VERSION ""

NS_ :

BS_:

BU_: External_Tool CADM LRRF MRRRL MRRRR

BO_ 1283 MRR_RL_Detection_022_028: 64 MRRRL
 SG_ MRR_RL_CAN_DET_MID_TARGET_028 : 462|1@0+ (1,0) [0|1] ""  CADM
 SG_ MRR_RL_CAN_DET_MID_TARGET_027 : 461|1@0+ (1,0) [0|1] ""  CADM
 SG_ MRR_RL_CAN_DET_MID_TARGET_026 : 460|1@0+ (1,0) [0|1] ""  CADM
 SG_ MRR_RL_CAN_DET_MID_TARGET_025 : 459|1@0+ (1,0) [0|1] ""  CADM
 SG_ MRR_RL_CAN_DET_MID_TARGET_024 : 458|1@0+ (1,0) [0|1] ""  CADM
 SG_ MRR_RL_CAN_DET_MID_TARGET_023 : 457|1@0+ (1,0) [0|1] ""  CADM
 SG_ MRR_RL_CAN_DET_MID_TARGET_022 : 456|1@0+ (1,0) [0|1] ""  CADM
 SG_ MRR_RL_CAN_DET_Near_TARGET_022 : 448|1@0+ (1,0) [0|1] ""  CADM
 SG_ MRR_RL_CAN_DET_Near_TARGET_023 : 449|1@0+ (1,0) [0|1] ""  CADM
 SG_ MRR_RL_CAN_DET_Near_TARGET_024 : 450|1@0+ (1,0) [0|1] ""  CADM
 SG_ MRR_RL_CAN_DET_Near_TARGET_025 : 451|1@0+ (1,0) [0|1] ""  CADM
 SG_ MRR_RL_CAN_DET_Near_TARGET_026 : 452|1@0+ (1,0) [0|1] ""  CADM
 SG_ MRR_RL_CAN_DET_Near_TARGET_027 : 453|1@0+ (1,0) [0|1] ""  CADM
 SG_ MRR_RL_CAN_DET_Near_TARGET_028 : 454|1@0+ (1,0) [0|1] ""  CADM
 SG_ MRR_RL_DET_CRC_004 : 503|16@0+ (1,0) [0|65535] ""  CADM
 SG_ MRR_RL_DET_MC_004 : 491|4@0+ (1,0) [0|15] ""  CADM
 SG_ MRR_RL_CAN_DET_SUPER_RES_TA_0035 : 440|1@0+ (1,0) [0|1] ""  CADM
 SG_ MRR_RL_CAN_DET_ELEVATION_028 : 447|7@0+ (0.002748,-0.1745) [-0.1745|0.174496] "rad"  CADM
 SG_ MRR_RL_CAN_DET_HOST_VEH_CLU_0035 : 432|1@0+ (1,0) [0|1] ""  CADM
 SG_ MRR_RL_CAN_DET_CONFID_ELEVA_0035 : 433|1@0+ (1,0) [0|1] ""  CADM
 SG_ MRR_RL_CAN_DET_AZIMUTH_028 : 431|14@0+ (0.0003834,-3.1416) [-3.1416|3.1396422] "rad"  CADM
 SG_ MRR_RL_CAN_DET_CONFID_AZIMU_0031 : 417|2@0+ (1,0) [0|3] ""  CADM
 SG_ MRR_RL_CAN_DET_RANGE_028 : 415|14@0+ (0.015625,0) [0|255.984375] "m"  CADM
 SG_ MRR_RL_CAN_SCAN_INDEX_2LSB_028 : 401|2@0+ (1,0) [0|3] ""  CADM
 SG_ MRR_RL_CAN_DET_RANGE_RATE_028 : 399|14@0+ (0.015625,-128) [-128|127.984375] "m/s"  CADM
 SG_ MRR_RL_CAN_DET_VALID_LEVEL_028 : 384|1@0+ (1,0) [0|1] ""  CADM
 SG_ MRR_RL_CAN_DET_AMPLITUDE_028 : 391|7@0+ (1,-64) [-64|63] "dBsm"  CADM
 SG_ MRR_RL_CAN_DET_SUPER_RES_TA_0036 : 376|1@0+ (1,0) [0|1] ""  CADM
 SG_ MRR_RL_CAN_DET_ELEVATION_027 : 383|7@0+ (0.002748,-0.1745) [-0.1745|0.174496] "rad"  CADM
 SG_ MRR_RL_CAN_DET_HOST_VEH_CLU_0036 : 368|1@0+ (1,0) [0|1] ""  CADM
 SG_ MRR_RL_CAN_DET_CONFID_ELEVA_0036 : 369|1@0+ (1,0) [0|1] ""  CADM
 SG_ MRR_RL_CAN_DET_AZIMUTH_027 : 367|14@0+ (0.0003834,-3.1416) [-3.1416|3.1396422] "rad"  CADM
 SG_ MRR_RL_CAN_DET_CONFID_AZIMU_0032 : 353|2@0+ (1,0) [0|3] ""  CADM
 SG_ MRR_RL_CAN_DET_RANGE_027 : 351|14@0+ (0.015625,0) [0|255.984375] "m"  CADM
 SG_ MRR_RL_CAN_SCAN_INDEX_2LSB_027 : 337|2@0+ (1,0) [0|3] ""  CADM
 SG_ MRR_RL_CAN_DET_RANGE_RATE_027 : 335|14@0+ (0.015625,-128) [-128|127.984375] "m/s"  CADM
 SG_ MRR_RL_CAN_DET_VALID_LEVEL_027 : 320|1@0+ (1,0) [0|1] ""  CADM
 SG_ MRR_RL_CAN_DET_AMPLITUDE_027 : 327|7@0+ (1,-64) [-64|63] "dBsm"  CADM
 SG_ MRR_RL_CAN_DET_SUPER_RES_TA_0037 : 312|1@0+ (1,0) [0|1] ""  CADM
 SG_ MRR_RL_CAN_DET_ELEVATION_026 : 319|7@0+ (0.002748,-0.1745) [-0.1745|0.174496] "rad"  CADM
 SG_ MRR_RL_CAN_DET_HOST_VEH_CLU_0037 : 304|1@0+ (1,0) [0|1] ""  CADM
 SG_ MRR_RL_CAN_DET_CONFID_ELEVA_0037 : 305|1@0+ (1,0) [0|1] ""  CADM
 SG_ MRR_RL_CAN_DET_AZIMUTH_026 : 303|14@0+ (0.0003834,-3.1416) [-3.1416|3.1396422] "rad"  CADM
 SG_ MRR_RL_CAN_DET_CONFID_AZIMU_0033 : 289|2@0+ (1,0) [0|3] ""  CADM
 SG_ MRR_RL_CAN_DET_RANGE_026 : 287|14@0+ (0.015625,0) [0|255.984375] "m"  CADM
 SG_ MRR_RL_CAN_SCAN_INDEX_2LSB_026 : 273|2@0+ (1,0) [0|3] ""  CADM
 SG_ MRR_RL_CAN_DET_RANGE_RATE_026 : 271|14@0+ (0.015625,-128) [-128|127.984375] "m/s"  CADM
 SG_ MRR_RL_CAN_DET_VALID_LEVEL_026 : 256|1@0+ (1,0) [0|1] ""  CADM
 SG_ MRR_RL_CAN_DET_AMPLITUDE_026 : 263|7@0+ (1,-64) [-64|63] "dBsm"  CADM
 SG_ MRR_RL_CAN_DET_SUPER_RES_TA_0038 : 248|1@0+ (1,0) [0|1] ""  CADM
 SG_ MRR_RL_CAN_DET_ELEVATION_025 : 255|7@0+ (0.002748,-0.1745) [-0.1745|0.174496] "rad"  CADM
 SG_ MRR_RL_CAN_DET_HOST_VEH_CLU_0038 : 240|1@0+ (1,0) [0|1] ""  CADM
 SG_ MRR_RL_CAN_DET_CONFID_ELEVA_0038 : 241|1@0+ (1,0) [0|1] ""  CADM
 SG_ MRR_RL_CAN_DET_AZIMUTH_025 : 239|14@0+ (0.0003834,-3.1416) [-3.1416|3.1396422] "rad"  CADM
 SG_ MRR_RL_CAN_DET_CONFID_AZIMU_0034 : 225|2@0+ (1,0) [0|3] ""  CADM
 SG_ MRR_RL_CAN_DET_RANGE_025 : 223|14@0+ (0.015625,0) [0|255.984375] "m"  CADM
 SG_ MRR_RL_CAN_SCAN_INDEX_2LSB_025 : 209|2@0+ (1,0) [0|3] ""  CADM
 SG_ MRR_RL_CAN_DET_RANGE_RATE_025 : 207|14@0+ (0.015625,-128) [-128|127.984375] "m/s"  CADM
 SG_ MRR_RL_CAN_DET_VALID_LEVEL_025 : 192|1@0+ (1,0) [0|1] ""  CADM
 SG_ MRR_RL_CAN_DET_AMPLITUDE_025 : 199|7@0+ (1,-64) [-64|63] "dBsm"  CADM
 SG_ MRR_RL_CAN_DET_SUPER_RES_TA_0039 : 184|1@0+ (1,0) [0|1] ""  CADM
 SG_ MRR_RL_CAN_DET_ELEVATION_024 : 191|7@0+ (0.002748,-0.1745) [-0.1745|0.174496] "rad"  CADM
 SG_ MRR_RL_CAN_DET_HOST_VEH_CLU_0039 : 176|1@0+ (1,0) [0|1] ""  CADM
 SG_ MRR_RL_CAN_DET_CONFID_ELEVA_0039 : 177|1@0+ (1,0) [0|1] ""  CADM
 SG_ MRR_RL_CAN_DET_AZIMUTH_024 : 175|14@0+ (0.0003834,-3.1416) [-3.1416|3.1396422] "rad"  CADM
 SG_ MRR_RL_CAN_DET_CONFID_AZIMU_0035 : 161|2@0+ (1,0) [0|3] ""  CADM
 SG_ MRR_RL_CAN_DET_RANGE_024 : 159|14@0+ (0.015625,0) [0|255.984375] "m"  CADM
 SG_ MRR_RL_CAN_SCAN_INDEX_2LSB_024 : 145|2@0+ (1,0) [0|3] ""  CADM
 SG_ MRR_RL_CAN_DET_RANGE_RATE_024 : 143|14@0+ (0.015625,-128) [-128|127.984375] "m/s"  CADM
 SG_ MRR_RL_CAN_DET_VALID_LEVEL_024 : 128|1@0+ (1,0) [0|1] ""  CADM
 SG_ MRR_RL_CAN_DET_AMPLITUDE_024 : 135|7@0+ (1,-64) [-64|63] "dBsm"  CADM
 SG_ MRR_RL_CAN_DET_SUPER_RES_TA_0040 : 120|1@0+ (1,0) [0|1] ""  CADM
 SG_ MRR_RL_CAN_DET_ELEVATION_023 : 127|7@0+ (0.002748,-0.1745) [-0.1745|0.174496] "rad"  CADM
 SG_ MRR_RL_CAN_DET_HOST_VEH_CLU_0040 : 112|1@0+ (1,0) [0|1] ""  CADM
 SG_ MRR_RL_CAN_DET_CONFID_ELEVA_0040 : 113|1@0+ (1,0) [0|1] ""  CADM
 SG_ MRR_RL_CAN_DET_AZIMUTH_023 : 111|14@0+ (0.0003834,-3.1416) [-3.1416|3.1396422] "rad"  CADM
 SG_ MRR_RL_CAN_DET_CONFID_AZIMU_0036 : 97|2@0+ (1,0) [0|3] ""  CADM
 SG_ MRR_RL_CAN_DET_RANGE_023 : 95|14@0+ (0.015625,0) [0|255.984375] "m"  CADM
 SG_ MRR_RL_CAN_SCAN_INDEX_2LSB_023 : 81|2@0+ (1,0) [0|3] ""  CADM
 SG_ MRR_RL_CAN_DET_RANGE_RATE_023 : 79|14@0+ (0.015625,-128) [-128|127.984375] "m/s"  CADM
 SG_ MRR_RL_CAN_DET_VALID_LEVEL_023 : 64|1@0+ (1,0) [0|1] ""  CADM
 SG_ MRR_RL_CAN_DET_AMPLITUDE_023 : 71|7@0+ (1,-64) [-64|63] "dBsm"  CADM
 SG_ MRR_RL_CAN_DET_SUPER_RES_TA_0041 : 56|1@0+ (1,0) [0|1] ""  CADM
 SG_ MRR_RL_CAN_DET_ELEVATION_022 : 63|7@0+ (0.002748,-0.1745) [-0.1745|0.174496] "rad"  CADM
 SG_ MRR_RL_CAN_DET_HOST_VEH_CLU_0041 : 48|1@0+ (1,0) [0|1] ""  CADM
 SG_ MRR_RL_CAN_DET_CONFID_ELEVA_0041 : 49|1@0+ (1,0) [0|1] ""  CADM
 SG_ MRR_RL_CAN_DET_AZIMUTH_022 : 47|14@0+ (0.0003834,-3.1416) [-3.1416|3.1396422] "rad"  CADM
 SG_ MRR_RL_CAN_DET_CONFID_AZIMU_0037 : 33|2@0+ (1,0) [0|3] ""  CADM
 SG_ MRR_RL_CAN_DET_RANGE_022 : 31|14@0+ (0.015625,0) [0|255.984375] "m"  CADM
 SG_ MRR_RL_CAN_SCAN_INDEX_2LSB_022 : 17|2@0+ (1,0) [0|3] ""  CADM
 SG_ MRR_RL_CAN_DET_RANGE_RATE_022 : 15|14@0+ (0.015625,-128) [-128|127.984375] "m/s"  CADM
 SG_ MRR_RL_CAN_DET_VALID_LEVEL_022 : 0|1@0+ (1,0) [0|1] ""  CADM
 SG_ MRR_RL_CAN_DET_AMPLITUDE_022 : 7|7@0+ (1,-64) [-64|63] "dBsm"  CADM

BO_ 1282 MRR_RL_Detection_015_021: 64 MRRRL
 SG_ MRR_RL_CAN_DET_MID_TARGET_021 : 462|1@0+ (1,0) [0|1] ""  CADM
 SG_ MRR_RL_CAN_DET_MID_TARGET_020 : 461|1@0+ (1,0) [0|1] ""  CADM
 SG_ MRR_RL_CAN_DET_MID_TARGET_019 : 460|1@0+ (1,0) [0|1] ""  CADM
 SG_ MRR_RL_CAN_DET_MID_TARGET_018 : 459|1@0+ (1,0) [0|1] ""  CADM
 SG_ MRR_RL_CAN_DET_MID_TARGET_017 : 458|1@0+ (1,0) [0|1] ""  CADM
 SG_ MRR_RL_CAN_DET_MID_TARGET_016 : 457|1@0+ (1,0) [0|1] ""  CADM
 SG_ MRR_RL_CAN_DET_MID_TARGET_015 : 456|1@0+ (1,0) [0|1] ""  CADM
 SG_ MRR_RL_CAN_DET_Near_TARGET_015 : 448|1@0+ (1,0) [0|1] ""  CADM
 SG_ MRR_RL_CAN_DET_Near_TARGET_016 : 449|1@0+ (1,0) [0|1] ""  CADM
 SG_ MRR_RL_CAN_DET_Near_TARGET_017 : 450|1@0+ (1,0) [0|1] ""  CADM
 SG_ MRR_RL_CAN_DET_Near_TARGET_018 : 451|1@0+ (1,0) [0|1] ""  CADM
 SG_ MRR_RL_CAN_DET_Near_TARGET_019 : 452|1@0+ (1,0) [0|1] ""  CADM
 SG_ MRR_RL_CAN_DET_Near_TARGET_020 : 453|1@0+ (1,0) [0|1] ""  CADM
 SG_ MRR_RL_CAN_DET_Near_TARGET_021 : 454|1@0+ (1,0) [0|1] ""  CADM
 SG_ MRR_RL_CAN_DET_AMPLITUDE_019 : 263|7@0+ (1,-64) [-64|63] "dBsm"  CADM
 SG_ MRR_RL_DET_CRC_003 : 503|16@0+ (1,0) [0|65535] ""  CADM
 SG_ MRR_RL_DET_MC_003 : 491|4@0+ (1,0) [0|15] ""  CADM
 SG_ MRR_RL_CAN_DET_SUPER_RES_TA_0042 : 440|1@0+ (1,0) [0|1] ""  CADM
 SG_ MRR_RL_CAN_DET_ELEVATION_021 : 447|7@0+ (0.002748,-0.1745) [-0.1745|0.174496] "rad"  CADM
 SG_ MRR_RL_CAN_DET_HOST_VEH_CLU_0042 : 432|1@0+ (1,0) [0|1] ""  CADM
 SG_ MRR_RL_CAN_DET_CONFID_ELEVA_0042 : 433|1@0+ (1,0) [0|1] ""  CADM
 SG_ MRR_RL_CAN_DET_AZIMUTH_021 : 431|14@0+ (0.0003834,-3.1416) [-3.1416|3.1396422] "rad"  CADM
 SG_ MRR_RL_CAN_DET_CONFID_AZIMU_0038 : 417|2@0+ (1,0) [0|3] ""  CADM
 SG_ MRR_RL_CAN_DET_RANGE_021 : 415|14@0+ (0.015625,0) [0|255.984375] "m"  CADM
 SG_ MRR_RL_CAN_SCAN_INDEX_2LSB_021 : 401|2@0+ (1,0) [0|3] ""  CADM
 SG_ MRR_RL_CAN_DET_RANGE_RATE_021 : 399|14@0+ (0.015625,-128) [-128|127.984375] "m/s"  CADM
 SG_ MRR_RL_CAN_DET_VALID_LEVEL_021 : 384|1@0+ (1,0) [0|1] ""  CADM
 SG_ MRR_RL_CAN_DET_AMPLITUDE_021 : 391|7@0+ (1,-64) [-64|63] "dBsm"  CADM
 SG_ MRR_RL_CAN_DET_SUPER_RES_TA_0043 : 376|1@0+ (1,0) [0|1] ""  CADM
 SG_ MRR_RL_CAN_DET_ELEVATION_020 : 383|7@0+ (0.002748,-0.1745) [-0.1745|0.174496] "rad"  CADM
 SG_ MRR_RL_CAN_DET_HOST_VEH_CLU_0043 : 368|1@0+ (1,0) [0|1] ""  CADM
 SG_ MRR_RL_CAN_DET_CONFID_ELEVA_0043 : 369|1@0+ (1,0) [0|1] ""  CADM
 SG_ MRR_RL_CAN_DET_AZIMUTH_020 : 367|14@0+ (0.0003834,-3.1416) [-3.1416|3.1396422] "rad"  CADM
 SG_ MRR_RL_CAN_DET_CONFID_AZIMU_0039 : 353|2@0+ (1,0) [0|3] ""  CADM
 SG_ MRR_RL_CAN_DET_RANGE_020 : 351|14@0+ (0.015625,0) [0|255.984375] "m"  CADM
 SG_ MRR_RL_CAN_SCAN_INDEX_2LSB_020 : 337|2@0+ (1,0) [0|3] ""  CADM
 SG_ MRR_RL_CAN_DET_RANGE_RATE_020 : 335|14@0+ (0.015625,-128) [-128|127.984375] "m/s"  CADM
 SG_ MRR_RL_CAN_DET_VALID_LEVEL_020 : 320|1@0+ (1,0) [0|1] ""  CADM
 SG_ MRR_RL_CAN_DET_AMPLITUDE_020 : 327|7@0+ (1,-64) [-64|63] "dBsm"  CADM
 SG_ MRR_RL_CAN_DET_SUPER_RES_TA_0044 : 312|1@0+ (1,0) [0|1] ""  CADM
 SG_ MRR_RL_CAN_DET_ELEVATION_019 : 319|7@0+ (0.002748,-0.1745) [-0.1745|0.174496] "rad"  CADM
 SG_ MRR_RL_CAN_DET_HOST_VEH_CLU_0044 : 304|1@0+ (1,0) [0|1] ""  CADM
 SG_ MRR_RL_CAN_DET_CONFID_ELEVA_0044 : 305|1@0+ (1,0) [0|1] ""  CADM
 SG_ MRR_RL_CAN_DET_AZIMUTH_019 : 303|14@0+ (0.0003834,-3.1416) [-3.1416|3.1396422] "rad"  CADM
 SG_ MRR_RL_CAN_DET_CONFID_AZIMUTH_01 : 289|2@0+ (1,0) [0|3] ""  CADM
 SG_ MRR_RL_CAN_DET_RANGE_019 : 287|14@0+ (0.015625,0) [0|255.984375] "m"  CADM
 SG_ MRR_RL_CAN_SCAN_INDEX_2LSB_019 : 273|2@0+ (1,0) [0|3] ""  CADM
 SG_ MRR_RL_CAN_DET_RANGE_RATE_019 : 271|14@0+ (0.015625,-128) [-128|127.984375] "m/s"  CADM
 SG_ MRR_RL_CAN_DET_VALID_LEVEL_019 : 256|1@0+ (1,0) [0|1] ""  CADM
 SG_ MRR_RL_CAN_DET_SUPER_RES_TA_0045 : 248|1@0+ (1,0) [0|1] ""  CADM
 SG_ MRR_RL_CAN_DET_ELEVATION_018 : 255|7@0+ (0.002748,-0.1745) [-0.1745|0.174496] "rad"  CADM
 SG_ MRR_RL_CAN_DET_HOST_VEH_CLU_0045 : 240|1@0+ (1,0) [0|1] ""  CADM
 SG_ MRR_RL_CAN_DET_CONFID_ELEVA_0045 : 241|1@0+ (1,0) [0|1] ""  CADM
 SG_ MRR_RL_CAN_DET_AZIMUTH_018 : 239|14@0+ (0.0003834,-3.1416) [-3.1416|3.1396422] "rad"  CADM
 SG_ MRR_RL_CAN_DET_CONFID_AZIMU_0040 : 225|2@0+ (1,0) [0|3] ""  CADM
 SG_ MRR_RL_CAN_DET_RANGE_018 : 223|14@0+ (0.015625,0) [0|255.984375] "m"  CADM
 SG_ MRR_RL_CAN_SCAN_INDEX_2LSB_018 : 209|2@0+ (1,0) [0|3] ""  CADM
 SG_ MRR_RL_CAN_DET_RANGE_RATE_018 : 207|14@0+ (0.015625,-128) [-128|127.984375] "m/s"  CADM
 SG_ MRR_RL_CAN_DET_VALID_LEVEL_018 : 192|1@0+ (1,0) [0|1] ""  CADM
 SG_ MRR_RL_CAN_DET_AMPLITUDE_018 : 199|7@0+ (1,-64) [-64|63] "dBsm"  CADM
 SG_ MRR_RL_CAN_DET_SUPER_RES_TA_0046 : 184|1@0+ (1,0) [0|1] ""  CADM
 SG_ MRR_RL_CAN_DET_ELEVATION_017 : 191|7@0+ (0.002748,-0.1745) [-0.1745|0.174496] "rad"  CADM
 SG_ MRR_RL_CAN_DET_HOST_VEH_CLU_0046 : 176|1@0+ (1,0) [0|1] ""  CADM
 SG_ MRR_RL_CAN_DET_CONFID_ELEVA_0046 : 177|1@0+ (1,0) [0|1] ""  CADM
 SG_ MRR_RL_CAN_DET_AZIMUTH_017 : 175|14@0+ (0.0003834,-3.1416) [-3.1416|3.1396422] "rad"  CADM
 SG_ MRR_RL_CAN_DET_CONFID_AZIMU_0041 : 161|2@0+ (1,0) [0|3] ""  CADM
 SG_ MRR_RL_CAN_DET_RANGE_017 : 159|14@0+ (0.015625,0) [0|255.984375] "m"  CADM
 SG_ MRR_RL_CAN_SCAN_INDEX_2LSB_017 : 145|2@0+ (1,0) [0|3] ""  CADM
 SG_ MRR_RL_CAN_DET_RANGE_RATE_017 : 143|14@0+ (0.015625,-128) [-128|127.984375] "m/s"  CADM
 SG_ MRR_RL_CAN_DET_VALID_LEVEL_017 : 128|1@0+ (1,0) [0|1] ""  CADM
 SG_ MRR_RL_CAN_DET_AMPLITUDE_017 : 135|7@0+ (1,-64) [-64|63] "dBsm"  CADM
 SG_ MRR_RL_CAN_DET_SUPER_RES_TA_0047 : 120|1@0+ (1,0) [0|1] ""  CADM
 SG_ MRR_RL_CAN_DET_ELEVATION_016 : 127|7@0+ (0.002748,-0.1745) [-0.1745|0.174496] "rad"  CADM
 SG_ MRR_RL_CAN_DET_HOST_VEH_CLU_0047 : 112|1@0+ (1,0) [0|1] ""  CADM
 SG_ MRR_RL_CAN_DET_CONFID_ELEVA_0047 : 113|1@0+ (1,0) [0|1] ""  CADM
 SG_ MRR_RL_CAN_DET_AZIMUTH_016 : 111|14@0+ (0.0003834,-3.1416) [-3.1416|3.1396422] "rad"  CADM
 SG_ MRR_RL_CAN_DET_CONFID_AZIMU_0042 : 97|2@0+ (1,0) [0|3] ""  CADM
 SG_ MRR_RL_CAN_DET_RANGE_016 : 95|14@0+ (0.015625,0) [0|255.984375] "m"  CADM
 SG_ MRR_RL_CAN_SCAN_INDEX_2LSB_016 : 81|2@0+ (1,0) [0|3] ""  CADM
 SG_ MRR_RL_CAN_DET_RANGE_RATE_016 : 79|14@0+ (0.015625,-128) [-128|127.984375] "m/s"  CADM
 SG_ MRR_RL_CAN_DET_VALID_LEVEL_016 : 64|1@0+ (1,0) [0|1] ""  CADM
 SG_ MRR_RL_CAN_DET_AMPLITUDE_016 : 71|7@0+ (1,-64) [-64|63] "dBsm"  CADM
 SG_ MRR_RL_CAN_DET_SUPER_RES_TA_0048 : 56|1@0+ (1,0) [0|1] ""  CADM
 SG_ MRR_RL_CAN_DET_ELEVATION_015 : 63|7@0+ (0.002748,-0.1745) [-0.1745|0.174496] "rad"  CADM
 SG_ MRR_RL_CAN_DET_HOST_VEH_CLU_0048 : 48|1@0+ (1,0) [0|1] ""  CADM
 SG_ MRR_RL_CAN_DET_CONFID_ELEVA_0048 : 49|1@0+ (1,0) [0|1] ""  CADM
 SG_ MRR_RL_CAN_DET_AZIMUTH_015 : 47|14@0+ (0.0003834,-3.1416) [-3.1416|3.1396422] "rad"  CADM
 SG_ MRR_RL_CAN_DET_CONFID_AZIMU_0043 : 33|2@0+ (1,0) [0|3] ""  CADM
 SG_ MRR_RL_CAN_DET_RANGE_015 : 31|14@0+ (0.015625,0) [0|255.984375] "m"  CADM
 SG_ MRR_RL_CAN_SCAN_INDEX_2LSB_015 : 17|2@0+ (1,0) [0|3] ""  CADM
 SG_ MRR_RL_CAN_DET_RANGE_RATE_015 : 15|14@0+ (0.015625,-128) [-128|127.984375] "m/s"  CADM
 SG_ MRR_RL_CAN_DET_VALID_LEVEL_015 : 0|1@0+ (1,0) [0|1] ""  CADM
 SG_ MRR_RL_CAN_DET_AMPLITUDE_015 : 7|7@0+ (1,-64) [-64|63] "dBsm"  CADM

BO_ 1281 MRR_RL_Detection_008_014: 64 MRRRL
 SG_ MRR_RL_CAN_DET_MID_TARGET_014 : 462|1@0+ (1,0) [0|1] ""  CADM
 SG_ MRR_RL_CAN_DET_MID_TARGET_013 : 461|1@0+ (1,0) [0|1] ""  CADM
 SG_ MRR_RL_CAN_DET_MID_TARGET_012 : 460|1@0+ (1,0) [0|1] ""  CADM
 SG_ MRR_RL_CAN_DET_MID_TARGET_011 : 459|1@0+ (1,0) [0|1] ""  CADM
 SG_ MRR_RL_CAN_DET_MID_TARGET_010 : 458|1@0+ (1,0) [0|1] ""  CADM
 SG_ MRR_RL_CAN_DET_MID_TARGET_009 : 457|1@0+ (1,0) [0|1] ""  CADM
 SG_ MRR_RL_CAN_DET_MID_TARGET_008 : 456|1@0+ (1,0) [0|1] ""  CADM
 SG_ MRR_RL_CAN_DET_Near_TARGET_008 : 448|1@0+ (1,0) [0|1] ""  CADM
 SG_ MRR_RL_CAN_DET_Near_TARGET_009 : 449|1@0+ (1,0) [0|1] ""  CADM
 SG_ MRR_RL_CAN_DET_Near_TARGET_010 : 450|1@0+ (1,0) [0|1] ""  CADM
 SG_ MRR_RL_CAN_DET_Near_TARGET_011 : 451|1@0+ (1,0) [0|1] ""  CADM
 SG_ MRR_RL_CAN_DET_Near_TARGET_012 : 452|1@0+ (1,0) [0|1] ""  CADM
 SG_ MRR_RL_CAN_DET_Near_TARGET_013 : 453|1@0+ (1,0) [0|1] ""  CADM
 SG_ MRR_RL_CAN_DET_Near_TARGET_014 : 454|1@0+ (1,0) [0|1] ""  CADM
 SG_ MRR_RL_DET_CRC_002 : 503|16@0+ (1,0) [0|65535] ""  CADM
 SG_ MRR_RL_DET_MC_002 : 491|4@0+ (1,0) [0|15] ""  CADM
 SG_ MRR_RL_CAN_DET_SUPER_RES_TA_0049 : 440|1@0+ (1,0) [0|1] ""  CADM
 SG_ MRR_RL_CAN_DET_ELEVATION_014 : 447|7@0+ (0.002748,-0.1745) [-0.1745|0.174496] "rad"  CADM
 SG_ MRR_RL_CAN_DET_HOST_VEH_CLU_0049 : 432|1@0+ (1,0) [0|1] ""  CADM
 SG_ MRR_RL_CAN_DET_CONFID_ELEVA_0049 : 433|1@0+ (1,0) [0|1] ""  CADM
 SG_ MRR_RL_CAN_DET_AZIMUTH_014 : 431|14@0+ (0.0003834,-3.1416) [-3.1416|3.1396422] "rad"  CADM
 SG_ MRR_RL_CAN_DET_CONFID_AZIMU_0044 : 417|2@0+ (1,0) [0|3] ""  CADM
 SG_ MRR_RL_CAN_DET_RANGE_014 : 415|14@0+ (0.015625,0) [0|255.984375] "m"  CADM
 SG_ MRR_RL_CAN_SCAN_INDEX_2LSB_014 : 401|2@0+ (1,0) [0|3] ""  CADM
 SG_ MRR_RL_CAN_DET_RANGE_RATE_014 : 399|14@0+ (0.015625,-128) [-128|127.984375] "m/s"  CADM
 SG_ MRR_RL_CAN_DET_VALID_LEVEL_014 : 384|1@0+ (1,0) [0|1] ""  CADM
 SG_ MRR_RL_CAN_DET_AMPLITUDE_014 : 391|7@0+ (1,-64) [-64|63] "dBsm"  CADM
 SG_ MRR_RL_CAN_DET_SUPER_RES_TA_0050 : 376|1@0+ (1,0) [0|1] ""  CADM
 SG_ MRR_RL_CAN_DET_ELEVATION_013 : 383|7@0+ (0.002748,-0.1745) [-0.1745|0.174496] "rad"  CADM
 SG_ MRR_RL_CAN_DET_HOST_VEH_CLU_0050 : 368|1@0+ (1,0) [0|1] ""  CADM
 SG_ MRR_RL_CAN_DET_CONFID_ELEVA_0050 : 369|1@0+ (1,0) [0|1] ""  CADM
 SG_ MRR_RL_CAN_DET_AZIMUTH_013 : 367|14@0+ (0.0003834,-3.1416) [-3.1416|3.1396422] "rad"  CADM
 SG_ MRR_RL_CAN_DET_CONFID_AZIMU_0045 : 353|2@0+ (1,0) [0|3] ""  CADM
 SG_ MRR_RL_CAN_DET_RANGE_013 : 351|14@0+ (0.015625,0) [0|255.984375] "m"  CADM
 SG_ MRR_RL_CAN_SCAN_INDEX_2LSB_013 : 337|2@0+ (1,0) [0|3] ""  CADM
 SG_ MRR_RL_CAN_DET_RANGE_RATE_013 : 335|14@0+ (0.015625,-128) [-128|127.984375] "m/s"  CADM
 SG_ MRR_RL_CAN_DET_VALID_LEVEL_013 : 320|1@0+ (1,0) [0|1] ""  CADM
 SG_ MRR_RL_CAN_DET_AMPLITUDE_013 : 327|7@0+ (1,-64) [-64|63] "dBsm"  CADM
 SG_ MRR_RL_CAN_DET_SUPER_RES_TA_0051 : 312|1@0+ (1,0) [0|1] ""  CADM
 SG_ MRR_RL_CAN_DET_ELEVATION_012 : 319|7@0+ (0.002748,-0.1745) [-0.1745|0.174496] "rad"  CADM
 SG_ MRR_RL_CAN_DET_HOST_VEH_CLU_0051 : 304|1@0+ (1,0) [0|1] ""  CADM
 SG_ MRR_RL_CAN_DET_CONFID_ELEVA_0051 : 305|1@0+ (1,0) [0|1] ""  CADM
 SG_ MRR_RL_CAN_DET_AZIMUTH_012 : 303|14@0+ (0.0003834,-3.1416) [-3.1416|3.1396422] "rad"  CADM
 SG_ MRR_RL_CAN_DET_CONFID_AZIMU_0046 : 289|2@0+ (1,0) [0|3] ""  CADM
 SG_ MRR_RL_CAN_DET_RANGE_012 : 287|14@0+ (0.015625,0) [0|255.984375] "m"  CADM
 SG_ MRR_RL_CAN_SCAN_INDEX_2LSB_012 : 273|2@0+ (1,0) [0|3] ""  CADM
 SG_ MRR_RL_CAN_DET_RANGE_RATE_012 : 271|14@0+ (0.015625,-128) [-128|127.984375] "m/s"  CADM
 SG_ MRR_RL_CAN_DET_VALID_LEVEL_012 : 256|1@0+ (1,0) [0|1] ""  CADM
 SG_ MRR_RL_CAN_DET_AMPLITUDE_012 : 263|7@0+ (1,-64) [-64|63] "dBsm"  CADM
 SG_ MRR_RL_CAN_DET_SUPER_RES_TA_0052 : 248|1@0+ (1,0) [0|1] ""  CADM
 SG_ MRR_RL_CAN_DET_ELEVATION_011 : 255|7@0+ (0.002748,-0.1745) [-0.1745|0.174496] "rad"  CADM
 SG_ MRR_RL_CAN_DET_HOST_VEH_CLU_0052 : 240|1@0+ (1,0) [0|1] ""  CADM
 SG_ MRR_RL_CAN_DET_CONFID_ELEVA_0052 : 241|1@0+ (1,0) [0|1] ""  CADM
 SG_ MRR_RL_CAN_DET_AZIMUTH_011 : 239|14@0+ (0.0003834,-3.1416) [-3.1416|3.1396422] "rad"  CADM
 SG_ MRR_RL_CAN_DET_CONFID_AZIMU_0047 : 225|2@0+ (1,0) [0|3] ""  CADM
 SG_ MRR_RL_CAN_DET_RANGE_011 : 223|14@0+ (0.015625,0) [0|255.984375] "m"  CADM
 SG_ MRR_RL_CAN_SCAN_INDEX_2LSB_011 : 209|2@0+ (1,0) [0|3] ""  CADM
 SG_ MRR_RL_CAN_DET_RANGE_RATE_011 : 207|14@0+ (0.015625,-128) [-128|127.984375] "m/s"  CADM
 SG_ MRR_RL_CAN_DET_VALID_LEVEL_011 : 192|1@0+ (1,0) [0|1] ""  CADM
 SG_ MRR_RL_CAN_DET_AMPLITUDE_011 : 199|7@0+ (1,-64) [-64|63] "dBsm"  CADM
 SG_ MRR_RL_CAN_DET_SUPER_RES_TA_0053 : 184|1@0+ (1,0) [0|1] ""  CADM
 SG_ MRR_RL_CAN_DET_ELEVATION_010 : 191|7@0+ (0.002748,-0.1745) [-0.1745|0.174496] "rad"  CADM
 SG_ MRR_RL_CAN_DET_HOST_VEH_CLU_0053 : 176|1@0+ (1,0) [0|1] ""  CADM
 SG_ MRR_RL_CAN_DET_CONFID_ELEVA_0053 : 177|1@0+ (1,0) [0|1] ""  CADM
 SG_ MRR_RL_CAN_DET_AZIMUTH_010 : 175|14@0+ (0.0003834,-3.1416) [-3.1416|3.1396422] "rad"  CADM
 SG_ MRR_RL_CAN_DET_CONFID_AZIMU_0048 : 161|2@0+ (1,0) [0|3] ""  CADM
 SG_ MRR_RL_CAN_DET_RANGE_010 : 159|14@0+ (0.015625,0) [0|255.984375] "m"  CADM
 SG_ MRR_RL_CAN_SCAN_INDEX_2LSB_010 : 145|2@0+ (1,0) [0|3] ""  CADM
 SG_ MRR_RL_CAN_DET_RANGE_RATE_010 : 143|14@0+ (0.015625,-128) [-128|127.984375] "m/s"  CADM
 SG_ MRR_RL_CAN_DET_VALID_LEVEL_010 : 128|1@0+ (1,0) [0|1] ""  CADM
 SG_ MRR_RL_CAN_DET_AMPLITUDE_010 : 135|7@0+ (1,-64) [-64|63] "dBsm"  CADM
 SG_ MRR_RL_CAN_DET_SUPER_RES_TA_0054 : 120|1@0+ (1,0) [0|1] ""  CADM
 SG_ MRR_RL_CAN_DET_ELEVATION_009 : 127|7@0+ (0.002748,-0.1745) [-0.1745|0.174496] "rad"  CADM
 SG_ MRR_RL_CAN_DET_HOST_VEH_CLU_0054 : 112|1@0+ (1,0) [0|1] ""  CADM
 SG_ MRR_RL_CAN_DET_CONFID_ELEVA_0054 : 113|1@0+ (1,0) [0|1] ""  CADM
 SG_ MRR_RL_CAN_DET_AZIMUTH_009 : 111|14@0+ (0.0003834,-3.1416) [-3.1416|3.1396422] "rad"  CADM
 SG_ MRR_RL_CAN_DET_CONFID_AZIMUTH_00 : 97|2@0+ (1,0) [0|3] ""  CADM
 SG_ MRR_RL_CAN_DET_RANGE_009 : 95|14@0+ (0.015625,0) [0|255.984375] "m"  CADM
 SG_ MRR_RL_CAN_SCAN_INDEX_2LSB_009 : 81|2@0+ (1,0) [0|3] ""  CADM
 SG_ MRR_RL_CAN_DET_RANGE_RATE_009 : 79|14@0+ (0.015625,-128) [-128|127.984375] "m/s"  CADM
 SG_ MRR_RL_CAN_DET_VALID_LEVEL_009 : 64|1@0+ (1,0) [0|1] ""  CADM
 SG_ MRR_RL_CAN_DET_AMPLITUDE_009 : 71|7@0+ (1,-64) [-64|63] "dBsm"  CADM
 SG_ MRR_RL_CAN_DET_SUPER_RES_TA_0055 : 56|1@0+ (1,0) [0|1] ""  CADM
 SG_ MRR_RL_CAN_DET_ELEVATION_008 : 63|7@0+ (0.002748,-0.1745) [-0.1745|0.174496] "rad"  CADM
 SG_ MRR_RL_CAN_DET_HOST_VEH_CLU_0055 : 48|1@0+ (1,0) [0|1] ""  CADM
 SG_ MRR_RL_CAN_DET_CONFID_ELEVA_0055 : 49|1@0+ (1,0) [0|1] ""  CADM
 SG_ MRR_RL_CAN_DET_AZIMUTH_008 : 47|14@0+ (0.0003834,-3.1416) [-3.1416|3.1396422] "rad"  CADM
 SG_ MRR_RL_CAN_DET_CONFID_AZIMU_0049 : 33|2@0+ (1,0) [0|3] ""  CADM
 SG_ MRR_RL_CAN_DET_RANGE_008 : 31|14@0+ (0.015625,0) [0|255.984375] "m"  CADM
 SG_ MRR_RL_CAN_SCAN_INDEX_2LSB_008 : 17|2@0+ (1,0) [0|3] ""  CADM
 SG_ MRR_RL_CAN_DET_RANGE_RATE_008 : 15|14@0+ (0.015625,-128) [-128|127.984375] "m/s"  CADM
 SG_ MRR_RL_CAN_DET_VALID_LEVEL_008 : 0|1@0+ (1,0) [0|1] ""  CADM
 SG_ MRR_RL_CAN_DET_AMPLITUDE_008 : 7|7@0+ (1,-64) [-64|63] "dBsm"  CADM

BO_ 323 MRR_RL_Alignment_Status: 12 MRRRL
 SG_ MRR_RL_Alignment_Status_CRC : 87|16@0+ (1,0) [0|65535] ""  CADM
 SG_ MRR_RL_Alignment_Status_MC : 75|4@0+ (1,0) [0|15] ""  CADM
 SG_ MRR_RL_CAN_TX_Temperature : 63|8@0+ (1,-50) [-50|205] "degC"  CADM
 SG_ MRR_RL_CAN_TX_YAW_RATE_BIAS : 55|8@0- (0.125,0) [-16|15.875] ""  CADM
 SG_ MRR_RL_CAN_TX_VEH_SPD_COMP_FACTO : 47|6@0- (0.001953125,1) [0.9375|1.060546875] ""  CADM
 SG_ MRR_RL_CAN_TX_DRIVING_ENVIRONMEN : 41|2@0+ (1,0) [0|3] ""  CADM
 SG_ MRR_RL_CAN_TX_Alignment_MODE : 39|4@0+ (1,0) [0|15] ""  CADM
 SG_ MRR_RL_CAN_TX_AUTO_ALIGN_QUA_FAC : 35|2@0+ (1,0) [0|3] ""  CADM
 SG_ MRR_RL_CAN_TX_ROLLING_COUNT_1 : 33|2@0+ (1,0) [0|3] ""  CADM
 SG_ MRR_RL_CAN_TX_CURRENT_MISALIGN_A : 23|16@0- (0.0009765625,0) [-32|31.9990234375] "Deg"  CADM
 SG_ MRR_RL_CAN_TX_SAVED_MISALIGN_ANG : 7|16@0- (0.0009765625,0) [-32|31.9990234375] "Deg"  CADM

BO_ 1346 MRR_Radar_Cfg_Parameters: 64 CADM
 SG_ SensorCfg_MRRFR_AlignRngTolVert : 431|8@0- (0.1,0) [-8|8] "deg" Vector__XXX
 SG_ SensorCfg_MRRFL_AlignRngTolVert : 423|8@0- (0.1,0) [-8|8] "deg" Vector__XXX
 SG_ SensorCfg_MRRRR_AlignRngTolVert : 415|8@0- (0.1,0) [-8|8] "deg"  MRRRR,MRRRL
 SG_ SensorCfg_MRRRL_AlignRngTolVert : 407|8@0- (0.1,0) [-8|8] "deg"  MRRRR,MRRRL
 SG_ SensorCfg_MRRFR_AlignRngTolHorz : 399|8@0- (0.1,0) [-8|8] "deg" Vector__XXX
 SG_ SensorCfg_MRRFL_AlignRngTolHorz : 391|8@0- (0.1,0) [-8|8] "deg" Vector__XXX
 SG_ SensorCfg_MRRRR_AlignRngTolHorz : 383|8@0- (0.1,0) [-8|8] "deg"  MRRRR,MRRRL
 SG_ SensorCfg_MRRRL_AlignRngTolHorz : 375|8@0- (0.1,0) [-8|8] "deg"  MRRRR,MRRRL
 SG_ MRR_SENSR_CFG_CRC : 503|16@0+ (1,0) [0|65535] ""  MRRRL,MRRRR
 SG_ SensorCfg_MRRFR_Pitch : 251|20@0- (1.526E-005,0) [-6|6] "deg" Vector__XXX
 SG_ SensorCfg_MRRRR_Pitch : 211|20@0- (1.526E-005,0) [-6|6] "deg"  MRRRL,MRRRR
 SG_ SensorCfg_MRRFL_Pitch : 239|20@0- (1.526E-005,0) [-6|6] "deg" Vector__XXX
 SG_ SensorCfg_MRRRL_Pitch : 199|20@0- (1.526E-005,0) [-6|6] "deg"  MRRRL,MRRRR
 SG_ SensorCfg_MRRRL_LatPos : 7|16@0- (1,0) [-1000|1000] "mm"  MRRRL,MRRRR
 SG_ SensorCfg_MRRRR_LatPos : 23|16@0- (1,0) [-1000|1000] "mm"  MRRRL,MRRRR
 SG_ SensorCfg_MRRFL_LatPos : 39|16@0- (1,0) [-1000|1000] "mm" Vector__XXX
 SG_ SensorCfg_MRRFR_LatPos : 55|16@0- (1,0) [-1000|1000] "mm" Vector__XXX
 SG_ SensorCfg_MRRRL_LongPos : 71|16@0- (1,0) [-6300|0] "mm"  MRRRL,MRRRR
 SG_ SensorCfg_MRRRR_LongPos : 87|16@0- (1,0) [-6300|0] "mm"  MRRRL,MRRRR
 SG_ SensorCfg_MRRFL_LongPos : 103|16@0- (1,0) [-6300|0] "mm" Vector__XXX
 SG_ SensorCfg_MRRFR_LongPos : 119|16@0- (1,0) [-6300|0] "mm" Vector__XXX
 SG_ SensorCfg_MRRRL_VertPos : 135|16@0+ (1,0) [0|2550] "mm"  MRRRL,MRRRR
 SG_ SensorCfg_MRRRR_VertPos : 151|16@0+ (1,0) [0|2550] "mm"  MRRRL,MRRRR
 SG_ SensorCfg_MRRFL_VertPos : 167|16@0+ (1,0) [0|2550] "mm" Vector__XXX
 SG_ SensorCfg_MRRFR_VertPos : 183|16@0+ (1,0) [0|2550] "mm" Vector__XXX
 SG_ SensorCfg_MRRRL_Yaw : 279|16@0- (0.01,0) [-180|180] "deg"  MRRRL,MRRRR
 SG_ SensorCfg_MRRRR_Yaw : 295|16@0- (0.01,0) [-180|180] "deg"  MRRRL,MRRRR
 SG_ SensorCfg_MRRFL_Yaw : 311|16@0- (0.01,0) [-180|180] "deg" Vector__XXX
 SG_ SensorCfg_MRRFR_Yaw : 327|16@0- (0.01,0) [-180|180] "deg" Vector__XXX
 SG_ SensorCfg_MRRRL_Orientation : 343|8@0- (1,0) [-1|1] ""  MRRRL,MRRRR
 SG_ SensorCfg_MRRRR_Orientation : 351|8@0- (1,0) [-1|1] ""  MRRRL,MRRRR
 SG_ SensorCfg_MRRFL_Orientation : 359|8@0- (1,0) [-1|1] "" Vector__XXX
 SG_ SensorCfg_MRRFR_Orientation : 367|8@0- (1,0) [-1|1] "" Vector__XXX

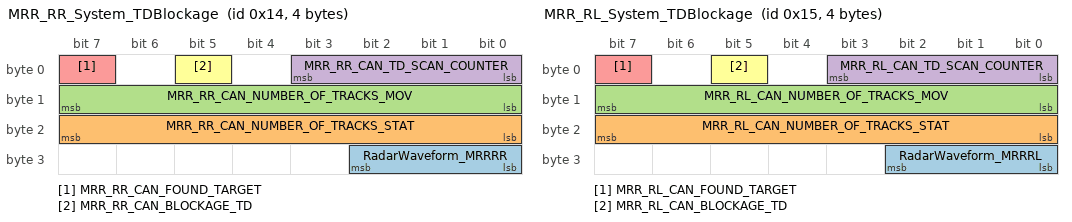
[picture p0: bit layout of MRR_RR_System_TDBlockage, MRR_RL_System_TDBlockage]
BO_ 20 MRR_RR_System_TDBlockage: 4 CADM
 SG_ RadarWaveform_MRRRR : 26|3@0+ (1,0) [0|7] ""  External_Tool,MRRRR
 SG_ MRR_RR_CAN_NUMBER_OF_TRACKS_STAT : 23|8@0+ (1,0) [0|255] ""  MRRRR,External_Tool
 SG_ MRR_RR_CAN_NUMBER_OF_TRACKS_MOV : 15|8@0+ (1,0) [0|255] ""  MRRRR,External_Tool
 SG_ MRR_RR_CAN_TD_SCAN_COUNTER : 3|4@0+ (1,0) [0|15] ""  External_Tool,MRRRR
 SG_ MRR_RR_CAN_FOUND_TARGET : 7|1@0+ (1,0) [0|1] ""  External_Tool,MRRRR
 SG_ MRR_RR_CAN_BLOCKAGE_TD : 5|1@0+ (1,0) [0|1] ""  External_Tool,MRRRR

BO_ 21 MRR_RL_System_TDBlockage: 4 CADM
 SG_ RadarWaveform_MRRRL : 26|3@0+ (1,0) [0|7] ""  External_Tool,MRRRL
 SG_ MRR_RL_CAN_NUMBER_OF_TRACKS_STAT : 23|8@0+ (1,0) [0|255] ""  MRRRL,External_Tool
 SG_ MRR_RL_CAN_NUMBER_OF_TRACKS_MOV : 15|8@0+ (1,0) [0|255] ""  MRRRL,External_Tool
 SG_ MRR_RL_CAN_TD_SCAN_COUNTER : 3|4@0+ (1,0) [0|15] ""  MRRRL,External_Tool
 SG_ MRR_RL_CAN_FOUND_TARGET : 7|1@0+ (1,0) [0|1] ""  MRRRL,External_Tool
 SG_ MRR_RL_CAN_BLOCKAGE_TD : 5|1@0+ (1,0) [0|1] ""  MRRRL,External_Tool

BO_ 18 MRR_RL_System_Control: 8 External_Tool
 SG_ MRR_RL_CAN_INST_MODE : 7|16@0+ (1,0) [0|65535] ""  MRRRL

BO_ 19 MRR_RR_System_Control: 8 External_Tool
 SG_ MRR_RR_CAN_INST_MODE : 7|16@0+ (1,0) [0|65535] ""  MRRRR

BO_ 1796 CADM_SWVersion: 12 CADM
 SG_ CAN_INTF_MINOR_VERSION : 74|3@0+ (1,0) [0|7] ""  LRRF,MRRRL,MRRRR
 SG_ CAN_INTF_MAJOR_VERSION : 79|5@0+ (1,0) [0|31] ""  LRRF,MRRRL,MRRRR
 SG_ CAN_PCAN_MINOR_CADM_HOST : 67|4@0+ (1,0) [0|15] ""  LRRF,MRRRL,MRRRR
 SG_ CAN_PCAN_MAJOR_CADM_HOST : 71|4@0+ (1,0) [0|15] ""  LRRF,MRRRL,MRRRR
 SG_ CADM_Field_Rev : 55|16@0+ (1,0) [0|65535] ""  LRRF,MRRRL,MRRRR
 SG_ CADM_SW_Promote_Rev : 39|16@0+ (1,0) [0|65535] ""  LRRF,MRRRL,MRRRR
 SG_ CADM_SW_Release_Rev : 23|16@0+ (1,0) [0|65535] ""  LRRF,MRRRL,MRRRR
 SG_ CAN_PCAN_MINOR_VER : 15|8@0+ (1,0) [0|255] ""  LRRF,MRRRL,MRRRR
 SG_ CAN_PCAN_MAJOR_VER : 7|8@0+ (1,0) [0|255] ""  LRRF,MRRRL,MRRRR

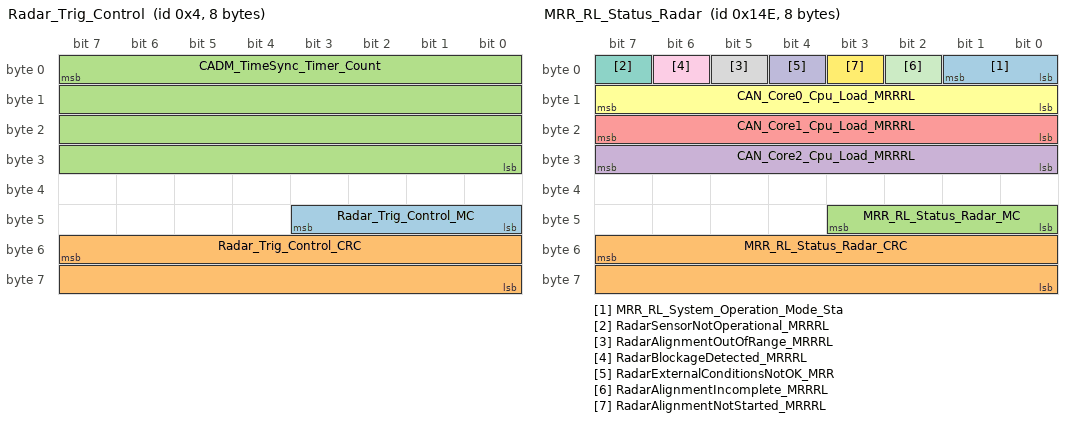
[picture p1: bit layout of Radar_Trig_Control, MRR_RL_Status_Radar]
BO_ 4 Radar_Trig_Control: 8 CADM
 SG_ Radar_Trig_Control_MC : 43|4@0+ (1,0) [0|15] ""  MRRRL,MRRRR,LRRF
 SG_ Radar_Trig_Control_CRC : 55|16@0+ (1,0) [0|65535] ""  MRRRL,MRRRR,LRRF
 SG_ CADM_TimeSync_Timer_Count : 7|32@0+ (1,0) [0|4294967295] "us"  LRRF,MRRRL,MRRRR

BO_ 334 MRR_RL_Status_Radar: 8 MRRRL
 SG_ MRR_RL_System_Operation_Mode_Sta : 1|2@0+ (1,0) [0|3] ""  CADM
 SG_ MRR_RL_Status_Radar_CRC : 55|16@0+ (1,0) [0|65535] ""  CADM
 SG_ MRR_RL_Status_Radar_MC : 43|4@0+ (1,0) [0|15] ""  CADM
 SG_ CAN_Core2_Cpu_Load_MRRRL : 31|8@0+ (0.5,0) [0|100] "%"  CADM
 SG_ CAN_Core1_Cpu_Load_MRRRL : 23|8@0+ (0.5,0) [0|100] "%"  CADM
 SG_ CAN_Core0_Cpu_Load_MRRRL : 15|8@0+ (0.5,0) [0|100] "%"  CADM
 SG_ RadarSensorNotOperational_MRRRL : 7|1@0+ (1,0) [0|1] ""  CADM
 SG_ RadarAlignmentOutOfRange_MRRRL : 5|1@0+ (1,0) [0|1] ""  CADM
 SG_ RadarBlockageDetected_MRRRL : 6|1@0+ (1,0) [0|1] ""  CADM
 SG_ RadarExternalConditionsNotOK_MRR : 4|1@0+ (1,0) [0|1] ""  CADM
 SG_ RadarAlignmentIncomplete_MRRRL : 2|1@0+ (1,0) [0|1] ""  CADM
 SG_ RadarAlignmentNotStarted_MRRRL : 3|1@0+ (1,0) [0|1] ""  CADM

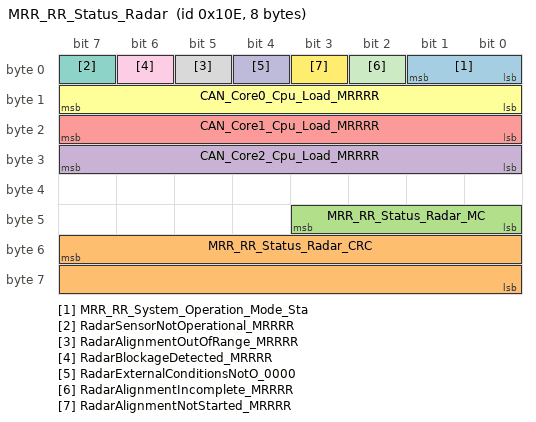
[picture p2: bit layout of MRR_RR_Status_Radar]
BO_ 270 MRR_RR_Status_Radar: 8 MRRRR
 SG_ MRR_RR_System_Operation_Mode_Sta : 1|2@0+ (1,0) [0|3] ""  CADM
 SG_ MRR_RR_Status_Radar_CRC : 55|16@0+ (1,0) [0|65535] ""  CADM
 SG_ MRR_RR_Status_Radar_MC : 43|4@0+ (1,0) [0|15] ""  CADM
 SG_ CAN_Core2_Cpu_Load_MRRRR : 31|8@0+ (0.5,0) [0|100] "%"  CADM
 SG_ CAN_Core1_Cpu_Load_MRRRR : 23|8@0+ (0.5,0) [0|100] "%"  CADM
 SG_ CAN_Core0_Cpu_Load_MRRRR : 15|8@0+ (0.5,0) [0|100] "%"  CADM
 SG_ RadarSensorNotOperational_MRRRR : 7|1@0+ (1,0) [0|1] ""  CADM
 SG_ RadarAlignmentOutOfRange_MRRRR : 5|1@0+ (1,0) [0|1] ""  CADM
 SG_ RadarBlockageDetected_MRRRR : 6|1@0+ (1,0) [0|1] ""  CADM
 SG_ RadarExternalConditionsNotO_0000 : 4|1@0+ (1,0) [0|1] ""  CADM
 SG_ RadarAlignmentIncomplete_MRRRR : 2|1@0+ (1,0) [0|1] ""  CADM
 SG_ RadarAlignmentNotStarted_MRRRR : 3|1@0+ (1,0) [0|1] ""  CADM

BO_ 1280 MRR_RL_Detection_001_007: 64 MRRRL
 SG_ MRR_RL_CAN_DET_MID_TARGET_007 : 462|1@0+ (1,0) [0|1] ""  CADM
 SG_ MRR_RL_CAN_DET_MID_TARGET_006 : 461|1@0+ (1,0) [0|1] ""  CADM
 SG_ MRR_RL_CAN_DET_MID_TARGET_005 : 460|1@0+ (1,0) [0|1] ""  CADM
 SG_ MRR_RL_CAN_DET_MID_TARGET_004 : 459|1@0+ (1,0) [0|1] ""  CADM
 SG_ MRR_RL_CAN_DET_MID_TARGET_003 : 458|1@0+ (1,0) [0|1] ""  CADM
 SG_ MRR_RL_CAN_DET_MID_TARGET_002 : 457|1@0+ (1,0) [0|1] ""  CADM
 SG_ MRR_RL_CAN_DET_MID_TARGET_001 : 456|1@0+ (1,0) [0|1] ""  CADM
 SG_ MRR_RL_CAN_DET_Near_TARGET_007 : 454|1@0+ (1,0) [0|1] ""  CADM
 SG_ MRR_RL_CAN_DET_Near_TARGET_006 : 453|1@0+ (1,0) [0|1] ""  CADM
 SG_ MRR_RL_CAN_DET_Near_TARGET_005 : 452|1@0+ (1,0) [0|1] ""  CADM
 SG_ MRR_RL_CAN_DET_Near_TARGET_004 : 451|1@0+ (1,0) [0|1] ""  CADM
 SG_ MRR_RL_CAN_DET_Near_TARGET_003 : 450|1@0+ (1,0) [0|1] ""  CADM
 SG_ MRR_RL_CAN_DET_Near_TARGET_002 : 449|1@0+ (1,0) [0|1] ""  CADM
 SG_ MRR_RL_CAN_DET_Near_TARGET_001 : 448|1@0+ (1,0) [0|1] ""  CADM
 SG_ MRR_RL_DET_CRC_001 : 503|16@0+ (1,0) [0|65535] ""  CADM
 SG_ MRR_RL_DET_MC_001 : 491|4@0+ (1,0) [0|15] ""  CADM
 SG_ MRR_RL_CAN_DET_SUPER_RES_TA_0056 : 440|1@0+ (1,0) [0|1] ""  CADM
 SG_ MRR_RL_CAN_DET_ELEVATION_007 : 447|7@0+ (0.002748,-0.1745) [-0.1745|0.174496] "rad"  CADM
 SG_ MRR_RL_CAN_DET_HOST_VEH_CLU_0056 : 432|1@0+ (1,0) [0|1] ""  CADM
 SG_ MRR_RL_CAN_DET_CONFID_ELEVA_0056 : 433|1@0+ (1,0) [0|1] ""  CADM
 SG_ MRR_RL_CAN_DET_AZIMUTH_007 : 431|14@0+ (0.0003834,-3.1416) [-3.1416|3.1396422] "rad"  CADM
 SG_ MRR_RL_CAN_DET_CONFID_AZIMU_0050 : 417|2@0+ (1,0) [0|3] ""  CADM
 SG_ MRR_RL_CAN_DET_RANGE_007 : 415|14@0+ (0.015625,0) [0|255.984375] "m"  CADM
 SG_ MRR_RL_CAN_SCAN_INDEX_2LSB_007 : 401|2@0+ (1,0) [0|3] ""  CADM
 SG_ MRR_RL_CAN_DET_RANGE_RATE_007 : 399|14@0+ (0.015625,-128) [-128|127.984375] "m/s"  CADM
 SG_ MRR_RL_CAN_DET_VALID_LEVEL_007 : 384|1@0+ (1,0) [0|1] ""  CADM
 SG_ MRR_RL_CAN_DET_AMPLITUDE_007 : 391|7@0+ (1,-64) [-64|63] "dBsm"  CADM
 SG_ MRR_RL_CAN_DET_SUPER_RES_TA_0057 : 376|1@0+ (1,0) [0|1] ""  CADM
 SG_ MRR_RL_CAN_DET_ELEVATION_006 : 383|7@0+ (0.002748,-0.1745) [-0.1745|0.174496] "rad"  CADM
 SG_ MRR_RL_CAN_DET_HOST_VEH_CLU_0057 : 368|1@0+ (1,0) [0|1] ""  CADM
 SG_ MRR_RL_CAN_DET_CONFID_ELEVA_0057 : 369|1@0+ (1,0) [0|1] ""  CADM
 SG_ MRR_RL_CAN_DET_AZIMUTH_006 : 367|14@0+ (0.0003834,-3.1416) [-3.1416|3.1396422] "rad"  CADM
 SG_ MRR_RL_CAN_DET_CONFID_AZIMU_0051 : 353|2@0+ (1,0) [0|3] ""  CADM
 SG_ MRR_RL_CAN_DET_RANGE_006 : 351|14@0+ (0.015625,0) [0|255.984375] "m"  CADM
 SG_ MRR_RL_CAN_SCAN_INDEX_2LSB_006 : 337|2@0+ (1,0) [0|3] ""  CADM
 SG_ MRR_RL_CAN_DET_RANGE_RATE_006 : 335|14@0+ (0.015625,-128) [-128|127.984375] "m/s"  CADM
 SG_ MRR_RL_CAN_DET_VALID_LEVEL_006 : 320|1@0+ (1,0) [0|1] ""  CADM
 SG_ MRR_RL_CAN_DET_AMPLITUDE_006 : 327|7@0+ (1,-64) [-64|63] "dBsm"  CADM
 SG_ MRR_RL_CAN_DET_SUPER_RES_TA_0058 : 312|1@0+ (1,0) [0|1] ""  CADM
 SG_ MRR_RL_CAN_DET_ELEVATION_005 : 319|7@0+ (0.002748,-0.1745) [-0.1745|0.174496] "rad"  CADM
 SG_ MRR_RL_CAN_DET_HOST_VEH_CLU_0058 : 304|1@0+ (1,0) [0|1] ""  CADM
 SG_ MRR_RL_CAN_DET_CONFID_ELEVA_0058 : 305|1@0+ (1,0) [0|1] ""  CADM
 SG_ MRR_RL_CAN_DET_AZIMUTH_005 : 303|14@0+ (0.0003834,-3.1416) [-3.1416|3.1396422] "rad"  CADM
 SG_ MRR_RL_CAN_DET_CONFID_AZIMU_0052 : 289|2@0+ (1,0) [0|3] ""  CADM
 SG_ MRR_RL_CAN_DET_RANGE_005 : 287|14@0+ (0.015625,0) [0|255.984375] "m"  CADM
 SG_ MRR_RL_CAN_SCAN_INDEX_2LSB_005 : 273|2@0+ (1,0) [0|3] ""  CADM
 SG_ MRR_RL_CAN_DET_RANGE_RATE_005 : 271|14@0+ (0.015625,-128) [-128|127.984375] "m/s"  CADM
 SG_ MRR_RL_CAN_DET_VALID_LEVEL_005 : 256|1@0+ (1,0) [0|1] ""  CADM
 SG_ MRR_RL_CAN_DET_AMPLITUDE_005 : 263|7@0+ (1,-64) [-64|63] "dBsm"  CADM
 SG_ MRR_RL_CAN_DET_SUPER_RES_TA_0059 : 248|1@0+ (1,0) [0|1] ""  CADM
 SG_ MRR_RL_CAN_DET_ELEVATION_004 : 255|7@0+ (0.002748,-0.1745) [-0.1745|0.174496] "rad"  CADM
 SG_ MRR_RL_CAN_DET_HOST_VEH_CLU_0059 : 240|1@0+ (1,0) [0|1] ""  CADM
 SG_ MRR_RL_CAN_DET_CONFID_ELEVA_0059 : 241|1@0+ (1,0) [0|1] ""  CADM
 SG_ MRR_RL_CAN_DET_AZIMUTH_004 : 239|14@0+ (0.0003834,-3.1416) [-3.1416|3.1396422] "rad"  CADM
 SG_ MRR_RL_CAN_DET_CONFID_AZIMU_0053 : 225|2@0+ (1,0) [0|3] ""  CADM
 SG_ MRR_RL_CAN_DET_RANGE_004 : 223|14@0+ (0.015625,0) [0|255.984375] "m"  CADM
 SG_ MRR_RL_CAN_SCAN_INDEX_2LSB_004 : 209|2@0+ (1,0) [0|3] ""  CADM
 SG_ MRR_RL_CAN_DET_RANGE_RATE_004 : 207|14@0+ (0.015625,-128) [-128|127.984375] "m/s"  CADM
 SG_ MRR_RL_CAN_DET_VALID_LEVEL_004 : 192|1@0+ (1,0) [0|1] ""  CADM
 SG_ MRR_RL_CAN_DET_AMPLITUDE_004 : 199|7@0+ (1,-64) [-64|63] "dBsm"  CADM
 SG_ MRR_RL_CAN_DET_SUPER_RES_TA_0060 : 184|1@0+ (1,0) [0|1] ""  CADM
 SG_ MRR_RL_CAN_DET_ELEVATION_003 : 191|7@0+ (0.002748,-0.1745) [-0.1745|0.174496] "rad"  CADM
 SG_ MRR_RL_CAN_DET_HOST_VEH_CLU_0060 : 176|1@0+ (1,0) [0|1] ""  CADM
 SG_ MRR_RL_CAN_DET_CONFID_ELEVA_0060 : 177|1@0+ (1,0) [0|1] ""  CADM
 SG_ MRR_RL_CAN_DET_AZIMUTH_003 : 175|14@0+ (0.0003834,-3.1416) [-3.1416|3.1396422] "rad"  CADM
 SG_ MRR_RL_CAN_DET_CONFID_AZIMU_0054 : 161|2@0+ (1,0) [0|3] ""  CADM
 SG_ MRR_RL_CAN_DET_RANGE_003 : 159|14@0+ (0.015625,0) [0|255.984375] "m"  CADM
 SG_ MRR_RL_CAN_SCAN_INDEX_2LSB_003 : 145|2@0+ (1,0) [0|3] ""  CADM
 SG_ MRR_RL_CAN_DET_RANGE_RATE_003 : 143|14@0+ (0.015625,-128) [-128|127.984375] "m/s"  CADM
 SG_ MRR_RL_CAN_DET_VALID_LEVEL_003 : 128|1@0+ (1,0) [0|1] ""  CADM
 SG_ MRR_RL_CAN_DET_AMPLITUDE_003 : 135|7@0+ (1,-64) [-64|63] "dBsm"  CADM
 SG_ MRR_RL_CAN_DET_SUPER_RES_TA_0061 : 120|1@0+ (1,0) [0|1] ""  CADM
 SG_ MRR_RL_CAN_DET_ELEVATION_002 : 127|7@0+ (0.002748,-0.1745) [-0.1745|0.174496] "rad"  CADM
 SG_ MRR_RL_CAN_DET_HOST_VEH_CLU_0061 : 112|1@0+ (1,0) [0|1] ""  CADM
 SG_ MRR_RL_CAN_DET_CONFID_ELEVA_0061 : 113|1@0+ (1,0) [0|1] ""  CADM
 SG_ MRR_RL_CAN_DET_AZIMUTH_002 : 111|14@0+ (0.0003834,-3.1416) [-3.1416|3.1396422] "rad"  CADM
 SG_ MRR_RL_CAN_DET_CONFID_AZIMU_0055 : 97|2@0+ (1,0) [0|3] ""  CADM
 SG_ MRR_RL_CAN_DET_RANGE_002 : 95|14@0+ (0.015625,0) [0|255.984375] "m"  CADM
 SG_ MRR_RL_CAN_SCAN_INDEX_2LSB_002 : 81|2@0+ (1,0) [0|3] ""  CADM
 SG_ MRR_RL_CAN_DET_RANGE_RATE_002 : 79|14@0+ (0.015625,-128) [-128|127.984375] "m/s"  CADM
 SG_ MRR_RL_CAN_DET_VALID_LEVEL_002 : 64|1@0+ (1,0) [0|1] ""  CADM
 SG_ MRR_RL_CAN_DET_AMPLITUDE_002 : 71|7@0+ (1,-64) [-64|63] "dBsm"  CADM
 SG_ MRR_RL_CAN_DET_ELEVATION_001 : 63|7@0+ (0.002748,-0.1745) [-0.1745|0.174496] "rad"  CADM
 SG_ MRR_RL_CAN_DET_SUPER_RES_TA_0062 : 56|1@0+ (1,0) [0|1] ""  CADM
 SG_ MRR_RL_CAN_DET_AZIMUTH_001 : 47|14@0+ (0.0003834,-3.1416) [-3.1416|3.1396422] "rad"  CADM
 SG_ MRR_RL_CAN_DET_CONFID_ELEVA_0062 : 49|1@0+ (1,0) [0|1] ""  CADM
 SG_ MRR_RL_CAN_DET_HOST_VEH_CLU_0062 : 48|1@0+ (1,0) [0|1] ""  CADM
 SG_ MRR_RL_CAN_DET_RANGE_001 : 31|14@0+ (0.015625,0) [0|255.984375] "m"  CADM
 SG_ MRR_RL_CAN_DET_CONFID_AZIMU_0056 : 33|2@0+ (1,0) [0|3] ""  CADM
 SG_ MRR_RL_CAN_DET_RANGE_RATE_001 : 15|14@0+ (0.015625,-128) [-128|127.984375] "m/s"  CADM
 SG_ MRR_RL_CAN_SCAN_INDEX_2LSB_001 : 17|2@0+ (1,0) [0|3] ""  CADM
 SG_ MRR_RL_CAN_DET_AMPLITUDE_001 : 7|7@0+ (1,-64) [-64|63] "dBsm"  CADM
 SG_ MRR_RL_CAN_DET_VALID_LEVEL_001 : 0|1@0+ (1,0) [0|1] ""  CADM

BO_ 1988 MRR_RL_Diag_Req_Phys: 64 CADM
 SG_ MRR_RL_Req_Phys : 7|64@0+ (1,0) [0|1.84467440737096E+019] ""  MRRRL

BO_ 1990 MRR_RR_Diag_Req_Phys: 64 CADM
 SG_ MRR_RR_Req_Phys : 7|64@0+ (1,0) [0|1.84467440737096E+019] ""  MRRRR

BO_ 1996 MRR_RL_Diag_Resp_Phys: 64 MRRRL
 SG_ MRR_RL_Resp_Phys : 7|64@0+ (1,0) [0|1.84467440737096E+019] ""  CADM

BO_ 1998 MRR_RR_Diag_Resp_Phys: 64 MRRRR
 SG_ MRR_RR_Resp_Phys : 7|64@0+ (1,0) [0|1.84467440737096E+019] ""  CADM

BO_ 2015 Diag_Req_Func: 64 CADM
 SG_ Diag_Req_Func : 7|64@0+ (1,0) [0|1.84467440737096E+019] ""  LRRF,MRRRL,MRRRR

BO_ 1268 MRR_RR_XCP_DAQ_Resp: 64 MRRRR
 SG_ MRR_RR_XCP_RESP_DAQ_Byte0 : 7|8@0+ (1,0) [0|255] ""  External_Tool
 SG_ MRR_RR_XCP_RESP_DAQ_Byte7 : 63|8@0+ (1,0) [0|255] ""  External_Tool
 SG_ MRR_RR_XCP_RESP_DAQ_Byte6 : 55|8@0+ (1,0) [0|255] ""  External_Tool
 SG_ MRR_RR_XCP_RESP_DAQ_Byte5 : 47|8@0+ (1,0) [0|255] ""  External_Tool
 SG_ MRR_RR_XCP_RESP_DAQ_Byte4 : 39|8@0+ (1,0) [0|255] ""  External_Tool
 SG_ MRR_RR_XCP_RESP_DAQ_Byte3 : 31|8@0+ (1,0) [0|255] ""  External_Tool
 SG_ MRR_RR_XCP_RESP_DAQ_Byte2 : 23|8@0+ (1,0) [0|255] ""  External_Tool
 SG_ MRR_RR_XCP_RESP_DAQ_Byte1 : 15|8@0+ (1,0) [0|255] ""  External_Tool
 SG_ MRR_RR_XCP_RESP_DAQ_Byte8 : 71|8@0+ (1,0) [0|255] ""  External_Tool
 SG_ MRR_RR_XCP_RESP_DAQ_Byte9 : 79|8@0+ (1,0) [0|255] ""  External_Tool
 SG_ MRR_RR_XCP_RESP_DAQ_Byte10 : 87|8@0+ (1,0) [0|255] ""  External_Tool
 SG_ MRR_RR_XCP_RESP_DAQ_Byte11 : 95|8@0+ (1,0) [0|255] ""  External_Tool
 SG_ MRR_RR_XCP_RESP_DAQ_Byte12 : 103|8@0+ (1,0) [0|255] ""  External_Tool
 SG_ MRR_RR_XCP_RESP_DAQ_Byte13 : 111|8@0+ (1,0) [0|255] ""  External_Tool
 SG_ MRR_RR_XCP_RESP_DAQ_Byte14 : 119|8@0+ (1,0) [0|255] ""  External_Tool
 SG_ MRR_RR_XCP_RESP_DAQ_Byte15 : 127|8@0+ (1,0) [0|255] ""  External_Tool
 SG_ MRR_RR_XCP_RESP_DAQ_Byte16 : 135|8@0+ (1,0) [0|255] ""  External_Tool
 SG_ MRR_RR_XCP_RESP_DAQ_Byte17 : 143|8@0+ (1,0) [0|255] ""  External_Tool
 SG_ MRR_RR_XCP_RESP_DAQ_Byte18 : 151|8@0+ (1,0) [0|255] ""  External_Tool
 SG_ MRR_RR_XCP_RESP_DAQ_Byte19 : 159|8@0+ (1,0) [0|255] ""  External_Tool
 SG_ MRR_RR_XCP_RESP_DAQ_Byte20 : 167|8@0+ (1,0) [0|255] ""  External_Tool
 SG_ MRR_RR_XCP_RESP_DAQ_Byte21 : 175|8@0+ (1,0) [0|255] ""  External_Tool
 SG_ MRR_RR_XCP_RESP_DAQ_Byte22 : 183|8@0+ (1,0) [0|255] ""  External_Tool
 SG_ MRR_RR_XCP_RESP_DAQ_Byte23 : 191|8@0+ (1,0) [0|255] ""  External_Tool
 SG_ MRR_RR_XCP_RESP_DAQ_Byte24 : 199|8@0+ (1,0) [0|255] ""  External_Tool
 SG_ MRR_RR_XCP_RESP_DAQ_Byte25 : 207|8@0+ (1,0) [0|255] ""  External_Tool
 SG_ MRR_RR_XCP_RESP_DAQ_Byte26 : 215|8@0+ (1,0) [0|255] ""  External_Tool
 SG_ MRR_RR_XCP_RESP_DAQ_Byte27 : 223|8@0+ (1,0) [0|255] ""  External_Tool
 SG_ MRR_RR_XCP_RESP_DAQ_Byte28 : 231|8@0+ (1,0) [0|255] ""  External_Tool
 SG_ MRR_RR_XCP_RESP_DAQ_Byte29 : 239|8@0+ (1,0) [0|255] ""  External_Tool
 SG_ MRR_RR_XCP_RESP_DAQ_Byte30 : 247|8@0+ (1,0) [0|255] ""  External_Tool
 SG_ MRR_RR_XCP_RESP_DAQ_Byte31 : 255|8@0+ (1,0) [0|255] ""  External_Tool
 SG_ MRR_RR_XCP_RESP_DAQ_Byte32 : 263|8@0+ (1,0) [0|255] ""  External_Tool
 SG_ MRR_RR_XCP_RESP_DAQ_Byte33 : 271|8@0+ (1,0) [0|255] ""  External_Tool
 SG_ MRR_RR_XCP_RESP_DAQ_Byte34 : 279|8@0+ (1,0) [0|255] ""  External_Tool
 SG_ MRR_RR_XCP_RESP_DAQ_Byte35 : 287|8@0+ (1,0) [0|255] ""  External_Tool
 SG_ MRR_RR_XCP_RESP_DAQ_Byte36 : 295|8@0+ (1,0) [0|255] ""  External_Tool
 SG_ MRR_RR_XCP_RESP_DAQ_Byte37 : 303|8@0+ (1,0) [0|255] ""  External_Tool
 SG_ MRR_RR_XCP_RESP_DAQ_Byte38 : 311|8@0+ (1,0) [0|255] ""  External_Tool
 SG_ MRR_RR_XCP_RESP_DAQ_Byte39 : 319|8@0+ (1,0) [0|255] ""  External_Tool
 SG_ MRR_RR_XCP_RESP_DAQ_Byte40 : 327|8@0+ (1,0) [0|255] ""  External_Tool
 SG_ MRR_RR_XCP_RESP_DAQ_Byte41 : 335|8@0+ (1,0) [0|255] ""  External_Tool
 SG_ MRR_RR_XCP_RESP_DAQ_Byte42 : 343|8@0+ (1,0) [0|255] ""  External_Tool
 SG_ MRR_RR_XCP_RESP_DAQ_Byte43 : 351|8@0+ (1,0) [0|255] ""  External_Tool
 SG_ MRR_RR_XCP_RESP_DAQ_Byte44 : 359|8@0+ (1,0) [0|255] ""  External_Tool
 SG_ MRR_RR_XCP_RESP_DAQ_Byte45 : 367|8@0+ (1,0) [0|255] ""  External_Tool
 SG_ MRR_RR_XCP_RESP_DAQ_Byte46 : 375|8@0+ (1,0) [0|255] ""  External_Tool
 SG_ MRR_RR_XCP_RESP_DAQ_Byte47 : 383|8@0+ (1,0) [0|255] ""  External_Tool
 SG_ MRR_RR_XCP_RESP_DAQ_Byte48 : 391|8@0+ (1,0) [0|255] ""  External_Tool
 SG_ MRR_RR_XCP_RESP_DAQ_Byte49 : 399|8@0+ (1,0) [0|255] ""  External_Tool
 SG_ MRR_RR_XCP_RESP_DAQ_Byte50 : 407|8@0+ (1,0) [0|255] ""  External_Tool
 SG_ MRR_RR_XCP_RESP_DAQ_Byte51 : 415|8@0+ (1,0) [0|255] ""  External_Tool
 SG_ MRR_RR_XCP_RESP_DAQ_Byte52 : 423|8@0+ (1,0) [0|255] ""  External_Tool
 SG_ MRR_RR_XCP_RESP_DAQ_Byte53 : 431|8@0+ (1,0) [0|255] ""  External_Tool
 SG_ MRR_RR_XCP_RESP_DAQ_Byte54 : 439|8@0+ (1,0) [0|255] ""  External_Tool
 SG_ MRR_RR_XCP_RESP_DAQ_Byte55 : 447|8@0+ (1,0) [0|255] ""  External_Tool
 SG_ MRR_RR_XCP_RESP_DAQ_Byte56 : 455|8@0+ (1,0) [0|255] ""  External_Tool
 SG_ MRR_RR_XCP_RESP_DAQ_Byte57 : 463|8@0+ (1,0) [0|255] ""  External_Tool
 SG_ MRR_RR_XCP_RESP_DAQ_Byte58 : 471|8@0+ (1,0) [0|255] ""  External_Tool
 SG_ MRR_RR_XCP_RESP_DAQ_Byte59 : 479|8@0+ (1,0) [0|255] ""  External_Tool
 SG_ MRR_RR_XCP_RESP_DAQ_Byte60 : 487|8@0+ (1,0) [0|255] ""  External_Tool
 SG_ MRR_RR_XCP_RESP_DAQ_Byte61 : 495|8@0+ (1,0) [0|255] ""  External_Tool
 SG_ MRR_RR_XCP_RESP_DAQ_Byte62 : 503|8@0+ (1,0) [0|255] ""  External_Tool
 SG_ MRR_RR_XCP_RESP_DAQ_Byte63 : 511|8@0+ (1,0) [0|255] ""  External_Tool

BO_ 1012 MRR_RL_XCP_DAQ_Resp: 64 MRRRL
 SG_ MRR_RL_XCP_RESP_DAQ_Byte0 : 7|8@0+ (1,0) [0|255] ""  External_Tool
 SG_ MRR_RL_XCP_RESP_DAQ_Byte7 : 63|8@0+ (1,0) [0|255] ""  External_Tool
 SG_ MRR_RL_XCP_RESP_DAQ_Byte6 : 55|8@0+ (1,0) [0|255] ""  External_Tool
 SG_ MRR_RL_XCP_RESP_DAQ_Byte5 : 47|8@0+ (1,0) [0|255] ""  External_Tool
 SG_ MRR_RL_XCP_RESP_DAQ_Byte4 : 39|8@0+ (1,0) [0|255] ""  External_Tool
 SG_ MRR_RL_XCP_RESP_DAQ_Byte3 : 31|8@0+ (1,0) [0|255] ""  External_Tool
 SG_ MRR_RL_XCP_RESP_DAQ_Byte2 : 23|8@0+ (1,0) [0|255] ""  External_Tool
 SG_ MRR_RL_XCP_RESP_DAQ_Byte1 : 15|8@0+ (1,0) [0|255] ""  External_Tool
 SG_ MRR_RL_XCP_RESP_DAQ_Byte8 : 71|8@0+ (1,0) [0|255] ""  External_Tool
 SG_ MRR_RL_XCP_RESP_DAQ_Byte9 : 79|8@0+ (1,0) [0|255] ""  External_Tool
 SG_ MRR_RL_XCP_RESP_DAQ_Byte10 : 87|8@0+ (1,0) [0|255] ""  External_Tool
 SG_ MRR_RL_XCP_RESP_DAQ_Byte11 : 95|8@0+ (1,0) [0|255] ""  External_Tool
 SG_ MRR_RL_XCP_RESP_DAQ_Byte12 : 103|8@0+ (1,0) [0|255] ""  External_Tool
 SG_ MRR_RL_XCP_RESP_DAQ_Byte13 : 111|8@0+ (1,0) [0|255] ""  External_Tool
 SG_ MRR_RL_XCP_RESP_DAQ_Byte14 : 119|8@0+ (1,0) [0|255] ""  External_Tool
 SG_ MRR_RL_XCP_RESP_DAQ_Byte15 : 127|8@0+ (1,0) [0|255] ""  External_Tool
 SG_ MRR_RL_XCP_RESP_DAQ_Byte16 : 135|8@0+ (1,0) [0|255] ""  External_Tool
 SG_ MRR_RL_XCP_RESP_DAQ_Byte17 : 143|8@0+ (1,0) [0|255] ""  External_Tool
 SG_ MRR_RL_XCP_RESP_DAQ_Byte18 : 151|8@0+ (1,0) [0|255] ""  External_Tool
 SG_ MRR_RL_XCP_RESP_DAQ_Byte19 : 159|8@0+ (1,0) [0|255] ""  External_Tool
 SG_ MRR_RL_XCP_RESP_DAQ_Byte20 : 167|8@0+ (1,0) [0|255] ""  External_Tool
 SG_ MRR_RL_XCP_RESP_DAQ_Byte21 : 175|8@0+ (1,0) [0|255] ""  External_Tool
 SG_ MRR_RL_XCP_RESP_DAQ_Byte22 : 183|8@0+ (1,0) [0|255] ""  External_Tool
 SG_ MRR_RL_XCP_RESP_DAQ_Byte23 : 191|8@0+ (1,0) [0|255] ""  External_Tool
 SG_ MRR_RL_XCP_RESP_DAQ_Byte24 : 199|8@0+ (1,0) [0|255] ""  External_Tool
 SG_ MRR_RL_XCP_RESP_DAQ_Byte25 : 207|8@0+ (1,0) [0|255] ""  External_Tool
 SG_ MRR_RL_XCP_RESP_DAQ_Byte26 : 215|8@0+ (1,0) [0|255] ""  External_Tool
 SG_ MRR_RL_XCP_RESP_DAQ_Byte27 : 223|8@0+ (1,0) [0|255] ""  External_Tool
 SG_ MRR_RL_XCP_RESP_DAQ_Byte28 : 231|8@0+ (1,0) [0|255] ""  External_Tool
 SG_ MRR_RL_XCP_RESP_DAQ_Byte29 : 239|8@0+ (1,0) [0|255] ""  External_Tool
 SG_ MRR_RL_XCP_RESP_DAQ_Byte30 : 247|8@0+ (1,0) [0|255] ""  External_Tool
 SG_ MRR_RL_XCP_RESP_DAQ_Byte31 : 255|8@0+ (1,0) [0|255] ""  External_Tool
 SG_ MRR_RL_XCP_RESP_DAQ_Byte32 : 263|8@0+ (1,0) [0|255] ""  External_Tool
 SG_ MRR_RL_XCP_RESP_DAQ_Byte33 : 271|8@0+ (1,0) [0|255] ""  External_Tool
 SG_ MRR_RL_XCP_RESP_DAQ_Byte34 : 279|8@0+ (1,0) [0|255] ""  External_Tool
 SG_ MRR_RL_XCP_RESP_DAQ_Byte35 : 287|8@0+ (1,0) [0|255] ""  External_Tool
 SG_ MRR_RL_XCP_RESP_DAQ_Byte36 : 295|8@0+ (1,0) [0|255] ""  External_Tool
 SG_ MRR_RL_XCP_RESP_DAQ_Byte37 : 303|8@0+ (1,0) [0|255] ""  External_Tool
 SG_ MRR_RL_XCP_RESP_DAQ_Byte38 : 311|8@0+ (1,0) [0|255] ""  External_Tool
 SG_ MRR_RL_XCP_RESP_DAQ_Byte39 : 319|8@0+ (1,0) [0|255] ""  External_Tool
 SG_ MRR_RL_XCP_RESP_DAQ_Byte40 : 327|8@0+ (1,0) [0|255] ""  External_Tool
 SG_ MRR_RL_XCP_RESP_DAQ_Byte41 : 335|8@0+ (1,0) [0|255] ""  External_Tool
 SG_ MRR_RL_XCP_RESP_DAQ_Byte42 : 343|8@0+ (1,0) [0|255] ""  External_Tool
 SG_ MRR_RL_XCP_RESP_DAQ_Byte43 : 351|8@0+ (1,0) [0|255] ""  External_Tool
 SG_ MRR_RL_XCP_RESP_DAQ_Byte44 : 359|8@0+ (1,0) [0|255] ""  External_Tool
 SG_ MRR_RL_XCP_RESP_DAQ_Byte45 : 367|8@0+ (1,0) [0|255] ""  External_Tool
 SG_ MRR_RL_XCP_RESP_DAQ_Byte46 : 375|8@0+ (1,0) [0|255] ""  External_Tool
 SG_ MRR_RL_XCP_RESP_DAQ_Byte47 : 383|8@0+ (1,0) [0|255] ""  External_Tool
 SG_ MRR_RL_XCP_RESP_DAQ_Byte48 : 391|8@0+ (1,0) [0|255] ""  External_Tool
 SG_ MRR_RL_XCP_RESP_DAQ_Byte49 : 399|8@0+ (1,0) [0|255] ""  External_Tool
 SG_ MRR_RL_XCP_RESP_DAQ_Byte50 : 407|8@0+ (1,0) [0|255] ""  External_Tool
 SG_ MRR_RL_XCP_RESP_DAQ_Byte51 : 415|8@0+ (1,0) [0|255] ""  External_Tool
 SG_ MRR_RL_XCP_RESP_DAQ_Byte52 : 423|8@0+ (1,0) [0|255] ""  External_Tool
 SG_ MRR_RL_XCP_RESP_DAQ_Byte53 : 431|8@0+ (1,0) [0|255] ""  External_Tool
 SG_ MRR_RL_XCP_RESP_DAQ_Byte54 : 439|8@0+ (1,0) [0|255] ""  External_Tool
 SG_ MRR_RL_XCP_RESP_DAQ_Byte55 : 447|8@0+ (1,0) [0|255] ""  External_Tool
 SG_ MRR_RL_XCP_RESP_DAQ_Byte56 : 455|8@0+ (1,0) [0|255] ""  External_Tool
 SG_ MRR_RL_XCP_RESP_DAQ_Byte57 : 463|8@0+ (1,0) [0|255] ""  External_Tool
 SG_ MRR_RL_XCP_RESP_DAQ_Byte58 : 471|8@0+ (1,0) [0|255] ""  External_Tool
 SG_ MRR_RL_XCP_RESP_DAQ_Byte59 : 479|8@0+ (1,0) [0|255] ""  External_Tool
 SG_ MRR_RL_XCP_RESP_DAQ_Byte60 : 487|8@0+ (1,0) [0|255] ""  External_Tool
 SG_ MRR_RL_XCP_RESP_DAQ_Byte61 : 495|8@0+ (1,0) [0|255] ""  External_Tool
 SG_ MRR_RL_XCP_RESP_DAQ_Byte62 : 503|8@0+ (1,0) [0|255] ""  External_Tool
 SG_ MRR_RL_XCP_RESP_DAQ_Byte63 : 511|8@0+ (1,0) [0|255] ""  External_Tool

BO_ 1265 MRR_RR_XCP_CTO_Resp: 64 MRRRR
 SG_ MRR_RR_XCP_RESP_CTO_Byte0 : 7|8@0+ (1,0) [0|255] ""  External_Tool
 SG_ MRR_RR_XCP_RESP_CTO_Byte7 : 63|8@0+ (1,0) [0|255] ""  External_Tool
 SG_ MRR_RR_XCP_RESP_CTO_Byte6 : 55|8@0+ (1,0) [0|255] ""  External_Tool
 SG_ MRR_RR_XCP_RESP_CTO_Byte5 : 47|8@0+ (1,0) [0|255] ""  External_Tool
 SG_ MRR_RR_XCP_RESP_CTO_Byte4 : 39|8@0+ (1,0) [0|255] ""  External_Tool
 SG_ MRR_RR_XCP_RESP_CTO_Byte3 : 31|8@0+ (1,0) [0|255] ""  External_Tool
 SG_ MRR_RR_XCP_RESP_CTO_Byte2 : 23|8@0+ (1,0) [0|255] ""  External_Tool
 SG_ MRR_RR_XCP_RESP_CTO_Byte1 : 15|8@0+ (1,0) [0|255] ""  External_Tool
 SG_ MRR_RR_XCP_RESP_CTO_Byte8 : 71|8@0+ (1,0) [0|255] ""  External_Tool
 SG_ MRR_RR_XCP_RESP_CTO_Byte9 : 79|8@0+ (1,0) [0|255] ""  External_Tool
 SG_ MRR_RR_XCP_RESP_CTO_Byte10 : 87|8@0+ (1,0) [0|255] ""  External_Tool
 SG_ MRR_RR_XCP_RESP_CTO_Byte11 : 95|8@0+ (1,0) [0|255] ""  External_Tool
 SG_ MRR_RR_XCP_RESP_CTO_Byte12 : 103|8@0+ (1,0) [0|255] ""  External_Tool
 SG_ MRR_RR_XCP_RESP_CTO_Byte13 : 111|8@0+ (1,0) [0|255] ""  External_Tool
 SG_ MRR_RR_XCP_RESP_CTO_Byte14 : 119|8@0+ (1,0) [0|255] ""  External_Tool
 SG_ MRR_RR_XCP_RESP_CTO_Byte15 : 127|8@0+ (1,0) [0|255] ""  External_Tool
 SG_ MRR_RR_XCP_RESP_CTO_Byte16 : 135|8@0+ (1,0) [0|255] ""  External_Tool
 SG_ MRR_RR_XCP_RESP_CTO_Byte17 : 143|8@0+ (1,0) [0|255] ""  External_Tool
 SG_ MRR_RR_XCP_RESP_CTO_Byte18 : 151|8@0+ (1,0) [0|255] ""  External_Tool
 SG_ MRR_RR_XCP_RESP_CTO_Byte19 : 159|8@0+ (1,0) [0|255] ""  External_Tool
 SG_ MRR_RR_XCP_RESP_CTO_Byte20 : 167|8@0+ (1,0) [0|255] ""  External_Tool
 SG_ MRR_RR_XCP_RESP_CTO_Byte21 : 175|8@0+ (1,0) [0|255] ""  External_Tool
 SG_ MRR_RR_XCP_RESP_CTO_Byte22 : 183|8@0+ (1,0) [0|255] ""  External_Tool
 SG_ MRR_RR_XCP_RESP_CTO_Byte23 : 191|8@0+ (1,0) [0|255] ""  External_Tool
 SG_ MRR_RR_XCP_RESP_CTO_Byte24 : 199|8@0+ (1,0) [0|255] ""  External_Tool
 SG_ MRR_RR_XCP_RESP_CTO_Byte25 : 207|8@0+ (1,0) [0|255] ""  External_Tool
 SG_ MRR_RR_XCP_RESP_CTO_Byte26 : 215|8@0+ (1,0) [0|255] ""  External_Tool
 SG_ MRR_RR_XCP_RESP_CTO_Byte27 : 223|8@0+ (1,0) [0|255] ""  External_Tool
 SG_ MRR_RR_XCP_RESP_CTO_Byte28 : 231|8@0+ (1,0) [0|255] ""  External_Tool
 SG_ MRR_RR_XCP_RESP_CTO_Byte29 : 239|8@0+ (1,0) [0|255] ""  External_Tool
 SG_ MRR_RR_XCP_RESP_CTO_Byte30 : 247|8@0+ (1,0) [0|255] ""  External_Tool
 SG_ MRR_RR_XCP_RESP_CTO_Byte31 : 255|8@0+ (1,0) [0|255] ""  External_Tool
 SG_ MRR_RR_XCP_RESP_CTO_Byte32 : 263|8@0+ (1,0) [0|255] ""  External_Tool
 SG_ MRR_RR_XCP_RESP_CTO_Byte33 : 271|8@0+ (1,0) [0|255] ""  External_Tool
 SG_ MRR_RR_XCP_RESP_CTO_Byte34 : 279|8@0+ (1,0) [0|255] ""  External_Tool
 SG_ MRR_RR_XCP_RESP_CTO_Byte35 : 287|8@0+ (1,0) [0|255] ""  External_Tool
 SG_ MRR_RR_XCP_RESP_CTO_Byte36 : 295|8@0+ (1,0) [0|255] ""  External_Tool
 SG_ MRR_RR_XCP_RESP_CTO_Byte37 : 303|8@0+ (1,0) [0|255] ""  External_Tool
 SG_ MRR_RR_XCP_RESP_CTO_Byte38 : 311|8@0+ (1,0) [0|255] ""  External_Tool
 SG_ MRR_RR_XCP_RESP_CTO_Byte39 : 319|8@0+ (1,0) [0|255] ""  External_Tool
 SG_ MRR_RR_XCP_RESP_CTO_Byte40 : 327|8@0+ (1,0) [0|255] ""  External_Tool
 SG_ MRR_RR_XCP_RESP_CTO_Byte41 : 335|8@0+ (1,0) [0|255] ""  External_Tool
 SG_ MRR_RR_XCP_RESP_CTO_Byte42 : 343|8@0+ (1,0) [0|255] ""  External_Tool
 SG_ MRR_RR_XCP_RESP_CTO_Byte43 : 351|8@0+ (1,0) [0|255] ""  External_Tool
 SG_ MRR_RR_XCP_RESP_CTO_Byte44 : 359|8@0+ (1,0) [0|255] ""  External_Tool
 SG_ MRR_RR_XCP_RESP_CTO_Byte45 : 367|8@0+ (1,0) [0|255] ""  External_Tool
 SG_ MRR_RR_XCP_RESP_CTO_Byte46 : 375|8@0+ (1,0) [0|255] ""  External_Tool
 SG_ MRR_RR_XCP_RESP_CTO_Byte47 : 383|8@0+ (1,0) [0|255] ""  External_Tool
 SG_ MRR_RR_XCP_RESP_CTO_Byte48 : 391|8@0+ (1,0) [0|255] ""  External_Tool
 SG_ MRR_RR_XCP_RESP_CTO_Byte49 : 399|8@0+ (1,0) [0|255] ""  External_Tool
 SG_ MRR_RR_XCP_RESP_CTO_Byte50 : 407|8@0+ (1,0) [0|255] ""  External_Tool
 SG_ MRR_RR_XCP_RESP_CTO_Byte51 : 415|8@0+ (1,0) [0|255] ""  External_Tool
 SG_ MRR_RR_XCP_RESP_CTO_Byte52 : 423|8@0+ (1,0) [0|255] ""  External_Tool
 SG_ MRR_RR_XCP_RESP_CTO_Byte53 : 431|8@0+ (1,0) [0|255] ""  External_Tool
 SG_ MRR_RR_XCP_RESP_CTO_Byte54 : 439|8@0+ (1,0) [0|255] ""  External_Tool
 SG_ MRR_RR_XCP_RESP_CTO_Byte55 : 447|8@0+ (1,0) [0|255] ""  External_Tool
 SG_ MRR_RR_XCP_RESP_CTO_Byte56 : 455|8@0+ (1,0) [0|255] ""  External_Tool
 SG_ MRR_RR_XCP_RESP_CTO_Byte57 : 463|8@0+ (1,0) [0|255] ""  External_Tool
 SG_ MRR_RR_XCP_RESP_CTO_Byte58 : 471|8@0+ (1,0) [0|255] ""  External_Tool
 SG_ MRR_RR_XCP_RESP_CTO_Byte59 : 479|8@0+ (1,0) [0|255] ""  External_Tool
 SG_ MRR_RR_XCP_RESP_CTO_Byte60 : 487|8@0+ (1,0) [0|255] ""  External_Tool
 SG_ MRR_RR_XCP_RESP_CTO_Byte61 : 495|8@0+ (1,0) [0|255] ""  External_Tool
 SG_ MRR_RR_XCP_RESP_CTO_Byte62 : 503|8@0+ (1,0) [0|255] ""  External_Tool
 SG_ MRR_RR_XCP_RESP_CTO_Byte63 : 511|8@0+ (1,0) [0|255] ""  External_Tool

BO_ 1009 MRR_RL_XCP_CTO_Resp: 64 MRRRL
 SG_ MRR_RL_XCP_RESP_CTO_Byte0 : 7|8@0+ (1,0) [0|255] ""  External_Tool
 SG_ MRR_RL_XCP_RESP_CTO_Byte7 : 63|8@0+ (1,0) [0|255] ""  External_Tool
 SG_ MRR_RL_XCP_RESP_CTO_Byte6 : 55|8@0+ (1,0) [0|255] ""  External_Tool
 SG_ MRR_RL_XCP_RESP_CTO_Byte5 : 47|8@0+ (1,0) [0|255] ""  External_Tool
 SG_ MRR_RL_XCP_RESP_CTO_Byte4 : 39|8@0+ (1,0) [0|255] ""  External_Tool
 SG_ MRR_RL_XCP_RESP_CTO_Byte3 : 31|8@0+ (1,0) [0|255] ""  External_Tool
 SG_ MRR_RL_XCP_RESP_CTO_Byte2 : 23|8@0+ (1,0) [0|255] ""  External_Tool
 SG_ MRR_RL_XCP_RESP_CTO_Byte1 : 15|8@0+ (1,0) [0|255] ""  External_Tool
 SG_ MRR_RL_XCP_RESP_CTO_Byte8 : 71|8@0+ (1,0) [0|255] ""  External_Tool
 SG_ MRR_RL_XCP_RESP_CTO_Byte9 : 79|8@0+ (1,0) [0|255] ""  External_Tool
 SG_ MRR_RL_XCP_RESP_CTO_Byte10 : 87|8@0+ (1,0) [0|255] ""  External_Tool
 SG_ MRR_RL_XCP_RESP_CTO_Byte11 : 95|8@0+ (1,0) [0|255] ""  External_Tool
 SG_ MRR_RL_XCP_RESP_CTO_Byte12 : 103|8@0+ (1,0) [0|255] ""  External_Tool
 SG_ MRR_RL_XCP_RESP_CTO_Byte13 : 111|8@0+ (1,0) [0|255] ""  External_Tool
 SG_ MRR_RL_XCP_RESP_CTO_Byte14 : 119|8@0+ (1,0) [0|255] ""  External_Tool
 SG_ MRR_RL_XCP_RESP_CTO_Byte15 : 127|8@0+ (1,0) [0|255] ""  External_Tool
 SG_ MRR_RL_XCP_RESP_CTO_Byte16 : 135|8@0+ (1,0) [0|255] ""  External_Tool
 SG_ MRR_RL_XCP_RESP_CTO_Byte17 : 143|8@0+ (1,0) [0|255] ""  External_Tool
 SG_ MRR_RL_XCP_RESP_CTO_Byte18 : 151|8@0+ (1,0) [0|255] ""  External_Tool
 SG_ MRR_RL_XCP_RESP_CTO_Byte19 : 159|8@0+ (1,0) [0|255] ""  External_Tool
 SG_ MRR_RL_XCP_RESP_CTO_Byte20 : 167|8@0+ (1,0) [0|255] ""  External_Tool
 SG_ MRR_RL_XCP_RESP_CTO_Byte21 : 175|8@0+ (1,0) [0|255] ""  External_Tool
 SG_ MRR_RL_XCP_RESP_CTO_Byte22 : 183|8@0+ (1,0) [0|255] ""  External_Tool
 SG_ MRR_RL_XCP_RESP_CTO_Byte23 : 191|8@0+ (1,0) [0|255] ""  External_Tool
 SG_ MRR_RL_XCP_RESP_CTO_Byte24 : 199|8@0+ (1,0) [0|255] ""  External_Tool
 SG_ MRR_RL_XCP_RESP_CTO_Byte25 : 207|8@0+ (1,0) [0|255] ""  External_Tool
 SG_ MRR_RL_XCP_RESP_CTO_Byte26 : 215|8@0+ (1,0) [0|255] ""  External_Tool
 SG_ MRR_RL_XCP_RESP_CTO_Byte27 : 223|8@0+ (1,0) [0|255] ""  External_Tool
 SG_ MRR_RL_XCP_RESP_CTO_Byte28 : 231|8@0+ (1,0) [0|255] ""  External_Tool
 SG_ MRR_RL_XCP_RESP_CTO_Byte29 : 239|8@0+ (1,0) [0|255] ""  External_Tool
 SG_ MRR_RL_XCP_RESP_CTO_Byte30 : 247|8@0+ (1,0) [0|255] ""  External_Tool
 SG_ MRR_RL_XCP_RESP_CTO_Byte31 : 255|8@0+ (1,0) [0|255] ""  External_Tool
 SG_ MRR_RL_XCP_RESP_CTO_Byte32 : 263|8@0+ (1,0) [0|255] ""  External_Tool
 SG_ MRR_RL_XCP_RESP_CTO_Byte33 : 271|8@0+ (1,0) [0|255] ""  External_Tool
 SG_ MRR_RL_XCP_RESP_CTO_Byte34 : 279|8@0+ (1,0) [0|255] ""  External_Tool
 SG_ MRR_RL_XCP_RESP_CTO_Byte35 : 287|8@0+ (1,0) [0|255] ""  External_Tool
 SG_ MRR_RL_XCP_RESP_CTO_Byte36 : 295|8@0+ (1,0) [0|255] ""  External_Tool
 SG_ MRR_RL_XCP_RESP_CTO_Byte37 : 303|8@0+ (1,0) [0|255] ""  External_Tool
 SG_ MRR_RL_XCP_RESP_CTO_Byte38 : 311|8@0+ (1,0) [0|255] ""  External_Tool
 SG_ MRR_RL_XCP_RESP_CTO_Byte39 : 319|8@0+ (1,0) [0|255] ""  External_Tool
 SG_ MRR_RL_XCP_RESP_CTO_Byte40 : 327|8@0+ (1,0) [0|255] ""  External_Tool
 SG_ MRR_RL_XCP_RESP_CTO_Byte41 : 335|8@0+ (1,0) [0|255] ""  External_Tool
 SG_ MRR_RL_XCP_RESP_CTO_Byte42 : 343|8@0+ (1,0) [0|255] ""  External_Tool
 SG_ MRR_RL_XCP_RESP_CTO_Byte43 : 351|8@0+ (1,0) [0|255] ""  External_Tool
 SG_ MRR_RL_XCP_RESP_CTO_Byte44 : 359|8@0+ (1,0) [0|255] ""  External_Tool
 SG_ MRR_RL_XCP_RESP_CTO_Byte45 : 367|8@0+ (1,0) [0|255] ""  External_Tool
 SG_ MRR_RL_XCP_RESP_CTO_Byte46 : 375|8@0+ (1,0) [0|255] ""  External_Tool
 SG_ MRR_RL_XCP_RESP_CTO_Byte47 : 383|8@0+ (1,0) [0|255] ""  External_Tool
 SG_ MRR_RL_XCP_RESP_CTO_Byte48 : 391|8@0+ (1,0) [0|255] ""  External_Tool
 SG_ MRR_RL_XCP_RESP_CTO_Byte49 : 399|8@0+ (1,0) [0|255] ""  External_Tool
 SG_ MRR_RL_XCP_RESP_CTO_Byte50 : 407|8@0+ (1,0) [0|255] ""  External_Tool
 SG_ MRR_RL_XCP_RESP_CTO_Byte51 : 415|8@0+ (1,0) [0|255] ""  External_Tool
 SG_ MRR_RL_XCP_RESP_CTO_Byte52 : 423|8@0+ (1,0) [0|255] ""  External_Tool
 SG_ MRR_RL_XCP_RESP_CTO_Byte53 : 431|8@0+ (1,0) [0|255] ""  External_Tool
 SG_ MRR_RL_XCP_RESP_CTO_Byte54 : 439|8@0+ (1,0) [0|255] ""  External_Tool
 SG_ MRR_RL_XCP_RESP_CTO_Byte55 : 447|8@0+ (1,0) [0|255] ""  External_Tool
 SG_ MRR_RL_XCP_RESP_CTO_Byte56 : 455|8@0+ (1,0) [0|255] ""  External_Tool
 SG_ MRR_RL_XCP_RESP_CTO_Byte57 : 463|8@0+ (1,0) [0|255] ""  External_Tool
 SG_ MRR_RL_XCP_RESP_CTO_Byte58 : 471|8@0+ (1,0) [0|255] ""  External_Tool
 SG_ MRR_RL_XCP_RESP_CTO_Byte59 : 479|8@0+ (1,0) [0|255] ""  External_Tool
 SG_ MRR_RL_XCP_RESP_CTO_Byte60 : 487|8@0+ (1,0) [0|255] ""  External_Tool
 SG_ MRR_RL_XCP_RESP_CTO_Byte61 : 495|8@0+ (1,0) [0|255] ""  External_Tool
 SG_ MRR_RL_XCP_RESP_CTO_Byte62 : 503|8@0+ (1,0) [0|255] ""  External_Tool
 SG_ MRR_RL_XCP_RESP_CTO_Byte63 : 511|8@0+ (1,0) [0|255] ""  External_Tool

BO_ 1264 MRR_RR_XCP_CTO_Req: 64 External_Tool
 SG_ MRR_RR_PID : 7|8@0+ (1,0) [0|255] ""  MRRRR
 SG_ MRR_RR_XCP_REQ_CTO_Byte7 : 63|8@0+ (1,0) [0|255] ""  MRRRR
 SG_ MRR_RR_XCP_REQ_CTO_Byte6 : 55|8@0+ (1,0) [0|255] ""  MRRRR
 SG_ MRR_RR_XCP_REQ_CTO_Byte5 : 47|8@0+ (1,0) [0|255] ""  MRRRR
 SG_ MRR_RR_XCP_REQ_CTO_Byte4 : 39|8@0+ (1,0) [0|255] ""  MRRRR
 SG_ MRR_RR_XCP_REQ_CTO_Byte3 : 31|8@0+ (1,0) [0|255] ""  MRRRR
 SG_ MRR_RR_XCP_REQ_CTO_Byte2 : 23|8@0+ (1,0) [0|255] ""  MRRRR
 SG_ MRR_RR_XCP_REQ_CTO_Byte1 : 15|8@0+ (1,0) [0|255] ""  MRRRR
 SG_ MRR_RR_XCP_REQ_CTO_Byte8 : 71|8@0+ (1,0) [0|255] ""  MRRRR
 SG_ MRR_RR_XCP_REQ_CTO_Byte9 : 79|8@0+ (1,0) [0|255] ""  MRRRR
 SG_ MRR_RR_XCP_REQ_CTO_Byte10 : 87|8@0+ (1,0) [0|255] ""  MRRRR
 SG_ MRR_RR_XCP_REQ_CTO_Byte11 : 95|8@0+ (1,0) [0|255] ""  MRRRR
 SG_ MRR_RR_XCP_REQ_CTO_Byte12 : 103|8@0+ (1,0) [0|255] ""  MRRRR
 SG_ MRR_RR_XCP_REQ_CTO_Byte13 : 111|8@0+ (1,0) [0|255] ""  MRRRR
 SG_ MRR_RR_XCP_REQ_CTO_Byte14 : 119|8@0+ (1,0) [0|255] ""  MRRRR
 SG_ MRR_RR_XCP_REQ_CTO_Byte15 : 127|8@0+ (1,0) [0|255] ""  MRRRR
 SG_ MRR_RR_XCP_REQ_CTO_Byte16 : 135|8@0+ (1,0) [0|255] ""  MRRRR
 SG_ MRR_RR_XCP_REQ_CTO_Byte17 : 143|8@0+ (1,0) [0|255] ""  MRRRR
 SG_ MRR_RR_XCP_REQ_CTO_Byte18 : 151|8@0+ (1,0) [0|255] ""  MRRRR
 SG_ MRR_RR_XCP_REQ_CTO_Byte19 : 159|8@0+ (1,0) [0|255] ""  MRRRR
 SG_ MRR_RR_XCP_REQ_CTO_Byte20 : 167|8@0+ (1,0) [0|255] ""  MRRRR
 SG_ MRR_RR_XCP_REQ_CTO_Byte21 : 175|8@0+ (1,0) [0|255] ""  MRRRR
 SG_ MRR_RR_XCP_REQ_CTO_Byte22 : 183|8@0+ (1,0) [0|255] ""  MRRRR
 SG_ MRR_RR_XCP_REQ_CTO_Byte23 : 191|8@0+ (1,0) [0|255] ""  MRRRR
 SG_ MRR_RR_XCP_REQ_CTO_Byte24 : 199|8@0+ (1,0) [0|255] ""  MRRRR
 SG_ MRR_RR_XCP_REQ_CTO_Byte25 : 207|8@0+ (1,0) [0|255] ""  MRRRR
 SG_ MRR_RR_XCP_REQ_CTO_Byte26 : 215|8@0+ (1,0) [0|255] ""  MRRRR
 SG_ MRR_RR_XCP_REQ_CTO_Byte27 : 223|8@0+ (1,0) [0|255] ""  MRRRR
 SG_ MRR_RR_XCP_REQ_CTO_Byte28 : 231|8@0+ (1,0) [0|255] ""  MRRRR
 SG_ MRR_RR_XCP_REQ_CTO_Byte29 : 239|8@0+ (1,0) [0|255] ""  MRRRR
 SG_ MRR_RR_XCP_REQ_CTO_Byte30 : 247|8@0+ (1,0) [0|255] ""  MRRRR
 SG_ MRR_RR_XCP_REQ_CTO_Byte31 : 255|8@0+ (1,0) [0|255] ""  MRRRR
 SG_ MRR_RR_XCP_REQ_CTO_Byte32 : 263|8@0+ (1,0) [0|255] ""  MRRRR
 SG_ MRR_RR_XCP_REQ_CTO_Byte33 : 271|8@0+ (1,0) [0|255] ""  MRRRR
 SG_ MRR_RR_XCP_REQ_CTO_Byte34 : 279|8@0+ (1,0) [0|255] ""  MRRRR
 SG_ MRR_RR_XCP_REQ_CTO_Byte35 : 287|8@0+ (1,0) [0|255] ""  MRRRR
 SG_ MRR_RR_XCP_REQ_CTO_Byte36 : 295|8@0+ (1,0) [0|255] ""  MRRRR
 SG_ MRR_RR_XCP_REQ_CTO_Byte37 : 303|8@0+ (1,0) [0|255] ""  MRRRR
 SG_ MRR_RR_XCP_REQ_CTO_Byte38 : 311|8@0+ (1,0) [0|255] ""  MRRRR
 SG_ MRR_RR_XCP_REQ_CTO_Byte39 : 319|8@0+ (1,0) [0|255] ""  MRRRR
 SG_ MRR_RR_XCP_REQ_CTO_Byte40 : 327|8@0+ (1,0) [0|255] ""  MRRRR
 SG_ MRR_RR_XCP_REQ_CTO_Byte41 : 335|8@0+ (1,0) [0|255] ""  MRRRR
 SG_ MRR_RR_XCP_REQ_CTO_Byte42 : 343|8@0+ (1,0) [0|255] ""  MRRRR
 SG_ MRR_RR_XCP_REQ_CTO_Byte43 : 351|8@0+ (1,0) [0|255] ""  MRRRR
 SG_ MRR_RR_XCP_REQ_CTO_Byte44 : 359|8@0+ (1,0) [0|255] ""  MRRRR
 SG_ MRR_RR_XCP_REQ_CTO_Byte45 : 367|8@0+ (1,0) [0|255] ""  MRRRR
 SG_ MRR_RR_XCP_REQ_CTO_Byte46 : 375|8@0+ (1,0) [0|255] ""  MRRRR
 SG_ MRR_RR_XCP_REQ_CTO_Byte47 : 383|8@0+ (1,0) [0|255] ""  MRRRR
 SG_ MRR_RR_XCP_REQ_CTO_Byte48 : 391|8@0+ (1,0) [0|255] ""  MRRRR
 SG_ MRR_RR_XCP_REQ_CTO_Byte49 : 399|8@0+ (1,0) [0|255] ""  MRRRR
 SG_ MRR_RR_XCP_REQ_CTO_Byte50 : 407|8@0+ (1,0) [0|255] ""  MRRRR
 SG_ MRR_RR_XCP_REQ_CTO_Byte51 : 415|8@0+ (1,0) [0|255] ""  MRRRR
 SG_ MRR_RR_XCP_REQ_CTO_Byte52 : 423|8@0+ (1,0) [0|255] ""  MRRRR
 SG_ MRR_RR_XCP_REQ_CTO_Byte53 : 431|8@0+ (1,0) [0|255] ""  MRRRR
 SG_ MRR_RR_XCP_REQ_CTO_Byte54 : 439|8@0+ (1,0) [0|255] ""  MRRRR
 SG_ MRR_RR_XCP_REQ_CTO_Byte55 : 447|8@0+ (1,0) [0|255] ""  MRRRR
 SG_ MRR_RR_XCP_REQ_CTO_Byte56 : 455|8@0+ (1,0) [0|255] ""  MRRRR
 SG_ MRR_RR_XCP_REQ_CTO_Byte57 : 463|8@0+ (1,0) [0|255] ""  MRRRR
 SG_ MRR_RR_XCP_REQ_CTO_Byte58 : 471|8@0+ (1,0) [0|255] ""  MRRRR
 SG_ MRR_RR_XCP_REQ_CTO_Byte59 : 479|8@0+ (1,0) [0|255] ""  MRRRR
 SG_ MRR_RR_XCP_REQ_CTO_Byte60 : 487|8@0+ (1,0) [0|255] ""  MRRRR
 SG_ MRR_RR_XCP_REQ_CTO_Byte61 : 495|8@0+ (1,0) [0|255] ""  MRRRR
 SG_ MRR_RR_XCP_REQ_CTO_Byte62 : 503|8@0+ (1,0) [0|255] ""  MRRRR
 SG_ MRR_RR_XCP_REQ_CTO_Byte63 : 511|8@0+ (1,0) [0|255] ""  MRRRR

BO_ 1008 MRR_RL_XCP_CTO_Req: 64 External_Tool
 SG_ MRR_RL_PID : 7|8@0+ (1,0) [0|255] ""  MRRRL
 SG_ MRR_RL_XCP_REQ_CTO_Byte7 : 63|8@0+ (1,0) [0|255] ""  MRRRL
 SG_ MRR_RL_XCP_REQ_CTO_Byte6 : 55|8@0+ (1,0) [0|255] ""  MRRRL
 SG_ MRR_RL_XCP_REQ_CTO_Byte5 : 47|8@0+ (1,0) [0|255] ""  MRRRL
 SG_ MRR_RL_XCP_REQ_CTO_Byte4 : 39|8@0+ (1,0) [0|255] ""  MRRRL
 SG_ MRR_RL_XCP_REQ_CTO_Byte3 : 31|8@0+ (1,0) [0|255] ""  MRRRL
 SG_ MRR_RL_XCP_REQ_CTO_Byte2 : 23|8@0+ (1,0) [0|255] ""  MRRRL
 SG_ MRR_RL_XCP_REQ_CTO_Byte1 : 15|8@0+ (1,0) [0|255] ""  MRRRL
 SG_ MRR_RL_XCP_REQ_CTO_Byte8 : 71|8@0+ (1,0) [0|255] ""  MRRRL
 SG_ MRR_RL_XCP_REQ_CTO_Byte9 : 79|8@0+ (1,0) [0|255] ""  MRRRL
 SG_ MRR_RL_XCP_REQ_CTO_Byte10 : 87|8@0+ (1,0) [0|255] ""  MRRRL
 SG_ MRR_RL_XCP_REQ_CTO_Byte11 : 95|8@0+ (1,0) [0|255] ""  MRRRL
 SG_ MRR_RL_XCP_REQ_CTO_Byte12 : 103|8@0+ (1,0) [0|255] ""  MRRRL
 SG_ MRR_RL_XCP_REQ_CTO_Byte13 : 111|8@0+ (1,0) [0|255] ""  MRRRL
 SG_ MRR_RL_XCP_REQ_CTO_Byte14 : 119|8@0+ (1,0) [0|255] ""  MRRRL
 SG_ MRR_RL_XCP_REQ_CTO_Byte15 : 127|8@0+ (1,0) [0|255] ""  MRRRL
 SG_ MRR_RL_XCP_REQ_CTO_Byte16 : 135|8@0+ (1,0) [0|255] ""  MRRRL
 SG_ MRR_RL_XCP_REQ_CTO_Byte17 : 143|8@0+ (1,0) [0|255] ""  MRRRL
 SG_ MRR_RL_XCP_REQ_CTO_Byte18 : 151|8@0+ (1,0) [0|255] ""  MRRRL
 SG_ MRR_RL_XCP_REQ_CTO_Byte19 : 159|8@0+ (1,0) [0|255] ""  MRRRL
 SG_ MRR_RL_XCP_REQ_CTO_Byte20 : 167|8@0+ (1,0) [0|255] ""  MRRRL
 SG_ MRR_RL_XCP_REQ_CTO_Byte21 : 175|8@0+ (1,0) [0|255] ""  MRRRL
 SG_ MRR_RL_XCP_REQ_CTO_Byte22 : 183|8@0+ (1,0) [0|255] ""  MRRRL
 SG_ MRR_RL_XCP_REQ_CTO_Byte23 : 191|8@0+ (1,0) [0|255] ""  MRRRL
 SG_ MRR_RL_XCP_REQ_CTO_Byte24 : 199|8@0+ (1,0) [0|255] ""  MRRRL
 SG_ MRR_RL_XCP_REQ_CTO_Byte25 : 207|8@0+ (1,0) [0|255] ""  MRRRL
 SG_ MRR_RL_XCP_REQ_CTO_Byte26 : 215|8@0+ (1,0) [0|255] ""  MRRRL
 SG_ MRR_RL_XCP_REQ_CTO_Byte27 : 223|8@0+ (1,0) [0|255] ""  MRRRL
 SG_ MRR_RL_XCP_REQ_CTO_Byte28 : 231|8@0+ (1,0) [0|255] ""  MRRRL
 SG_ MRR_RL_XCP_REQ_CTO_Byte29 : 239|8@0+ (1,0) [0|255] ""  MRRRL
 SG_ MRR_RL_XCP_REQ_CTO_Byte30 : 247|8@0+ (1,0) [0|255] ""  MRRRL
 SG_ MRR_RL_XCP_REQ_CTO_Byte31 : 255|8@0+ (1,0) [0|255] ""  MRRRL
 SG_ MRR_RL_XCP_REQ_CTO_Byte32 : 263|8@0+ (1,0) [0|255] ""  MRRRL
 SG_ MRR_RL_XCP_REQ_CTO_Byte33 : 271|8@0+ (1,0) [0|255] ""  MRRRL
 SG_ MRR_RL_XCP_REQ_CTO_Byte34 : 279|8@0+ (1,0) [0|255] ""  MRRRL
 SG_ MRR_RL_XCP_REQ_CTO_Byte35 : 287|8@0+ (1,0) [0|255] ""  MRRRL
 SG_ MRR_RL_XCP_REQ_CTO_Byte36 : 295|8@0+ (1,0) [0|255] ""  MRRRL
 SG_ MRR_RL_XCP_REQ_CTO_Byte37 : 303|8@0+ (1,0) [0|255] ""  MRRRL
 SG_ MRR_RL_XCP_REQ_CTO_Byte38 : 311|8@0+ (1,0) [0|255] ""  MRRRL
 SG_ MRR_RL_XCP_REQ_CTO_Byte39 : 319|8@0+ (1,0) [0|255] ""  MRRRL
 SG_ MRR_RL_XCP_REQ_CTO_Byte40 : 327|8@0+ (1,0) [0|255] ""  MRRRL
 SG_ MRR_RL_XCP_REQ_CTO_Byte41 : 335|8@0+ (1,0) [0|255] ""  MRRRL
 SG_ MRR_RL_XCP_REQ_CTO_Byte42 : 343|8@0+ (1,0) [0|255] ""  MRRRL
 SG_ MRR_RL_XCP_REQ_CTO_Byte43 : 351|8@0+ (1,0) [0|255] ""  MRRRL
 SG_ MRR_RL_XCP_REQ_CTO_Byte44 : 359|8@0+ (1,0) [0|255] ""  MRRRL
 SG_ MRR_RL_XCP_REQ_CTO_Byte45 : 367|8@0+ (1,0) [0|255] ""  MRRRL
 SG_ MRR_RL_XCP_REQ_CTO_Byte46 : 375|8@0+ (1,0) [0|255] ""  MRRRL
 SG_ MRR_RL_XCP_REQ_CTO_Byte47 : 383|8@0+ (1,0) [0|255] ""  MRRRL
 SG_ MRR_RL_XCP_REQ_CTO_Byte48 : 391|8@0+ (1,0) [0|255] ""  MRRRL
 SG_ MRR_RL_XCP_REQ_CTO_Byte49 : 399|8@0+ (1,0) [0|255] ""  MRRRL
 SG_ MRR_RL_XCP_REQ_CTO_Byte50 : 407|8@0+ (1,0) [0|255] ""  MRRRL
 SG_ MRR_RL_XCP_REQ_CTO_Byte51 : 415|8@0+ (1,0) [0|255] ""  MRRRL
 SG_ MRR_RL_XCP_REQ_CTO_Byte52 : 423|8@0+ (1,0) [0|255] ""  MRRRL
 SG_ MRR_RL_XCP_REQ_CTO_Byte53 : 431|8@0+ (1,0) [0|255] ""  MRRRL
 SG_ MRR_RL_XCP_REQ_CTO_Byte54 : 439|8@0+ (1,0) [0|255] ""  MRRRL
 SG_ MRR_RL_XCP_REQ_CTO_Byte55 : 447|8@0+ (1,0) [0|255] ""  MRRRL
 SG_ MRR_RL_XCP_REQ_CTO_Byte56 : 455|8@0+ (1,0) [0|255] ""  MRRRL
 SG_ MRR_RL_XCP_REQ_CTO_Byte57 : 463|8@0+ (1,0) [0|255] ""  MRRRL
 SG_ MRR_RL_XCP_REQ_CTO_Byte58 : 471|8@0+ (1,0) [0|255] ""  MRRRL
 SG_ MRR_RL_XCP_REQ_CTO_Byte59 : 479|8@0+ (1,0) [0|255] ""  MRRRL
 SG_ MRR_RL_XCP_REQ_CTO_Byte60 : 487|8@0+ (1,0) [0|255] ""  MRRRL
 SG_ MRR_RL_XCP_REQ_CTO_Byte61 : 495|8@0+ (1,0) [0|255] ""  MRRRL
 SG_ MRR_RL_XCP_REQ_CTO_Byte62 : 503|8@0+ (1,0) [0|255] ""  MRRRL
 SG_ MRR_RL_XCP_REQ_CTO_Byte63 : 511|8@0+ (1,0) [0|255] ""  MRRRL

BO_TX_BU_ 2015 : External_Tool,CADM;
BA_DEF_ SG_  "NWM_WakeupAllowed" ENUM  "0 No","1 Yes";
BA_DEF_ BO_  "GenMsgTimeoutTime" INT 0 2500;
BA_DEF_ BO_  "WakeupMessage" ENUM  "0 No","1 Yes";
BA_DEF_ SG_  "SignalDescription" STRING ;
BA_DEF_ SG_  "GenSigTimeoutTime_ABS_ESC" INT 0 100000;
BA_DEF_ SG_  "UsedOnPgmDBC" ENUM  "No","Yes";
BA_DEF_ BO_  "VFrameFormat" ENUM  "StandardCAN","ExtendedCAN","reserved","reserved","reserved","reserved","reserved","reserved","reserved","reserved","reserved","reserved","reserved","reserved","StandardCAN_FD","ExtendedCAN_FD";
BA_DEF_ BO_  "DiagConnection" INT 0 65535;
BA_DEF_ BO_  "CanTpBs" INT 0 255;
BA_DEF_ BO_  "EventRateOfChange" INT 10 10000;
BA_DEF_ BO_  "DiagState" ENUM  "No","Yes";
BA_DEF_ BO_  "DiagRequest" ENUM  "No","Yes";
BA_DEF_ BO_  "DiagResponse" ENUM  "No","Yes";
BA_DEF_ SG_  "GenSigCycleTime" INT 0 0;
BA_DEF_ SG_  "GenSigMarked" STRING ;
BA_DEF_ SG_  "GenSigVtName" STRING ;
BA_DEF_ SG_  "GenSigVtEn" STRING ;
BA_DEF_ SG_  "GenSigCmt" STRING ;
BA_DEF_ SG_  "GenSigSendType" ENUM  "Cyclic","OnWrite","vector_leerstring","OnChange","vector_leerstring","IfActive","vector_leerstring","NoSigSendType";
BA_DEF_ SG_  "GenSigInactiveValue" INT 0 100000;
BA_DEF_ SG_  "GenSigMissingSourceValue" INT 0 1000000000;
BA_DEF_ SG_  "GenSigStartValue" INT 0 1000000000;
BA_DEF_ BO_  "GenMsgILSupport" ENUM  "No","Yes";
BA_DEF_ BO_  "GenMsgSendType" ENUM  "FixedPeriodic","Event","EnabledPeriodic","NotUsed","NotUsed","EventPeriodic","NotUsed","NotUsed","NoMsgSendType";
BA_DEF_ BO_  "GenMsgCycleTime" INT 0 100000;
BA_DEF_ BO_  "GenMsgDelayTime" INT 0 10000;
BA_DEF_ BO_  "GenMsgNrOfRepetition" INT 0 100;
BA_DEF_ BO_  "GenMsgStartDelayTime" INT 0 10000;
BA_DEF_ BO_  "NetworkInitialization" ENUM  "No","Yes";
BA_DEF_ SG_  "SystemSignalLongSymbol" STRING ;
BA_DEF_DEF_  "NWM_WakeupAllowed" "0 No";
BA_DEF_DEF_  "GenMsgTimeoutTime" 2500;
BA_DEF_DEF_  "WakeupMessage" "0 No";
BA_DEF_DEF_  "SignalDescription" "";
BA_DEF_DEF_  "GenSigTimeoutTime_ABS_ESC" 0;
BA_DEF_DEF_  "UsedOnPgmDBC" "Yes";
BA_DEF_DEF_  "VFrameFormat" "StandardCAN_FD";
BA_DEF_DEF_  "DiagConnection" 0;
BA_DEF_DEF_  "CanTpBs" 255;
BA_DEF_DEF_  "EventRateOfChange" 10000;
BA_DEF_DEF_  "DiagState" "No";
BA_DEF_DEF_  "DiagRequest" "No";
BA_DEF_DEF_  "DiagResponse" "No";
BA_DEF_DEF_  "GenSigCycleTime" 0;
BA_DEF_DEF_  "GenSigMarked" "";
BA_DEF_DEF_  "GenSigVtName" "";
BA_DEF_DEF_  "GenSigVtEn" "";
BA_DEF_DEF_  "GenSigCmt" "";
BA_DEF_DEF_  "GenSigSendType" "NoSigSendType";
BA_DEF_DEF_  "GenSigInactiveValue" 0;
BA_DEF_DEF_  "GenSigMissingSourceValue" 0;
BA_DEF_DEF_  "GenSigStartValue" 0;
BA_DEF_DEF_  "GenMsgILSupport" "Yes";
BA_DEF_DEF_  "GenMsgSendType" "NoMsgSendType";
BA_DEF_DEF_  "GenMsgCycleTime" 0;
BA_DEF_DEF_  "GenMsgDelayTime" 0;
BA_DEF_DEF_  "GenMsgNrOfRepetition" 0;
BA_DEF_DEF_  "GenMsgStartDelayTime" 0;
BA_DEF_DEF_  "NetworkInitialization" "No";
BA_DEF_DEF_  "SystemSignalLongSymbol" "";
BA_ "GenMsgTimeoutTime" BO_ 1283 0;
BA_ "GenMsgSendType" BO_ 1283 1;
BA_ "GenMsgTimeoutTime" BO_ 1282 0;
BA_ "GenMsgSendType" BO_ 1282 1;
BA_ "GenMsgTimeoutTime" BO_ 1281 0;
BA_ "GenMsgSendType" BO_ 1281 1;
BA_ "GenMsgTimeoutTime" BO_ 323 0;
BA_ "GenMsgSendType" BO_ 323 0;
BA_ "GenMsgCycleTime" BO_ 323 50;
BA_ "GenMsgTimeoutTime" BO_ 1346 0;
BA_ "GenMsgSendType" BO_ 1346 0;
BA_ "GenMsgCycleTime" BO_ 1346 1000;
BA_ "GenMsgTimeoutTime" BO_ 20 0;
BA_ "GenMsgCycleTime" BO_ 20 25;
BA_ "GenMsgSendType" BO_ 20 0;
BA_ "GenMsgTimeoutTime" BO_ 21 0;
BA_ "GenMsgCycleTime" BO_ 21 25;
BA_ "GenMsgSendType" BO_ 21 0;
BA_ "GenMsgTimeoutTime" BO_ 18 0;
BA_ "GenMsgSendType" BO_ 18 1;
BA_ "GenMsgTimeoutTime" BO_ 19 0;
BA_ "GenMsgSendType" BO_ 19 1;
BA_ "GenMsgTimeoutTime" BO_ 1796 0;
BA_ "GenMsgCycleTime" BO_ 1796 1000;
BA_ "GenMsgSendType" BO_ 1796 0;
BA_ "GenMsgTimeoutTime" BO_ 4 0;
BA_ "GenMsgSendType" BO_ 4 0;
BA_ "GenMsgCycleTime" BO_ 4 50;
BA_ "GenMsgTimeoutTime" BO_ 334 0;
BA_ "GenMsgSendType" BO_ 334 1;
BA_ "GenMsgTimeoutTime" BO_ 270 0;
BA_ "GenMsgSendType" BO_ 270 1;
BA_ "GenMsgTimeoutTime" BO_ 1280 0;
BA_ "GenMsgSendType" BO_ 1280 1;
BA_ "GenMsgTimeoutTime" BO_ 1988 0;
BA_ "GenMsgSendType" BO_ 1988 1;
BA_ "DiagRequest" BO_ 1988 1;
BA_ "DiagConnection" BO_ 1988 1;
BA_ "GenMsgTimeoutTime" BO_ 1990 0;
BA_ "GenMsgSendType" BO_ 1990 1;
BA_ "DiagRequest" BO_ 1990 1;
BA_ "DiagConnection" BO_ 1990 1;
BA_ "GenMsgTimeoutTime" BO_ 1996 0;
BA_ "GenMsgSendType" BO_ 1996 1;
BA_ "DiagResponse" BO_ 1996 1;
BA_ "DiagConnection" BO_ 1996 1;
BA_ "GenMsgTimeoutTime" BO_ 1998 0;
BA_ "GenMsgSendType" BO_ 1998 1;
BA_ "DiagResponse" BO_ 1998 1;
BA_ "DiagConnection" BO_ 1998 1;
BA_ "GenMsgTimeoutTime" BO_ 2015 0;
BA_ "GenMsgSendType" BO_ 2015 1;
BA_ "DiagState" BO_ 2015 1;
BA_ "DiagRequest" BO_ 2015 1;
BA_ "GenMsgTimeoutTime" BO_ 1268 0;
BA_ "GenMsgSendType" BO_ 1268 1;
BA_ "GenMsgTimeoutTime" BO_ 1012 0;
BA_ "GenMsgSendType" BO_ 1012 1;
BA_ "GenMsgTimeoutTime" BO_ 1265 0;
BA_ "GenMsgSendType" BO_ 1265 1;
BA_ "GenMsgTimeoutTime" BO_ 1009 0;
BA_ "GenMsgSendType" BO_ 1009 1;
BA_ "GenMsgTimeoutTime" BO_ 1264 0;
BA_ "GenMsgSendType" BO_ 1264 1;
BA_ "GenMsgTimeoutTime" BO_ 1008 0;
BA_ "GenMsgSendType" BO_ 1008 1;
BA_ "GenSigSendType" SG_ 1283 MRR_RL_CAN_DET_MID_TARGET_028 1;
BA_ "SignalDescription" SG_ 1283 MRR_RL_CAN_DET_MID_TARGET_028 "MID_Target_Discrimination";
BA_ "SignalDescription" SG_ 1283 MRR_RL_CAN_DET_MID_TARGET_027 "MID_Target_Discrimination";
BA_ "SignalDescription" SG_ 1283 MRR_RL_CAN_DET_MID_TARGET_026 "MID_Target_Discrimination";
BA_ "SignalDescription" SG_ 1283 MRR_RL_CAN_DET_MID_TARGET_025 "MID_Target_Discrimination";
BA_ "SignalDescription" SG_ 1283 MRR_RL_CAN_DET_MID_TARGET_024 "MID_Target_Discrimination";
BA_ "SignalDescription" SG_ 1283 MRR_RL_CAN_DET_MID_TARGET_023 "MID_Target_Discrimination";
BA_ "SignalDescription" SG_ 1283 MRR_RL_CAN_DET_MID_TARGET_022 "MID_Target_Discrimination";
BA_ "SignalDescription" SG_ 1283 MRR_RL_CAN_DET_Near_TARGET_022 "Near_Target_Discrimination";
BA_ "SignalDescription" SG_ 1283 MRR_RL_CAN_DET_Near_TARGET_023 "Near_Target_Discrimination";
BA_ "SignalDescription" SG_ 1283 MRR_RL_CAN_DET_Near_TARGET_024 "Near_Target_Discrimination";
BA_ "SignalDescription" SG_ 1283 MRR_RL_CAN_DET_Near_TARGET_025 "Near_Target_Discrimination";
BA_ "SignalDescription" SG_ 1283 MRR_RL_CAN_DET_Near_TARGET_026 "Near_Target_Discrimination";
BA_ "SignalDescription" SG_ 1283 MRR_RL_CAN_DET_Near_TARGET_027 "Near_Target_Discrimination";
BA_ "SignalDescription" SG_ 1283 MRR_RL_CAN_DET_Near_TARGET_028 "Near_Target_Discrimination";
BA_ "GenSigCmt" SG_ 1283 MRR_RL_CAN_DET_SUPER_RES_TA_0035 "Super resolution target ";
BA_ "SystemSignalLongSymbol" SG_ 1283 MRR_RL_CAN_DET_SUPER_RES_TA_0035 "MRR_RL_CAN_DET_SUPER_RES_TARGET_028";
BA_ "GenSigStartValue" SG_ 1283 MRR_RL_CAN_DET_ELEVATION_028 63.8646288209607;
BA_ "GenSigCmt" SG_ 1283 MRR_RL_CAN_DET_ELEVATION_028 "Detected object elevation position";
BA_ "GenSigCmt" SG_ 1283 MRR_RL_CAN_DET_HOST_VEH_CLU_0035 "Host vehicle clutter";
BA_ "SystemSignalLongSymbol" SG_ 1283 MRR_RL_CAN_DET_HOST_VEH_CLU_0035 "MRR_RL_CAN_DET_HOST_VEH_CLUTTER_028";
BA_ "GenSigCmt" SG_ 1283 MRR_RL_CAN_DET_CONFID_ELEVA_0035 "Elevation Angle Confidence";
BA_ "SystemSignalLongSymbol" SG_ 1283 MRR_RL_CAN_DET_CONFID_ELEVA_0035 "MRR_RL_CAN_DET_CONFID_ELEVATION_028";
BA_ "GenSigStartValue" SG_ 1283 MRR_RL_CAN_DET_AZIMUTH_028 8194.05320813772;
BA_ "GenSigCmt" SG_ 1283 MRR_RL_CAN_DET_AZIMUTH_028 "Detected object azimuth position";
BA_ "GenSigCmt" SG_ 1283 MRR_RL_CAN_DET_CONFID_AZIMU_0031 "Signal to noise level";
BA_ "GenSigVtEn" SG_ 1283 MRR_RL_CAN_DET_CONFID_AZIMU_0031 "TRUE";
BA_ "SystemSignalLongSymbol" SG_ 1283 MRR_RL_CAN_DET_CONFID_AZIMU_0031 "MRR_RL_CAN_DET_CONFID_AZIMUTH_028";
BA_ "GenSigCmt" SG_ 1283 MRR_RL_CAN_DET_RANGE_028 "Detected object range";
BA_ "GenSigCmt" SG_ 1283 MRR_RL_CAN_SCAN_INDEX_2LSB_028 "The two LSB of scan index";
BA_ "GenSigStartValue" SG_ 1283 MRR_RL_CAN_DET_RANGE_RATE_028 8192;
BA_ "GenSigCmt" SG_ 1283 MRR_RL_CAN_DET_RANGE_RATE_028 "Detected object range rate";
BA_ "GenSigCmt" SG_ 1283 MRR_RL_CAN_DET_VALID_LEVEL_028 "Detected object valid level";
BA_ "GenSigStartValue" SG_ 1283 MRR_RL_CAN_DET_AMPLITUDE_028 64;
BA_ "GenSigCmt" SG_ 1283 MRR_RL_CAN_DET_AMPLITUDE_028 "Detected object amplitude";
BA_ "GenSigCmt" SG_ 1283 MRR_RL_CAN_DET_SUPER_RES_TA_0036 "Super resolution target ";
BA_ "SystemSignalLongSymbol" SG_ 1283 MRR_RL_CAN_DET_SUPER_RES_TA_0036 "MRR_RL_CAN_DET_SUPER_RES_TARGET_027";
BA_ "GenSigStartValue" SG_ 1283 MRR_RL_CAN_DET_ELEVATION_027 63.8646288209607;
BA_ "GenSigCmt" SG_ 1283 MRR_RL_CAN_DET_ELEVATION_027 "Detected object elevation position";
BA_ "GenSigCmt" SG_ 1283 MRR_RL_CAN_DET_HOST_VEH_CLU_0036 "Host vehicle clutter";
BA_ "SystemSignalLongSymbol" SG_ 1283 MRR_RL_CAN_DET_HOST_VEH_CLU_0036 "MRR_RL_CAN_DET_HOST_VEH_CLUTTER_027";
BA_ "GenSigCmt" SG_ 1283 MRR_RL_CAN_DET_CONFID_ELEVA_0036 "Elevation Angle Confidence";
BA_ "SystemSignalLongSymbol" SG_ 1283 MRR_RL_CAN_DET_CONFID_ELEVA_0036 "MRR_RL_CAN_DET_CONFID_ELEVATION_027";
BA_ "GenSigStartValue" SG_ 1283 MRR_RL_CAN_DET_AZIMUTH_027 8194.05320813772;
BA_ "GenSigCmt" SG_ 1283 MRR_RL_CAN_DET_AZIMUTH_027 "Detected object azimuth position";
BA_ "GenSigCmt" SG_ 1283 MRR_RL_CAN_DET_CONFID_AZIMU_0032 "Signal to noise level";
BA_ "GenSigVtEn" SG_ 1283 MRR_RL_CAN_DET_CONFID_AZIMU_0032 "TRUE";
BA_ "SystemSignalLongSymbol" SG_ 1283 MRR_RL_CAN_DET_CONFID_AZIMU_0032 "MRR_RL_CAN_DET_CONFID_AZIMUTH_027";
BA_ "GenSigCmt" SG_ 1283 MRR_RL_CAN_DET_RANGE_027 "Detected object range";
BA_ "GenSigCmt" SG_ 1283 MRR_RL_CAN_SCAN_INDEX_2LSB_027 "The two LSB of scan index";
BA_ "GenSigStartValue" SG_ 1283 MRR_RL_CAN_DET_RANGE_RATE_027 8192;
BA_ "GenSigCmt" SG_ 1283 MRR_RL_CAN_DET_RANGE_RATE_027 "Detected object range rate";
BA_ "GenSigCmt" SG_ 1283 MRR_RL_CAN_DET_VALID_LEVEL_027 "Detected object valid level";
BA_ "GenSigStartValue" SG_ 1283 MRR_RL_CAN_DET_AMPLITUDE_027 64;
BA_ "GenSigCmt" SG_ 1283 MRR_RL_CAN_DET_AMPLITUDE_027 "Detected object amplitude";
BA_ "GenSigCmt" SG_ 1283 MRR_RL_CAN_DET_SUPER_RES_TA_0037 "Super resolution target ";
BA_ "SystemSignalLongSymbol" SG_ 1283 MRR_RL_CAN_DET_SUPER_RES_TA_0037 "MRR_RL_CAN_DET_SUPER_RES_TARGET_026";
BA_ "GenSigStartValue" SG_ 1283 MRR_RL_CAN_DET_ELEVATION_026 63.8646288209607;
BA_ "GenSigCmt" SG_ 1283 MRR_RL_CAN_DET_ELEVATION_026 "Detected object elevation position";
BA_ "GenSigCmt" SG_ 1283 MRR_RL_CAN_DET_HOST_VEH_CLU_0037 "Host vehicle clutter";
BA_ "SystemSignalLongSymbol" SG_ 1283 MRR_RL_CAN_DET_HOST_VEH_CLU_0037 "MRR_RL_CAN_DET_HOST_VEH_CLUTTER_026";
BA_ "GenSigCmt" SG_ 1283 MRR_RL_CAN_DET_CONFID_ELEVA_0037 "Elevation Angle Confidence";
BA_ "SystemSignalLongSymbol" SG_ 1283 MRR_RL_CAN_DET_CONFID_ELEVA_0037 "MRR_RL_CAN_DET_CONFID_ELEVATION_026";
BA_ "GenSigStartValue" SG_ 1283 MRR_RL_CAN_DET_AZIMUTH_026 8194.05320813772;
BA_ "GenSigCmt" SG_ 1283 MRR_RL_CAN_DET_AZIMUTH_026 "Detected object azimuth position";
BA_ "GenSigCmt" SG_ 1283 MRR_RL_CAN_DET_CONFID_AZIMU_0033 "Signal to noise level";
BA_ "GenSigVtEn" SG_ 1283 MRR_RL_CAN_DET_CONFID_AZIMU_0033 "TRUE";
BA_ "SystemSignalLongSymbol" SG_ 1283 MRR_RL_CAN_DET_CONFID_AZIMU_0033 "MRR_RL_CAN_DET_CONFID_AZIMUTH_026";
BA_ "GenSigCmt" SG_ 1283 MRR_RL_CAN_DET_RANGE_026 "Detected object range";
BA_ "GenSigCmt" SG_ 1283 MRR_RL_CAN_SCAN_INDEX_2LSB_026 "The two LSB of scan index";
BA_ "GenSigStartValue" SG_ 1283 MRR_RL_CAN_DET_RANGE_RATE_026 8192;
BA_ "GenSigCmt" SG_ 1283 MRR_RL_CAN_DET_RANGE_RATE_026 "Detected object range rate";
BA_ "GenSigCmt" SG_ 1283 MRR_RL_CAN_DET_VALID_LEVEL_026 "Detected object valid level";
BA_ "GenSigStartValue" SG_ 1283 MRR_RL_CAN_DET_AMPLITUDE_026 64;
BA_ "GenSigCmt" SG_ 1283 MRR_RL_CAN_DET_AMPLITUDE_026 "Detected object amplitude";
BA_ "GenSigCmt" SG_ 1283 MRR_RL_CAN_DET_SUPER_RES_TA_0038 "Super resolution target ";
BA_ "SystemSignalLongSymbol" SG_ 1283 MRR_RL_CAN_DET_SUPER_RES_TA_0038 "MRR_RL_CAN_DET_SUPER_RES_TARGET_025";
BA_ "GenSigStartValue" SG_ 1283 MRR_RL_CAN_DET_ELEVATION_025 63.8646288209607;
BA_ "GenSigCmt" SG_ 1283 MRR_RL_CAN_DET_ELEVATION_025 "Detected object elevation position";
BA_ "GenSigCmt" SG_ 1283 MRR_RL_CAN_DET_HOST_VEH_CLU_0038 "Host vehicle clutter";
BA_ "SystemSignalLongSymbol" SG_ 1283 MRR_RL_CAN_DET_HOST_VEH_CLU_0038 "MRR_RL_CAN_DET_HOST_VEH_CLUTTER_025";
BA_ "GenSigCmt" SG_ 1283 MRR_RL_CAN_DET_CONFID_ELEVA_0038 "Elevation Angle Confidence";
BA_ "SystemSignalLongSymbol" SG_ 1283 MRR_RL_CAN_DET_CONFID_ELEVA_0038 "MRR_RL_CAN_DET_CONFID_ELEVATION_025";
BA_ "GenSigStartValue" SG_ 1283 MRR_RL_CAN_DET_AZIMUTH_025 8194.05320813772;
BA_ "GenSigCmt" SG_ 1283 MRR_RL_CAN_DET_AZIMUTH_025 "Detected object azimuth position";
BA_ "GenSigCmt" SG_ 1283 MRR_RL_CAN_DET_CONFID_AZIMU_0034 "Signal to noise level";
BA_ "GenSigVtEn" SG_ 1283 MRR_RL_CAN_DET_CONFID_AZIMU_0034 "TRUE";
BA_ "SystemSignalLongSymbol" SG_ 1283 MRR_RL_CAN_DET_CONFID_AZIMU_0034 "MRR_RL_CAN_DET_CONFID_AZIMUTH_025";
BA_ "GenSigCmt" SG_ 1283 MRR_RL_CAN_DET_RANGE_025 "Detected object range";
BA_ "GenSigCmt" SG_ 1283 MRR_RL_CAN_SCAN_INDEX_2LSB_025 "The two LSB of scan index";
BA_ "GenSigStartValue" SG_ 1283 MRR_RL_CAN_DET_RANGE_RATE_025 8192;
BA_ "GenSigCmt" SG_ 1283 MRR_RL_CAN_DET_RANGE_RATE_025 "Detected object range rate";
BA_ "GenSigCmt" SG_ 1283 MRR_RL_CAN_DET_VALID_LEVEL_025 "Detected object valid level";
BA_ "GenSigStartValue" SG_ 1283 MRR_RL_CAN_DET_AMPLITUDE_025 64;
BA_ "GenSigCmt" SG_ 1283 MRR_RL_CAN_DET_AMPLITUDE_025 "Detected object amplitude";
BA_ "GenSigCmt" SG_ 1283 MRR_RL_CAN_DET_SUPER_RES_TA_0039 "Super resolution target ";
BA_ "SystemSignalLongSymbol" SG_ 1283 MRR_RL_CAN_DET_SUPER_RES_TA_0039 "MRR_RL_CAN_DET_SUPER_RES_TARGET_024";
BA_ "GenSigStartValue" SG_ 1283 MRR_RL_CAN_DET_ELEVATION_024 63.8646288209607;
BA_ "GenSigCmt" SG_ 1283 MRR_RL_CAN_DET_ELEVATION_024 "Detected object elevation position";
BA_ "GenSigCmt" SG_ 1283 MRR_RL_CAN_DET_HOST_VEH_CLU_0039 "Host vehicle clutter";
BA_ "SystemSignalLongSymbol" SG_ 1283 MRR_RL_CAN_DET_HOST_VEH_CLU_0039 "MRR_RL_CAN_DET_HOST_VEH_CLUTTER_024";
BA_ "GenSigCmt" SG_ 1283 MRR_RL_CAN_DET_CONFID_ELEVA_0039 "Elevation Angle Confidence";
BA_ "SystemSignalLongSymbol" SG_ 1283 MRR_RL_CAN_DET_CONFID_ELEVA_0039 "MRR_RL_CAN_DET_CONFID_ELEVATION_024";
BA_ "GenSigStartValue" SG_ 1283 MRR_RL_CAN_DET_AZIMUTH_024 8194.05320813772;
BA_ "GenSigCmt" SG_ 1283 MRR_RL_CAN_DET_AZIMUTH_024 "Detected object azimuth position";
BA_ "GenSigCmt" SG_ 1283 MRR_RL_CAN_DET_CONFID_AZIMU_0035 "Signal to noise level";
BA_ "GenSigVtEn" SG_ 1283 MRR_RL_CAN_DET_CONFID_AZIMU_0035 "TRUE";
BA_ "SystemSignalLongSymbol" SG_ 1283 MRR_RL_CAN_DET_CONFID_AZIMU_0035 "MRR_RL_CAN_DET_CONFID_AZIMUTH_024";
BA_ "GenSigCmt" SG_ 1283 MRR_RL_CAN_DET_RANGE_024 "Detected object range";
BA_ "GenSigCmt" SG_ 1283 MRR_RL_CAN_SCAN_INDEX_2LSB_024 "The two LSB of scan index";
BA_ "GenSigStartValue" SG_ 1283 MRR_RL_CAN_DET_RANGE_RATE_024 8192;
BA_ "GenSigCmt" SG_ 1283 MRR_RL_CAN_DET_RANGE_RATE_024 "Detected object range rate";
BA_ "GenSigCmt" SG_ 1283 MRR_RL_CAN_DET_VALID_LEVEL_024 "Detected object valid level";
BA_ "GenSigStartValue" SG_ 1283 MRR_RL_CAN_DET_AMPLITUDE_024 64;
BA_ "GenSigCmt" SG_ 1283 MRR_RL_CAN_DET_AMPLITUDE_024 "Detected object amplitude";
BA_ "GenSigCmt" SG_ 1283 MRR_RL_CAN_DET_SUPER_RES_TA_0040 "Super resolution target ";
BA_ "SystemSignalLongSymbol" SG_ 1283 MRR_RL_CAN_DET_SUPER_RES_TA_0040 "MRR_RL_CAN_DET_SUPER_RES_TARGET_023";
BA_ "GenSigStartValue" SG_ 1283 MRR_RL_CAN_DET_ELEVATION_023 63.8646288209607;
BA_ "GenSigCmt" SG_ 1283 MRR_RL_CAN_DET_ELEVATION_023 "Detected object elevation position";
BA_ "GenSigCmt" SG_ 1283 MRR_RL_CAN_DET_HOST_VEH_CLU_0040 "Host vehicle clutter";
BA_ "SystemSignalLongSymbol" SG_ 1283 MRR_RL_CAN_DET_HOST_VEH_CLU_0040 "MRR_RL_CAN_DET_HOST_VEH_CLUTTER_023";
BA_ "GenSigCmt" SG_ 1283 MRR_RL_CAN_DET_CONFID_ELEVA_0040 "Elevation Angle Confidence";
BA_ "SystemSignalLongSymbol" SG_ 1283 MRR_RL_CAN_DET_CONFID_ELEVA_0040 "MRR_RL_CAN_DET_CONFID_ELEVATION_023";
BA_ "GenSigStartValue" SG_ 1283 MRR_RL_CAN_DET_AZIMUTH_023 8194.05320813772;
BA_ "GenSigCmt" SG_ 1283 MRR_RL_CAN_DET_AZIMUTH_023 "Detected object azimuth position";
BA_ "GenSigCmt" SG_ 1283 MRR_RL_CAN_DET_CONFID_AZIMU_0036 "Signal to noise level";
BA_ "GenSigVtEn" SG_ 1283 MRR_RL_CAN_DET_CONFID_AZIMU_0036 "TRUE";
BA_ "SystemSignalLongSymbol" SG_ 1283 MRR_RL_CAN_DET_CONFID_AZIMU_0036 "MRR_RL_CAN_DET_CONFID_AZIMUTH_023";
BA_ "GenSigCmt" SG_ 1283 MRR_RL_CAN_DET_RANGE_023 "Detected object range";
BA_ "GenSigCmt" SG_ 1283 MRR_RL_CAN_SCAN_INDEX_2LSB_023 "The two LSB of scan index";
BA_ "GenSigStartValue" SG_ 1283 MRR_RL_CAN_DET_RANGE_RATE_023 8192;
BA_ "GenSigCmt" SG_ 1283 MRR_RL_CAN_DET_RANGE_RATE_023 "Detected object range rate";
BA_ "GenSigCmt" SG_ 1283 MRR_RL_CAN_DET_VALID_LEVEL_023 "Detected object valid level";
BA_ "GenSigStartValue" SG_ 1283 MRR_RL_CAN_DET_AMPLITUDE_023 64;
BA_ "GenSigCmt" SG_ 1283 MRR_RL_CAN_DET_AMPLITUDE_023 "Detected object amplitude";
BA_ "GenSigCmt" SG_ 1283 MRR_RL_CAN_DET_SUPER_RES_TA_0041 "Super resolution target ";
BA_ "SystemSignalLongSymbol" SG_ 1283 MRR_RL_CAN_DET_SUPER_RES_TA_0041 "MRR_RL_CAN_DET_SUPER_RES_TARGET_022";
BA_ "GenSigStartValue" SG_ 1283 MRR_RL_CAN_DET_ELEVATION_022 63.8646288209607;
BA_ "GenSigCmt" SG_ 1283 MRR_RL_CAN_DET_ELEVATION_022 "Detected object elevation position";
BA_ "GenSigCmt" SG_ 1283 MRR_RL_CAN_DET_HOST_VEH_CLU_0041 "Host vehicle clutter";
BA_ "SystemSignalLongSymbol" SG_ 1283 MRR_RL_CAN_DET_HOST_VEH_CLU_0041 "MRR_RL_CAN_DET_HOST_VEH_CLUTTER_022";
BA_ "GenSigCmt" SG_ 1283 MRR_RL_CAN_DET_CONFID_ELEVA_0041 "Elevation Angle Confidence";
BA_ "SystemSignalLongSymbol" SG_ 1283 MRR_RL_CAN_DET_CONFID_ELEVA_0041 "MRR_RL_CAN_DET_CONFID_ELEVATION_022";
BA_ "GenSigStartValue" SG_ 1283 MRR_RL_CAN_DET_AZIMUTH_022 8194.05320813772;
BA_ "GenSigCmt" SG_ 1283 MRR_RL_CAN_DET_AZIMUTH_022 "Detected object azimuth position";
BA_ "GenSigCmt" SG_ 1283 MRR_RL_CAN_DET_CONFID_AZIMU_0037 "Signal to noise level";
BA_ "GenSigVtEn" SG_ 1283 MRR_RL_CAN_DET_CONFID_AZIMU_0037 "TRUE";
BA_ "SystemSignalLongSymbol" SG_ 1283 MRR_RL_CAN_DET_CONFID_AZIMU_0037 "MRR_RL_CAN_DET_CONFID_AZIMUTH_022";
BA_ "GenSigCmt" SG_ 1283 MRR_RL_CAN_DET_RANGE_022 "Detected object range";
BA_ "GenSigCmt" SG_ 1283 MRR_RL_CAN_SCAN_INDEX_2LSB_022 "The two LSB of scan index";
BA_ "GenSigStartValue" SG_ 1283 MRR_RL_CAN_DET_RANGE_RATE_022 8192;
BA_ "GenSigCmt" SG_ 1283 MRR_RL_CAN_DET_RANGE_RATE_022 "Detected object range rate";
BA_ "GenSigCmt" SG_ 1283 MRR_RL_CAN_DET_VALID_LEVEL_022 "Detected object valid level";
BA_ "GenSigStartValue" SG_ 1283 MRR_RL_CAN_DET_AMPLITUDE_022 64;
BA_ "GenSigCmt" SG_ 1283 MRR_RL_CAN_DET_AMPLITUDE_022 "Detected object amplitude";
BA_ "GenSigSendType" SG_ 1282 MRR_RL_CAN_DET_MID_TARGET_021 1;
BA_ "SignalDescription" SG_ 1282 MRR_RL_CAN_DET_MID_TARGET_021 "MID_Target_Discrimination";
BA_ "SignalDescription" SG_ 1282 MRR_RL_CAN_DET_MID_TARGET_020 "MID_Target_Discrimination";
BA_ "SignalDescription" SG_ 1282 MRR_RL_CAN_DET_MID_TARGET_019 "MID_Target_Discrimination";
BA_ "SignalDescription" SG_ 1282 MRR_RL_CAN_DET_MID_TARGET_018 "MID_Target_Discrimination";
BA_ "SignalDescription" SG_ 1282 MRR_RL_CAN_DET_MID_TARGET_017 "MID_Target_Discrimination";
BA_ "SignalDescription" SG_ 1282 MRR_RL_CAN_DET_MID_TARGET_016 "MID_Target_Discrimination";
BA_ "SignalDescription" SG_ 1282 MRR_RL_CAN_DET_MID_TARGET_015 "MID_Target_Discrimination";
BA_ "SignalDescription" SG_ 1282 MRR_RL_CAN_DET_Near_TARGET_015 "Near_Target_Discrimination";
BA_ "SignalDescription" SG_ 1282 MRR_RL_CAN_DET_Near_TARGET_016 "Near_Target_Discrimination";
BA_ "SignalDescription" SG_ 1282 MRR_RL_CAN_DET_Near_TARGET_017 "Near_Target_Discrimination";
BA_ "SignalDescription" SG_ 1282 MRR_RL_CAN_DET_Near_TARGET_018 "Near_Target_Discrimination";
BA_ "SignalDescription" SG_ 1282 MRR_RL_CAN_DET_Near_TARGET_019 "Near_Target_Discrimination";
BA_ "SignalDescription" SG_ 1282 MRR_RL_CAN_DET_Near_TARGET_020 "Near_Target_Discrimination";
BA_ "SignalDescription" SG_ 1282 MRR_RL_CAN_DET_Near_TARGET_021 "Near_Target_Discrimination";
BA_ "GenSigStartValue" SG_ 1282 MRR_RL_CAN_DET_AMPLITUDE_019 64;
BA_ "GenSigCmt" SG_ 1282 MRR_RL_CAN_DET_AMPLITUDE_019 "Detected object amplitude";
BA_ "GenSigCmt" SG_ 1282 MRR_RL_CAN_DET_SUPER_RES_TA_0042 "Super resolution target ";
BA_ "SystemSignalLongSymbol" SG_ 1282 MRR_RL_CAN_DET_SUPER_RES_TA_0042 "MRR_RL_CAN_DET_SUPER_RES_TARGET_021";
BA_ "GenSigStartValue" SG_ 1282 MRR_RL_CAN_DET_ELEVATION_021 63.8646288209607;
BA_ "GenSigCmt" SG_ 1282 MRR_RL_CAN_DET_ELEVATION_021 "Detected object elevation position";
BA_ "GenSigCmt" SG_ 1282 MRR_RL_CAN_DET_HOST_VEH_CLU_0042 "Host vehicle clutter";
BA_ "SystemSignalLongSymbol" SG_ 1282 MRR_RL_CAN_DET_HOST_VEH_CLU_0042 "MRR_RL_CAN_DET_HOST_VEH_CLUTTER_021";
BA_ "GenSigCmt" SG_ 1282 MRR_RL_CAN_DET_CONFID_ELEVA_0042 "Elevation Angle Confidence";
BA_ "SystemSignalLongSymbol" SG_ 1282 MRR_RL_CAN_DET_CONFID_ELEVA_0042 "MRR_RL_CAN_DET_CONFID_ELEVATION_021";
BA_ "GenSigStartValue" SG_ 1282 MRR_RL_CAN_DET_AZIMUTH_021 8194.05320813772;
BA_ "GenSigCmt" SG_ 1282 MRR_RL_CAN_DET_AZIMUTH_021 "Detected object azimuth position";
BA_ "GenSigCmt" SG_ 1282 MRR_RL_CAN_DET_CONFID_AZIMU_0038 "Signal to noise level";
BA_ "GenSigVtEn" SG_ 1282 MRR_RL_CAN_DET_CONFID_AZIMU_0038 "TRUE";
BA_ "SystemSignalLongSymbol" SG_ 1282 MRR_RL_CAN_DET_CONFID_AZIMU_0038 "MRR_RL_CAN_DET_CONFID_AZIMUTH_021";
BA_ "GenSigCmt" SG_ 1282 MRR_RL_CAN_DET_RANGE_021 "Detected object range";
BA_ "GenSigCmt" SG_ 1282 MRR_RL_CAN_SCAN_INDEX_2LSB_021 "The two LSB of scan index";
BA_ "GenSigStartValue" SG_ 1282 MRR_RL_CAN_DET_RANGE_RATE_021 8192;
BA_ "GenSigCmt" SG_ 1282 MRR_RL_CAN_DET_RANGE_RATE_021 "Detected object range rate";
BA_ "GenSigCmt" SG_ 1282 MRR_RL_CAN_DET_VALID_LEVEL_021 "Detected object valid level";
BA_ "GenSigStartValue" SG_ 1282 MRR_RL_CAN_DET_AMPLITUDE_021 64;
BA_ "GenSigCmt" SG_ 1282 MRR_RL_CAN_DET_AMPLITUDE_021 "Detected object amplitude";
BA_ "GenSigCmt" SG_ 1282 MRR_RL_CAN_DET_SUPER_RES_TA_0043 "Super resolution target ";
BA_ "SystemSignalLongSymbol" SG_ 1282 MRR_RL_CAN_DET_SUPER_RES_TA_0043 "MRR_RL_CAN_DET_SUPER_RES_TARGET_020";
BA_ "GenSigStartValue" SG_ 1282 MRR_RL_CAN_DET_ELEVATION_020 63.8646288209607;
BA_ "GenSigCmt" SG_ 1282 MRR_RL_CAN_DET_ELEVATION_020 "Detected object elevation position";
BA_ "GenSigCmt" SG_ 1282 MRR_RL_CAN_DET_HOST_VEH_CLU_0043 "Host vehicle clutter";
BA_ "SystemSignalLongSymbol" SG_ 1282 MRR_RL_CAN_DET_HOST_VEH_CLU_0043 "MRR_RL_CAN_DET_HOST_VEH_CLUTTER_020";
BA_ "GenSigCmt" SG_ 1282 MRR_RL_CAN_DET_CONFID_ELEVA_0043 "Elevation Angle Confidence";
BA_ "SystemSignalLongSymbol" SG_ 1282 MRR_RL_CAN_DET_CONFID_ELEVA_0043 "MRR_RL_CAN_DET_CONFID_ELEVATION_020";
BA_ "GenSigStartValue" SG_ 1282 MRR_RL_CAN_DET_AZIMUTH_020 8194.05320813772;
BA_ "GenSigCmt" SG_ 1282 MRR_RL_CAN_DET_AZIMUTH_020 "Detected object azimuth position";
BA_ "GenSigCmt" SG_ 1282 MRR_RL_CAN_DET_CONFID_AZIMU_0039 "Signal to noise level";
BA_ "GenSigVtEn" SG_ 1282 MRR_RL_CAN_DET_CONFID_AZIMU_0039 "TRUE";
BA_ "SystemSignalLongSymbol" SG_ 1282 MRR_RL_CAN_DET_CONFID_AZIMU_0039 "MRR_RL_CAN_DET_CONFID_AZIMUTH_020";
BA_ "GenSigCmt" SG_ 1282 MRR_RL_CAN_DET_RANGE_020 "Detected object range";
BA_ "GenSigCmt" SG_ 1282 MRR_RL_CAN_SCAN_INDEX_2LSB_020 "The two LSB of scan index";
BA_ "GenSigStartValue" SG_ 1282 MRR_RL_CAN_DET_RANGE_RATE_020 8192;
BA_ "GenSigCmt" SG_ 1282 MRR_RL_CAN_DET_RANGE_RATE_020 "Detected object range rate";
BA_ "GenSigCmt" SG_ 1282 MRR_RL_CAN_DET_VALID_LEVEL_020 "Detected object valid level";
BA_ "GenSigStartValue" SG_ 1282 MRR_RL_CAN_DET_AMPLITUDE_020 64;
BA_ "GenSigCmt" SG_ 1282 MRR_RL_CAN_DET_AMPLITUDE_020 "Detected object amplitude";
BA_ "GenSigCmt" SG_ 1282 MRR_RL_CAN_DET_SUPER_RES_TA_0044 "Super resolution target ";
BA_ "SystemSignalLongSymbol" SG_ 1282 MRR_RL_CAN_DET_SUPER_RES_TA_0044 "MRR_RL_CAN_DET_SUPER_RES_TARGET_019";
BA_ "GenSigStartValue" SG_ 1282 MRR_RL_CAN_DET_ELEVATION_019 63.8646288209607;
BA_ "GenSigCmt" SG_ 1282 MRR_RL_CAN_DET_ELEVATION_019 "Detected object elevation position";
BA_ "GenSigCmt" SG_ 1282 MRR_RL_CAN_DET_HOST_VEH_CLU_0044 "Host vehicle clutter";
BA_ "SystemSignalLongSymbol" SG_ 1282 MRR_RL_CAN_DET_HOST_VEH_CLU_0044 "MRR_RL_CAN_DET_HOST_VEH_CLUTTER_019";
BA_ "GenSigCmt" SG_ 1282 MRR_RL_CAN_DET_CONFID_ELEVA_0044 "Elevation Angle Confidence";
BA_ "SystemSignalLongSymbol" SG_ 1282 MRR_RL_CAN_DET_CONFID_ELEVA_0044 "MRR_RL_CAN_DET_CONFID_ELEVATION_019";
BA_ "GenSigStartValue" SG_ 1282 MRR_RL_CAN_DET_AZIMUTH_019 8194.05320813772;
BA_ "GenSigCmt" SG_ 1282 MRR_RL_CAN_DET_AZIMUTH_019 "Detected object azimuth position";
BA_ "GenSigCmt" SG_ 1282 MRR_RL_CAN_DET_CONFID_AZIMUTH_01 "Signal to noise level";
BA_ "GenSigVtEn" SG_ 1282 MRR_RL_CAN_DET_CONFID_AZIMUTH_01 "TRUE";
BA_ "SystemSignalLongSymbol" SG_ 1282 MRR_RL_CAN_DET_CONFID_AZIMUTH_01 "MRR_RL_CAN_DET_CONFID_AZIMUTH_019";
BA_ "GenSigCmt" SG_ 1282 MRR_RL_CAN_DET_RANGE_019 "Detected object range";
BA_ "GenSigCmt" SG_ 1282 MRR_RL_CAN_SCAN_INDEX_2LSB_019 "The two LSB of scan index";
BA_ "GenSigStartValue" SG_ 1282 MRR_RL_CAN_DET_RANGE_RATE_019 8192;
BA_ "GenSigCmt" SG_ 1282 MRR_RL_CAN_DET_RANGE_RATE_019 "Detected object range rate";
BA_ "GenSigCmt" SG_ 1282 MRR_RL_CAN_DET_VALID_LEVEL_019 "Detected object valid level";
BA_ "GenSigCmt" SG_ 1282 MRR_RL_CAN_DET_SUPER_RES_TA_0045 "Super resolution target ";
BA_ "SystemSignalLongSymbol" SG_ 1282 MRR_RL_CAN_DET_SUPER_RES_TA_0045 "MRR_RL_CAN_DET_SUPER_RES_TARGET_018";
BA_ "GenSigStartValue" SG_ 1282 MRR_RL_CAN_DET_ELEVATION_018 63.8646288209607;
BA_ "GenSigCmt" SG_ 1282 MRR_RL_CAN_DET_ELEVATION_018 "Detected object elevation position";
BA_ "GenSigCmt" SG_ 1282 MRR_RL_CAN_DET_HOST_VEH_CLU_0045 "Host vehicle clutter";
BA_ "SystemSignalLongSymbol" SG_ 1282 MRR_RL_CAN_DET_HOST_VEH_CLU_0045 "MRR_RL_CAN_DET_HOST_VEH_CLUTTER_018";
BA_ "GenSigCmt" SG_ 1282 MRR_RL_CAN_DET_CONFID_ELEVA_0045 "Elevation Angle Confidence";
BA_ "SystemSignalLongSymbol" SG_ 1282 MRR_RL_CAN_DET_CONFID_ELEVA_0045 "MRR_RL_CAN_DET_CONFID_ELEVATION_018";
BA_ "GenSigStartValue" SG_ 1282 MRR_RL_CAN_DET_AZIMUTH_018 8194.05320813772;
BA_ "GenSigCmt" SG_ 1282 MRR_RL_CAN_DET_AZIMUTH_018 "Detected object azimuth position";
BA_ "GenSigCmt" SG_ 1282 MRR_RL_CAN_DET_CONFID_AZIMU_0040 "Signal to noise level";
BA_ "GenSigVtEn" SG_ 1282 MRR_RL_CAN_DET_CONFID_AZIMU_0040 "TRUE";
BA_ "SystemSignalLongSymbol" SG_ 1282 MRR_RL_CAN_DET_CONFID_AZIMU_0040 "MRR_RL_CAN_DET_CONFID_AZIMUTH_018";
BA_ "GenSigCmt" SG_ 1282 MRR_RL_CAN_DET_RANGE_018 "Detected object range";
BA_ "GenSigCmt" SG_ 1282 MRR_RL_CAN_SCAN_INDEX_2LSB_018 "The two LSB of scan index";
BA_ "GenSigStartValue" SG_ 1282 MRR_RL_CAN_DET_RANGE_RATE_018 8192;
BA_ "GenSigCmt" SG_ 1282 MRR_RL_CAN_DET_RANGE_RATE_018 "Detected object range rate";
BA_ "GenSigCmt" SG_ 1282 MRR_RL_CAN_DET_VALID_LEVEL_018 "Detected object valid level";
BA_ "GenSigStartValue" SG_ 1282 MRR_RL_CAN_DET_AMPLITUDE_018 64;
BA_ "GenSigCmt" SG_ 1282 MRR_RL_CAN_DET_AMPLITUDE_018 "Detected object amplitude";
BA_ "GenSigCmt" SG_ 1282 MRR_RL_CAN_DET_SUPER_RES_TA_0046 "Super resolution target ";
BA_ "SystemSignalLongSymbol" SG_ 1282 MRR_RL_CAN_DET_SUPER_RES_TA_0046 "MRR_RL_CAN_DET_SUPER_RES_TARGET_017";
BA_ "GenSigStartValue" SG_ 1282 MRR_RL_CAN_DET_ELEVATION_017 63.8646288209607;
BA_ "GenSigCmt" SG_ 1282 MRR_RL_CAN_DET_ELEVATION_017 "Detected object elevation position";
BA_ "GenSigCmt" SG_ 1282 MRR_RL_CAN_DET_HOST_VEH_CLU_0046 "Host vehicle clutter";
BA_ "SystemSignalLongSymbol" SG_ 1282 MRR_RL_CAN_DET_HOST_VEH_CLU_0046 "MRR_RL_CAN_DET_HOST_VEH_CLUTTER_017";
BA_ "GenSigCmt" SG_ 1282 MRR_RL_CAN_DET_CONFID_ELEVA_0046 "Elevation Angle Confidence";
BA_ "SystemSignalLongSymbol" SG_ 1282 MRR_RL_CAN_DET_CONFID_ELEVA_0046 "MRR_RL_CAN_DET_CONFID_ELEVATION_017";
BA_ "GenSigStartValue" SG_ 1282 MRR_RL_CAN_DET_AZIMUTH_017 8194.05320813772;
BA_ "GenSigCmt" SG_ 1282 MRR_RL_CAN_DET_AZIMUTH_017 "Detected object azimuth position";
BA_ "GenSigCmt" SG_ 1282 MRR_RL_CAN_DET_CONFID_AZIMU_0041 "Signal to noise level";
BA_ "GenSigVtEn" SG_ 1282 MRR_RL_CAN_DET_CONFID_AZIMU_0041 "TRUE";
BA_ "SystemSignalLongSymbol" SG_ 1282 MRR_RL_CAN_DET_CONFID_AZIMU_0041 "MRR_RL_CAN_DET_CONFID_AZIMUTH_017";
BA_ "GenSigCmt" SG_ 1282 MRR_RL_CAN_DET_RANGE_017 "Detected object range";
BA_ "GenSigCmt" SG_ 1282 MRR_RL_CAN_SCAN_INDEX_2LSB_017 "The two LSB of scan index";
BA_ "GenSigStartValue" SG_ 1282 MRR_RL_CAN_DET_RANGE_RATE_017 8192;
BA_ "GenSigCmt" SG_ 1282 MRR_RL_CAN_DET_RANGE_RATE_017 "Detected object range rate";
BA_ "GenSigCmt" SG_ 1282 MRR_RL_CAN_DET_VALID_LEVEL_017 "Detected object valid level";
BA_ "GenSigStartValue" SG_ 1282 MRR_RL_CAN_DET_AMPLITUDE_017 64;
BA_ "GenSigCmt" SG_ 1282 MRR_RL_CAN_DET_AMPLITUDE_017 "Detected object amplitude";
BA_ "GenSigCmt" SG_ 1282 MRR_RL_CAN_DET_SUPER_RES_TA_0047 "Super resolution target ";
BA_ "SystemSignalLongSymbol" SG_ 1282 MRR_RL_CAN_DET_SUPER_RES_TA_0047 "MRR_RL_CAN_DET_SUPER_RES_TARGET_016";
BA_ "GenSigStartValue" SG_ 1282 MRR_RL_CAN_DET_ELEVATION_016 63.8646288209607;
BA_ "GenSigCmt" SG_ 1282 MRR_RL_CAN_DET_ELEVATION_016 "Detected object elevation position";
BA_ "GenSigCmt" SG_ 1282 MRR_RL_CAN_DET_HOST_VEH_CLU_0047 "Host vehicle clutter";
BA_ "SystemSignalLongSymbol" SG_ 1282 MRR_RL_CAN_DET_HOST_VEH_CLU_0047 "MRR_RL_CAN_DET_HOST_VEH_CLUTTER_016";
BA_ "GenSigCmt" SG_ 1282 MRR_RL_CAN_DET_CONFID_ELEVA_0047 "Elevation Angle Confidence";
BA_ "SystemSignalLongSymbol" SG_ 1282 MRR_RL_CAN_DET_CONFID_ELEVA_0047 "MRR_RL_CAN_DET_CONFID_ELEVATION_016";
BA_ "GenSigStartValue" SG_ 1282 MRR_RL_CAN_DET_AZIMUTH_016 8194.05320813772;
BA_ "GenSigCmt" SG_ 1282 MRR_RL_CAN_DET_AZIMUTH_016 "Detected object azimuth position";
BA_ "GenSigCmt" SG_ 1282 MRR_RL_CAN_DET_CONFID_AZIMU_0042 "Signal to noise level";
BA_ "GenSigVtEn" SG_ 1282 MRR_RL_CAN_DET_CONFID_AZIMU_0042 "TRUE";
BA_ "SystemSignalLongSymbol" SG_ 1282 MRR_RL_CAN_DET_CONFID_AZIMU_0042 "MRR_RL_CAN_DET_CONFID_AZIMUTH_016";
BA_ "GenSigCmt" SG_ 1282 MRR_RL_CAN_DET_RANGE_016 "Detected object range";
BA_ "GenSigCmt" SG_ 1282 MRR_RL_CAN_SCAN_INDEX_2LSB_016 "The two LSB of scan index";
BA_ "GenSigStartValue" SG_ 1282 MRR_RL_CAN_DET_RANGE_RATE_016 8192;
BA_ "GenSigCmt" SG_ 1282 MRR_RL_CAN_DET_RANGE_RATE_016 "Detected object range rate";
BA_ "GenSigCmt" SG_ 1282 MRR_RL_CAN_DET_VALID_LEVEL_016 "Detected object valid level";
BA_ "GenSigStartValue" SG_ 1282 MRR_RL_CAN_DET_AMPLITUDE_016 64;
BA_ "GenSigCmt" SG_ 1282 MRR_RL_CAN_DET_AMPLITUDE_016 "Detected object amplitude";
BA_ "GenSigCmt" SG_ 1282 MRR_RL_CAN_DET_SUPER_RES_TA_0048 "Super resolution target ";
BA_ "SystemSignalLongSymbol" SG_ 1282 MRR_RL_CAN_DET_SUPER_RES_TA_0048 "MRR_RL_CAN_DET_SUPER_RES_TARGET_015";
BA_ "GenSigStartValue" SG_ 1282 MRR_RL_CAN_DET_ELEVATION_015 63.8646288209607;
BA_ "GenSigCmt" SG_ 1282 MRR_RL_CAN_DET_ELEVATION_015 "Detected object elevation position";
BA_ "GenSigCmt" SG_ 1282 MRR_RL_CAN_DET_HOST_VEH_CLU_0048 "Host vehicle clutter";
BA_ "SystemSignalLongSymbol" SG_ 1282 MRR_RL_CAN_DET_HOST_VEH_CLU_0048 "MRR_RL_CAN_DET_HOST_VEH_CLUTTER_015";
BA_ "GenSigCmt" SG_ 1282 MRR_RL_CAN_DET_CONFID_ELEVA_0048 "Elevation Angle Confidence";
BA_ "SystemSignalLongSymbol" SG_ 1282 MRR_RL_CAN_DET_CONFID_ELEVA_0048 "MRR_RL_CAN_DET_CONFID_ELEVATION_015";
BA_ "GenSigStartValue" SG_ 1282 MRR_RL_CAN_DET_AZIMUTH_015 8194.05320813772;
BA_ "GenSigCmt" SG_ 1282 MRR_RL_CAN_DET_AZIMUTH_015 "Detected object azimuth position";
BA_ "GenSigCmt" SG_ 1282 MRR_RL_CAN_DET_CONFID_AZIMU_0043 "Signal to noise level";
BA_ "GenSigVtEn" SG_ 1282 MRR_RL_CAN_DET_CONFID_AZIMU_0043 "TRUE";
BA_ "SystemSignalLongSymbol" SG_ 1282 MRR_RL_CAN_DET_CONFID_AZIMU_0043 "MRR_RL_CAN_DET_CONFID_AZIMUTH_015";
BA_ "GenSigCmt" SG_ 1282 MRR_RL_CAN_DET_RANGE_015 "Detected object range";
BA_ "GenSigCmt" SG_ 1282 MRR_RL_CAN_SCAN_INDEX_2LSB_015 "The two LSB of scan index";
BA_ "GenSigStartValue" SG_ 1282 MRR_RL_CAN_DET_RANGE_RATE_015 8192;
BA_ "GenSigCmt" SG_ 1282 MRR_RL_CAN_DET_RANGE_RATE_015 "Detected object range rate";
BA_ "GenSigCmt" SG_ 1282 MRR_RL_CAN_DET_VALID_LEVEL_015 "Detected object valid level";
BA_ "GenSigStartValue" SG_ 1282 MRR_RL_CAN_DET_AMPLITUDE_015 64;
BA_ "GenSigCmt" SG_ 1282 MRR_RL_CAN_DET_AMPLITUDE_015 "Detected object amplitude";
BA_ "GenSigSendType" SG_ 1281 MRR_RL_CAN_DET_MID_TARGET_014 1;
BA_ "SignalDescription" SG_ 1281 MRR_RL_CAN_DET_MID_TARGET_014 "MID_Target_Discrimination";
BA_ "SignalDescription" SG_ 1281 MRR_RL_CAN_DET_MID_TARGET_013 "MID_Target_Discrimination";
BA_ "SignalDescription" SG_ 1281 MRR_RL_CAN_DET_MID_TARGET_012 "MID_Target_Discrimination";
BA_ "SignalDescription" SG_ 1281 MRR_RL_CAN_DET_MID_TARGET_011 "MID_Target_Discrimination";
BA_ "SignalDescription" SG_ 1281 MRR_RL_CAN_DET_MID_TARGET_010 "MID_Target_Discrimination";
BA_ "SignalDescription" SG_ 1281 MRR_RL_CAN_DET_MID_TARGET_009 "MID_Target_Discrimination";
BA_ "SignalDescription" SG_ 1281 MRR_RL_CAN_DET_MID_TARGET_008 "MID_Target_Discrimination";
BA_ "SignalDescription" SG_ 1281 MRR_RL_CAN_DET_Near_TARGET_008 "Near_Target_Discrimination";
BA_ "SignalDescription" SG_ 1281 MRR_RL_CAN_DET_Near_TARGET_009 "Near_Target_Discrimination";
BA_ "SignalDescription" SG_ 1281 MRR_RL_CAN_DET_Near_TARGET_010 "Near_Target_Discrimination";
BA_ "SignalDescription" SG_ 1281 MRR_RL_CAN_DET_Near_TARGET_011 "Near_Target_Discrimination";
BA_ "SignalDescription" SG_ 1281 MRR_RL_CAN_DET_Near_TARGET_012 "Near_Target_Discrimination";
BA_ "SignalDescription" SG_ 1281 MRR_RL_CAN_DET_Near_TARGET_013 "Near_Target_Discrimination";
BA_ "SignalDescription" SG_ 1281 MRR_RL_CAN_DET_Near_TARGET_014 "Near_Target_Discrimination";
BA_ "GenSigCmt" SG_ 1281 MRR_RL_CAN_DET_SUPER_RES_TA_0049 "Super resolution target ";
BA_ "SystemSignalLongSymbol" SG_ 1281 MRR_RL_CAN_DET_SUPER_RES_TA_0049 "MRR_RL_CAN_DET_SUPER_RES_TARGET_014";
BA_ "GenSigStartValue" SG_ 1281 MRR_RL_CAN_DET_ELEVATION_014 63.8646288209607;
BA_ "GenSigCmt" SG_ 1281 MRR_RL_CAN_DET_ELEVATION_014 "Detected object elevation position";
BA_ "GenSigCmt" SG_ 1281 MRR_RL_CAN_DET_HOST_VEH_CLU_0049 "Host vehicle clutter";
BA_ "SystemSignalLongSymbol" SG_ 1281 MRR_RL_CAN_DET_HOST_VEH_CLU_0049 "MRR_RL_CAN_DET_HOST_VEH_CLUTTER_014";
BA_ "GenSigCmt" SG_ 1281 MRR_RL_CAN_DET_CONFID_ELEVA_0049 "Elevation Angle Confidence";
BA_ "SystemSignalLongSymbol" SG_ 1281 MRR_RL_CAN_DET_CONFID_ELEVA_0049 "MRR_RL_CAN_DET_CONFID_ELEVATION_014";
BA_ "GenSigStartValue" SG_ 1281 MRR_RL_CAN_DET_AZIMUTH_014 8194.05320813772;
BA_ "GenSigCmt" SG_ 1281 MRR_RL_CAN_DET_AZIMUTH_014 "Detected object azimuth position";
BA_ "GenSigCmt" SG_ 1281 MRR_RL_CAN_DET_CONFID_AZIMU_0044 "Signal to noise level";
BA_ "GenSigVtEn" SG_ 1281 MRR_RL_CAN_DET_CONFID_AZIMU_0044 "TRUE";
BA_ "SystemSignalLongSymbol" SG_ 1281 MRR_RL_CAN_DET_CONFID_AZIMU_0044 "MRR_RL_CAN_DET_CONFID_AZIMUTH_014";
BA_ "GenSigCmt" SG_ 1281 MRR_RL_CAN_DET_RANGE_014 "Detected object range";
BA_ "GenSigCmt" SG_ 1281 MRR_RL_CAN_SCAN_INDEX_2LSB_014 "The two LSB of scan index";
BA_ "GenSigStartValue" SG_ 1281 MRR_RL_CAN_DET_RANGE_RATE_014 8192;
BA_ "GenSigCmt" SG_ 1281 MRR_RL_CAN_DET_RANGE_RATE_014 "Detected object range rate";
BA_ "GenSigCmt" SG_ 1281 MRR_RL_CAN_DET_VALID_LEVEL_014 "Detected object valid level";
BA_ "GenSigStartValue" SG_ 1281 MRR_RL_CAN_DET_AMPLITUDE_014 64;
BA_ "GenSigCmt" SG_ 1281 MRR_RL_CAN_DET_AMPLITUDE_014 "Detected object amplitude";
BA_ "GenSigCmt" SG_ 1281 MRR_RL_CAN_DET_SUPER_RES_TA_0050 "Super resolution target ";
BA_ "SystemSignalLongSymbol" SG_ 1281 MRR_RL_CAN_DET_SUPER_RES_TA_0050 "MRR_RL_CAN_DET_SUPER_RES_TARGET_013";
BA_ "GenSigStartValue" SG_ 1281 MRR_RL_CAN_DET_ELEVATION_013 63.8646288209607;
BA_ "GenSigCmt" SG_ 1281 MRR_RL_CAN_DET_ELEVATION_013 "Detected object elevation position";
BA_ "GenSigCmt" SG_ 1281 MRR_RL_CAN_DET_HOST_VEH_CLU_0050 "Host vehicle clutter";
BA_ "SystemSignalLongSymbol" SG_ 1281 MRR_RL_CAN_DET_HOST_VEH_CLU_0050 "MRR_RL_CAN_DET_HOST_VEH_CLUTTER_013";
BA_ "GenSigCmt" SG_ 1281 MRR_RL_CAN_DET_CONFID_ELEVA_0050 "Elevation Angle Confidence";
BA_ "SystemSignalLongSymbol" SG_ 1281 MRR_RL_CAN_DET_CONFID_ELEVA_0050 "MRR_RL_CAN_DET_CONFID_ELEVATION_013";
BA_ "GenSigStartValue" SG_ 1281 MRR_RL_CAN_DET_AZIMUTH_013 8194.05320813772;
BA_ "GenSigCmt" SG_ 1281 MRR_RL_CAN_DET_AZIMUTH_013 "Detected object azimuth position";
BA_ "GenSigCmt" SG_ 1281 MRR_RL_CAN_DET_CONFID_AZIMU_0045 "Signal to noise level";
BA_ "GenSigVtEn" SG_ 1281 MRR_RL_CAN_DET_CONFID_AZIMU_0045 "TRUE";
BA_ "SystemSignalLongSymbol" SG_ 1281 MRR_RL_CAN_DET_CONFID_AZIMU_0045 "MRR_RL_CAN_DET_CONFID_AZIMUTH_013";
BA_ "GenSigCmt" SG_ 1281 MRR_RL_CAN_DET_RANGE_013 "Detected object range";
BA_ "GenSigCmt" SG_ 1281 MRR_RL_CAN_SCAN_INDEX_2LSB_013 "The two LSB of scan index";
BA_ "GenSigStartValue" SG_ 1281 MRR_RL_CAN_DET_RANGE_RATE_013 8192;
BA_ "GenSigCmt" SG_ 1281 MRR_RL_CAN_DET_RANGE_RATE_013 "Detected object range rate";
BA_ "GenSigCmt" SG_ 1281 MRR_RL_CAN_DET_VALID_LEVEL_013 "Detected object valid level";
BA_ "GenSigStartValue" SG_ 1281 MRR_RL_CAN_DET_AMPLITUDE_013 64;
BA_ "GenSigCmt" SG_ 1281 MRR_RL_CAN_DET_AMPLITUDE_013 "Detected object amplitude";
BA_ "GenSigCmt" SG_ 1281 MRR_RL_CAN_DET_SUPER_RES_TA_0051 "Super resolution target ";
BA_ "SystemSignalLongSymbol" SG_ 1281 MRR_RL_CAN_DET_SUPER_RES_TA_0051 "MRR_RL_CAN_DET_SUPER_RES_TARGET_012";
BA_ "GenSigStartValue" SG_ 1281 MRR_RL_CAN_DET_ELEVATION_012 63.8646288209607;
BA_ "GenSigCmt" SG_ 1281 MRR_RL_CAN_DET_ELEVATION_012 "Detected object elevation position";
BA_ "GenSigCmt" SG_ 1281 MRR_RL_CAN_DET_HOST_VEH_CLU_0051 "Host vehicle clutter";
BA_ "SystemSignalLongSymbol" SG_ 1281 MRR_RL_CAN_DET_HOST_VEH_CLU_0051 "MRR_RL_CAN_DET_HOST_VEH_CLUTTER_012";
BA_ "GenSigCmt" SG_ 1281 MRR_RL_CAN_DET_CONFID_ELEVA_0051 "Elevation Angle Confidence";
BA_ "SystemSignalLongSymbol" SG_ 1281 MRR_RL_CAN_DET_CONFID_ELEVA_0051 "MRR_RL_CAN_DET_CONFID_ELEVATION_012";
BA_ "GenSigStartValue" SG_ 1281 MRR_RL_CAN_DET_AZIMUTH_012 8194.05320813772;
BA_ "GenSigCmt" SG_ 1281 MRR_RL_CAN_DET_AZIMUTH_012 "Detected object azimuth position";
BA_ "GenSigCmt" SG_ 1281 MRR_RL_CAN_DET_CONFID_AZIMU_0046 "Signal to noise level";
BA_ "GenSigVtEn" SG_ 1281 MRR_RL_CAN_DET_CONFID_AZIMU_0046 "TRUE";
BA_ "SystemSignalLongSymbol" SG_ 1281 MRR_RL_CAN_DET_CONFID_AZIMU_0046 "MRR_RL_CAN_DET_CONFID_AZIMUTH_012";
BA_ "GenSigCmt" SG_ 1281 MRR_RL_CAN_DET_RANGE_012 "Detected object range";
BA_ "GenSigCmt" SG_ 1281 MRR_RL_CAN_SCAN_INDEX_2LSB_012 "The two LSB of scan index";
BA_ "GenSigStartValue" SG_ 1281 MRR_RL_CAN_DET_RANGE_RATE_012 8192;
BA_ "GenSigCmt" SG_ 1281 MRR_RL_CAN_DET_RANGE_RATE_012 "Detected object range rate";
BA_ "GenSigCmt" SG_ 1281 MRR_RL_CAN_DET_VALID_LEVEL_012 "Detected object valid level";
BA_ "GenSigStartValue" SG_ 1281 MRR_RL_CAN_DET_AMPLITUDE_012 64;
BA_ "GenSigCmt" SG_ 1281 MRR_RL_CAN_DET_AMPLITUDE_012 "Detected object amplitude";
BA_ "GenSigCmt" SG_ 1281 MRR_RL_CAN_DET_SUPER_RES_TA_0052 "Super resolution target ";
BA_ "SystemSignalLongSymbol" SG_ 1281 MRR_RL_CAN_DET_SUPER_RES_TA_0052 "MRR_RL_CAN_DET_SUPER_RES_TARGET_011";
BA_ "GenSigStartValue" SG_ 1281 MRR_RL_CAN_DET_ELEVATION_011 63.8646288209607;
BA_ "GenSigCmt" SG_ 1281 MRR_RL_CAN_DET_ELEVATION_011 "Detected object elevation position";
BA_ "GenSigCmt" SG_ 1281 MRR_RL_CAN_DET_HOST_VEH_CLU_0052 "Host vehicle clutter";
BA_ "SystemSignalLongSymbol" SG_ 1281 MRR_RL_CAN_DET_HOST_VEH_CLU_0052 "MRR_RL_CAN_DET_HOST_VEH_CLUTTER_011";
BA_ "GenSigCmt" SG_ 1281 MRR_RL_CAN_DET_CONFID_ELEVA_0052 "Elevation Angle Confidence";
BA_ "SystemSignalLongSymbol" SG_ 1281 MRR_RL_CAN_DET_CONFID_ELEVA_0052 "MRR_RL_CAN_DET_CONFID_ELEVATION_011";
BA_ "GenSigStartValue" SG_ 1281 MRR_RL_CAN_DET_AZIMUTH_011 8194.05320813772;
BA_ "GenSigCmt" SG_ 1281 MRR_RL_CAN_DET_AZIMUTH_011 "Detected object azimuth position";
BA_ "GenSigCmt" SG_ 1281 MRR_RL_CAN_DET_CONFID_AZIMU_0047 "Signal to noise level";
BA_ "GenSigVtEn" SG_ 1281 MRR_RL_CAN_DET_CONFID_AZIMU_0047 "TRUE";
BA_ "SystemSignalLongSymbol" SG_ 1281 MRR_RL_CAN_DET_CONFID_AZIMU_0047 "MRR_RL_CAN_DET_CONFID_AZIMUTH_011";
BA_ "GenSigCmt" SG_ 1281 MRR_RL_CAN_DET_RANGE_011 "Detected object range";
BA_ "GenSigCmt" SG_ 1281 MRR_RL_CAN_SCAN_INDEX_2LSB_011 "The two LSB of scan index";
BA_ "GenSigStartValue" SG_ 1281 MRR_RL_CAN_DET_RANGE_RATE_011 8192;
BA_ "GenSigCmt" SG_ 1281 MRR_RL_CAN_DET_RANGE_RATE_011 "Detected object range rate";
BA_ "GenSigCmt" SG_ 1281 MRR_RL_CAN_DET_VALID_LEVEL_011 "Detected object valid level";
BA_ "GenSigStartValue" SG_ 1281 MRR_RL_CAN_DET_AMPLITUDE_011 64;
BA_ "GenSigCmt" SG_ 1281 MRR_RL_CAN_DET_AMPLITUDE_011 "Detected object amplitude";
BA_ "GenSigCmt" SG_ 1281 MRR_RL_CAN_DET_SUPER_RES_TA_0053 "Super resolution target ";
BA_ "SystemSignalLongSymbol" SG_ 1281 MRR_RL_CAN_DET_SUPER_RES_TA_0053 "MRR_RL_CAN_DET_SUPER_RES_TARGET_010";
BA_ "GenSigStartValue" SG_ 1281 MRR_RL_CAN_DET_ELEVATION_010 63.8646288209607;
BA_ "GenSigCmt" SG_ 1281 MRR_RL_CAN_DET_ELEVATION_010 "Detected object elevation position";
BA_ "GenSigCmt" SG_ 1281 MRR_RL_CAN_DET_HOST_VEH_CLU_0053 "Host vehicle clutter";
BA_ "SystemSignalLongSymbol" SG_ 1281 MRR_RL_CAN_DET_HOST_VEH_CLU_0053 "MRR_RL_CAN_DET_HOST_VEH_CLUTTER_010";
BA_ "GenSigCmt" SG_ 1281 MRR_RL_CAN_DET_CONFID_ELEVA_0053 "Elevation Angle Confidence";
BA_ "SystemSignalLongSymbol" SG_ 1281 MRR_RL_CAN_DET_CONFID_ELEVA_0053 "MRR_RL_CAN_DET_CONFID_ELEVATION_010";
BA_ "GenSigStartValue" SG_ 1281 MRR_RL_CAN_DET_AZIMUTH_010 8194.05320813772;
BA_ "GenSigCmt" SG_ 1281 MRR_RL_CAN_DET_AZIMUTH_010 "Detected object azimuth position";
BA_ "GenSigCmt" SG_ 1281 MRR_RL_CAN_DET_CONFID_AZIMU_0048 "Signal to noise level";
BA_ "GenSigVtEn" SG_ 1281 MRR_RL_CAN_DET_CONFID_AZIMU_0048 "TRUE";
BA_ "SystemSignalLongSymbol" SG_ 1281 MRR_RL_CAN_DET_CONFID_AZIMU_0048 "MRR_RL_CAN_DET_CONFID_AZIMUTH_010";
BA_ "GenSigCmt" SG_ 1281 MRR_RL_CAN_DET_RANGE_010 "Detected object range";
BA_ "GenSigCmt" SG_ 1281 MRR_RL_CAN_SCAN_INDEX_2LSB_010 "The two LSB of scan index";
BA_ "GenSigStartValue" SG_ 1281 MRR_RL_CAN_DET_RANGE_RATE_010 8192;
BA_ "GenSigCmt" SG_ 1281 MRR_RL_CAN_DET_RANGE_RATE_010 "Detected object range rate";
BA_ "GenSigCmt" SG_ 1281 MRR_RL_CAN_DET_VALID_LEVEL_010 "Detected object valid level";
BA_ "GenSigStartValue" SG_ 1281 MRR_RL_CAN_DET_AMPLITUDE_010 64;
BA_ "GenSigCmt" SG_ 1281 MRR_RL_CAN_DET_AMPLITUDE_010 "Detected object amplitude";
BA_ "GenSigCmt" SG_ 1281 MRR_RL_CAN_DET_SUPER_RES_TA_0054 "Super resolution target ";
BA_ "SystemSignalLongSymbol" SG_ 1281 MRR_RL_CAN_DET_SUPER_RES_TA_0054 "MRR_RL_CAN_DET_SUPER_RES_TARGET_009";
BA_ "GenSigStartValue" SG_ 1281 MRR_RL_CAN_DET_ELEVATION_009 63.8646288209607;
BA_ "GenSigCmt" SG_ 1281 MRR_RL_CAN_DET_ELEVATION_009 "Detected object elevation position";
BA_ "GenSigCmt" SG_ 1281 MRR_RL_CAN_DET_HOST_VEH_CLU_0054 "Host vehicle clutter";
BA_ "SystemSignalLongSymbol" SG_ 1281 MRR_RL_CAN_DET_HOST_VEH_CLU_0054 "MRR_RL_CAN_DET_HOST_VEH_CLUTTER_009";
BA_ "GenSigCmt" SG_ 1281 MRR_RL_CAN_DET_CONFID_ELEVA_0054 "Elevation Angle Confidence";
BA_ "SystemSignalLongSymbol" SG_ 1281 MRR_RL_CAN_DET_CONFID_ELEVA_0054 "MRR_RL_CAN_DET_CONFID_ELEVATION_009";
BA_ "GenSigStartValue" SG_ 1281 MRR_RL_CAN_DET_AZIMUTH_009 8194.05320813772;
BA_ "GenSigCmt" SG_ 1281 MRR_RL_CAN_DET_AZIMUTH_009 "Detected object azimuth position";
BA_ "GenSigCmt" SG_ 1281 MRR_RL_CAN_DET_CONFID_AZIMUTH_00 "Signal to noise level";
BA_ "GenSigVtEn" SG_ 1281 MRR_RL_CAN_DET_CONFID_AZIMUTH_00 "TRUE";
BA_ "SystemSignalLongSymbol" SG_ 1281 MRR_RL_CAN_DET_CONFID_AZIMUTH_00 "MRR_RL_CAN_DET_CONFID_AZIMUTH_009";
BA_ "GenSigCmt" SG_ 1281 MRR_RL_CAN_DET_RANGE_009 "Detected object range";
BA_ "GenSigCmt" SG_ 1281 MRR_RL_CAN_SCAN_INDEX_2LSB_009 "The two LSB of scan index";
BA_ "GenSigStartValue" SG_ 1281 MRR_RL_CAN_DET_RANGE_RATE_009 8192;
BA_ "GenSigCmt" SG_ 1281 MRR_RL_CAN_DET_RANGE_RATE_009 "Detected object range rate";
BA_ "GenSigCmt" SG_ 1281 MRR_RL_CAN_DET_VALID_LEVEL_009 "Detected object valid level";
BA_ "GenSigStartValue" SG_ 1281 MRR_RL_CAN_DET_AMPLITUDE_009 64;
BA_ "GenSigCmt" SG_ 1281 MRR_RL_CAN_DET_AMPLITUDE_009 "Detected object amplitude";
BA_ "GenSigCmt" SG_ 1281 MRR_RL_CAN_DET_SUPER_RES_TA_0055 "Super resolution target ";
BA_ "SystemSignalLongSymbol" SG_ 1281 MRR_RL_CAN_DET_SUPER_RES_TA_0055 "MRR_RL_CAN_DET_SUPER_RES_TARGET_008";
BA_ "GenSigStartValue" SG_ 1281 MRR_RL_CAN_DET_ELEVATION_008 63.8646288209607;
BA_ "GenSigCmt" SG_ 1281 MRR_RL_CAN_DET_ELEVATION_008 "Detected object elevation position";
BA_ "GenSigCmt" SG_ 1281 MRR_RL_CAN_DET_HOST_VEH_CLU_0055 "Host vehicle clutter";
BA_ "SystemSignalLongSymbol" SG_ 1281 MRR_RL_CAN_DET_HOST_VEH_CLU_0055 "MRR_RL_CAN_DET_HOST_VEH_CLUTTER_008";
BA_ "GenSigCmt" SG_ 1281 MRR_RL_CAN_DET_CONFID_ELEVA_0055 "Elevation Angle Confidence";
BA_ "SystemSignalLongSymbol" SG_ 1281 MRR_RL_CAN_DET_CONFID_ELEVA_0055 "MRR_RL_CAN_DET_CONFID_ELEVATION_008";
BA_ "GenSigStartValue" SG_ 1281 MRR_RL_CAN_DET_AZIMUTH_008 8194.05320813772;
BA_ "GenSigCmt" SG_ 1281 MRR_RL_CAN_DET_AZIMUTH_008 "Detected object azimuth position";
BA_ "GenSigCmt" SG_ 1281 MRR_RL_CAN_DET_CONFID_AZIMU_0049 "Signal to noise level";
BA_ "GenSigVtEn" SG_ 1281 MRR_RL_CAN_DET_CONFID_AZIMU_0049 "TRUE";
BA_ "SystemSignalLongSymbol" SG_ 1281 MRR_RL_CAN_DET_CONFID_AZIMU_0049 "MRR_RL_CAN_DET_CONFID_AZIMUTH_008";
BA_ "GenSigCmt" SG_ 1281 MRR_RL_CAN_DET_RANGE_008 "Detected object range";
BA_ "GenSigCmt" SG_ 1281 MRR_RL_CAN_SCAN_INDEX_2LSB_008 "The two LSB of scan index";
BA_ "GenSigStartValue" SG_ 1281 MRR_RL_CAN_DET_RANGE_RATE_008 8192;
BA_ "GenSigCmt" SG_ 1281 MRR_RL_CAN_DET_RANGE_RATE_008 "Detected object range rate";
BA_ "GenSigCmt" SG_ 1281 MRR_RL_CAN_DET_VALID_LEVEL_008 "Detected object valid level";
BA_ "GenSigStartValue" SG_ 1281 MRR_RL_CAN_DET_AMPLITUDE_008 64;
BA_ "GenSigCmt" SG_ 1281 MRR_RL_CAN_DET_AMPLITUDE_008 "Detected object amplitude";
BA_ "GenSigSendType" SG_ 323 MRR_RL_Alignment_Status_CRC 0;
BA_ "GenSigCycleTime" SG_ 323 MRR_RL_Alignment_Status_CRC 50;
BA_ "GenSigSendType" SG_ 323 MRR_RL_Alignment_Status_MC 0;
BA_ "GenSigCycleTime" SG_ 323 MRR_RL_Alignment_Status_MC 50;
BA_ "GenSigSendType" SG_ 323 MRR_RL_CAN_TX_Temperature 0;
BA_ "GenSigCycleTime" SG_ 323 MRR_RL_CAN_TX_Temperature 50;
BA_ "GenSigSendType" SG_ 323 MRR_RL_CAN_TX_YAW_RATE_BIAS 0;
BA_ "GenSigCycleTime" SG_ 323 MRR_RL_CAN_TX_YAW_RATE_BIAS 50;
BA_ "GenSigSendType" SG_ 323 MRR_RL_CAN_TX_VEH_SPD_COMP_FACTO 0;
BA_ "GenSigCycleTime" SG_ 323 MRR_RL_CAN_TX_VEH_SPD_COMP_FACTO 50;
BA_ "SystemSignalLongSymbol" SG_ 323 MRR_RL_CAN_TX_VEH_SPD_COMP_FACTO "MRR_RL_CAN_TX_VEH_SPD_COMP_FACTOR";
BA_ "GenSigSendType" SG_ 323 MRR_RL_CAN_TX_DRIVING_ENVIRONMEN 0;
BA_ "GenSigCycleTime" SG_ 323 MRR_RL_CAN_TX_DRIVING_ENVIRONMEN 50;
BA_ "SystemSignalLongSymbol" SG_ 323 MRR_RL_CAN_TX_DRIVING_ENVIRONMEN "MRR_RL_CAN_TX_DRIVING_ENVIRONMENT";
BA_ "GenSigSendType" SG_ 323 MRR_RL_CAN_TX_Alignment_MODE 0;
BA_ "GenSigCycleTime" SG_ 323 MRR_RL_CAN_TX_Alignment_MODE 50;
BA_ "GenSigSendType" SG_ 323 MRR_RL_CAN_TX_AUTO_ALIGN_QUA_FAC 0;
BA_ "GenSigCycleTime" SG_ 323 MRR_RL_CAN_TX_AUTO_ALIGN_QUA_FAC 50;
BA_ "SystemSignalLongSymbol" SG_ 323 MRR_RL_CAN_TX_AUTO_ALIGN_QUA_FAC "MRR_RL_CAN_TX_AUTO_ALIGN_QUA_FACTOR";
BA_ "GenSigSendType" SG_ 323 MRR_RL_CAN_TX_ROLLING_COUNT_1 0;
BA_ "GenSigCycleTime" SG_ 323 MRR_RL_CAN_TX_ROLLING_COUNT_1 50;
BA_ "GenSigSendType" SG_ 323 MRR_RL_CAN_TX_CURRENT_MISALIGN_A 0;
BA_ "GenSigCycleTime" SG_ 323 MRR_RL_CAN_TX_CURRENT_MISALIGN_A 50;
BA_ "SystemSignalLongSymbol" SG_ 323 MRR_RL_CAN_TX_CURRENT_MISALIGN_A "MRR_RL_CAN_TX_CURRENT_MISALIGN_ANGLE";
BA_ "GenSigSendType" SG_ 323 MRR_RL_CAN_TX_SAVED_MISALIGN_ANG 0;
BA_ "GenSigCycleTime" SG_ 323 MRR_RL_CAN_TX_SAVED_MISALIGN_ANG 50;
BA_ "SystemSignalLongSymbol" SG_ 323 MRR_RL_CAN_TX_SAVED_MISALIGN_ANG "MRR_RL_CAN_TX_SAVED_MISALIGN_ANGLE";
BA_ "GenSigCycleTime" SG_ 1346 SensorCfg_MRRFR_AlignRngTolVert 1000;
BA_ "GenSigSendType" SG_ 1346 SensorCfg_MRRFR_AlignRngTolVert 0;
BA_ "GenSigCycleTime" SG_ 1346 SensorCfg_MRRFL_AlignRngTolVert 1000;
BA_ "GenSigSendType" SG_ 1346 SensorCfg_MRRFL_AlignRngTolVert 0;
BA_ "GenSigCycleTime" SG_ 1346 SensorCfg_MRRRR_AlignRngTolVert 1000;
BA_ "GenSigSendType" SG_ 1346 SensorCfg_MRRRR_AlignRngTolVert 0;
BA_ "GenSigCycleTime" SG_ 1346 SensorCfg_MRRRL_AlignRngTolVert 1000;
BA_ "GenSigSendType" SG_ 1346 SensorCfg_MRRRL_AlignRngTolVert 0;
BA_ "GenSigCycleTime" SG_ 1346 SensorCfg_MRRFR_AlignRngTolHorz 1000;
BA_ "GenSigSendType" SG_ 1346 SensorCfg_MRRFR_AlignRngTolHorz 0;
BA_ "GenSigCycleTime" SG_ 1346 SensorCfg_MRRFL_AlignRngTolHorz 1000;
BA_ "GenSigSendType" SG_ 1346 SensorCfg_MRRFL_AlignRngTolHorz 0;
BA_ "GenSigCycleTime" SG_ 1346 SensorCfg_MRRRR_AlignRngTolHorz 1000;
BA_ "GenSigSendType" SG_ 1346 SensorCfg_MRRRR_AlignRngTolHorz 0;
BA_ "GenSigCycleTime" SG_ 1346 SensorCfg_MRRRL_AlignRngTolHorz 1000;
BA_ "GenSigSendType" SG_ 1346 SensorCfg_MRRRL_AlignRngTolHorz 0;
BA_ "GenSigCycleTime" SG_ 1346 MRR_SENSR_CFG_CRC 1000;
BA_ "GenSigSendType" SG_ 1346 MRR_SENSR_CFG_CRC 0;
BA_ "GenSigSendType" SG_ 1346 SensorCfg_MRRFR_Pitch 0;
BA_ "GenSigCycleTime" SG_ 1346 SensorCfg_MRRFR_Pitch 1000;
BA_ "GenSigSendType" SG_ 1346 SensorCfg_MRRRR_Pitch 0;
BA_ "GenSigCycleTime" SG_ 1346 SensorCfg_MRRRR_Pitch 1000;
BA_ "GenSigSendType" SG_ 1346 SensorCfg_MRRFL_Pitch 0;
BA_ "GenSigCycleTime" SG_ 1346 SensorCfg_MRRFL_Pitch 1000;
BA_ "GenSigSendType" SG_ 1346 SensorCfg_MRRRL_Pitch 0;
BA_ "GenSigCycleTime" SG_ 1346 SensorCfg_MRRRL_Pitch 1000;
BA_ "GenSigSendType" SG_ 1346 SensorCfg_MRRRL_LatPos 0;
BA_ "GenSigCycleTime" SG_ 1346 SensorCfg_MRRRL_LatPos 1000;
BA_ "GenSigSendType" SG_ 1346 SensorCfg_MRRRR_LatPos 0;
BA_ "GenSigCycleTime" SG_ 1346 SensorCfg_MRRRR_LatPos 1000;
BA_ "GenSigSendType" SG_ 1346 SensorCfg_MRRFL_LatPos 0;
BA_ "GenSigCycleTime" SG_ 1346 SensorCfg_MRRFL_LatPos 1000;
BA_ "GenSigSendType" SG_ 1346 SensorCfg_MRRFR_LatPos 0;
BA_ "GenSigCycleTime" SG_ 1346 SensorCfg_MRRFR_LatPos 1000;
BA_ "GenSigSendType" SG_ 1346 SensorCfg_MRRRL_LongPos 0;
BA_ "GenSigCycleTime" SG_ 1346 SensorCfg_MRRRL_LongPos 1000;
BA_ "GenSigSendType" SG_ 1346 SensorCfg_MRRRR_LongPos 0;
BA_ "GenSigCycleTime" SG_ 1346 SensorCfg_MRRRR_LongPos 1000;
BA_ "GenSigSendType" SG_ 1346 SensorCfg_MRRFL_LongPos 0;
BA_ "GenSigCycleTime" SG_ 1346 SensorCfg_MRRFL_LongPos 1000;
BA_ "GenSigSendType" SG_ 1346 SensorCfg_MRRFR_LongPos 0;
BA_ "GenSigCycleTime" SG_ 1346 SensorCfg_MRRFR_LongPos 1000;
BA_ "GenSigSendType" SG_ 1346 SensorCfg_MRRRL_VertPos 0;
BA_ "GenSigCycleTime" SG_ 1346 SensorCfg_MRRRL_VertPos 1000;
BA_ "GenSigSendType" SG_ 1346 SensorCfg_MRRRR_VertPos 0;
BA_ "GenSigCycleTime" SG_ 1346 SensorCfg_MRRRR_VertPos 1000;
BA_ "GenSigSendType" SG_ 1346 SensorCfg_MRRFL_VertPos 0;
BA_ "GenSigCycleTime" SG_ 1346 SensorCfg_MRRFL_VertPos 1000;
BA_ "GenSigSendType" SG_ 1346 SensorCfg_MRRFR_VertPos 0;
BA_ "GenSigCycleTime" SG_ 1346 SensorCfg_MRRFR_VertPos 1000;
BA_ "GenSigSendType" SG_ 1346 SensorCfg_MRRRL_Yaw 0;
BA_ "GenSigCycleTime" SG_ 1346 SensorCfg_MRRRL_Yaw 1000;
BA_ "GenSigSendType" SG_ 1346 SensorCfg_MRRRR_Yaw 0;
BA_ "GenSigCycleTime" SG_ 1346 SensorCfg_MRRRR_Yaw 1000;
BA_ "GenSigSendType" SG_ 1346 SensorCfg_MRRFL_Yaw 0;
BA_ "GenSigCycleTime" SG_ 1346 SensorCfg_MRRFL_Yaw 1000;
BA_ "GenSigSendType" SG_ 1346 SensorCfg_MRRFR_Yaw 0;
BA_ "GenSigCycleTime" SG_ 1346 SensorCfg_MRRFR_Yaw 1000;
BA_ "GenSigSendType" SG_ 1346 SensorCfg_MRRRL_Orientation 0;
BA_ "GenSigCycleTime" SG_ 1346 SensorCfg_MRRRL_Orientation 1000;
BA_ "GenSigSendType" SG_ 1346 SensorCfg_MRRRR_Orientation 0;
BA_ "GenSigCycleTime" SG_ 1346 SensorCfg_MRRRR_Orientation 1000;
BA_ "GenSigSendType" SG_ 1346 SensorCfg_MRRFL_Orientation 0;
BA_ "GenSigCycleTime" SG_ 1346 SensorCfg_MRRFL_Orientation 1000;
BA_ "GenSigSendType" SG_ 1346 SensorCfg_MRRFR_Orientation 0;
BA_ "GenSigCycleTime" SG_ 1346 SensorCfg_MRRFR_Orientation 1000;
BA_ "GenSigSendType" SG_ 20 RadarWaveform_MRRRR 0;
BA_ "GenSigCycleTime" SG_ 20 RadarWaveform_MRRRR 25;
BA_ "GenSigSendType" SG_ 20 MRR_RR_CAN_NUMBER_OF_TRACKS_STAT 0;
BA_ "GenSigCycleTime" SG_ 20 MRR_RR_CAN_NUMBER_OF_TRACKS_STAT 25;
BA_ "GenSigSendType" SG_ 20 MRR_RR_CAN_NUMBER_OF_TRACKS_MOV 0;
BA_ "GenSigCycleTime" SG_ 20 MRR_RR_CAN_NUMBER_OF_TRACKS_MOV 25;
BA_ "GenSigSendType" SG_ 20 MRR_RR_CAN_TD_SCAN_COUNTER 0;
BA_ "GenSigCycleTime" SG_ 20 MRR_RR_CAN_TD_SCAN_COUNTER 25;
BA_ "GenSigSendType" SG_ 20 MRR_RR_CAN_FOUND_TARGET 0;
BA_ "GenSigCycleTime" SG_ 20 MRR_RR_CAN_FOUND_TARGET 25;
BA_ "GenSigSendType" SG_ 20 MRR_RR_CAN_BLOCKAGE_TD 0;
BA_ "GenSigCycleTime" SG_ 20 MRR_RR_CAN_BLOCKAGE_TD 25;
BA_ "GenSigSendType" SG_ 21 RadarWaveform_MRRRL 0;
BA_ "GenSigCycleTime" SG_ 21 RadarWaveform_MRRRL 25;
BA_ "GenSigSendType" SG_ 21 MRR_RL_CAN_NUMBER_OF_TRACKS_STAT 0;
BA_ "GenSigCycleTime" SG_ 21 MRR_RL_CAN_NUMBER_OF_TRACKS_STAT 25;
BA_ "GenSigSendType" SG_ 21 MRR_RL_CAN_NUMBER_OF_TRACKS_MOV 0;
BA_ "GenSigCycleTime" SG_ 21 MRR_RL_CAN_NUMBER_OF_TRACKS_MOV 25;
BA_ "GenSigSendType" SG_ 21 MRR_RL_CAN_TD_SCAN_COUNTER 0;
BA_ "GenSigCycleTime" SG_ 21 MRR_RL_CAN_TD_SCAN_COUNTER 25;
BA_ "GenSigSendType" SG_ 21 MRR_RL_CAN_FOUND_TARGET 0;
BA_ "GenSigCycleTime" SG_ 21 MRR_RL_CAN_FOUND_TARGET 25;
BA_ "GenSigSendType" SG_ 21 MRR_RL_CAN_BLOCKAGE_TD 0;
BA_ "GenSigCycleTime" SG_ 21 MRR_RL_CAN_BLOCKAGE_TD 25;
BA_ "GenSigCmt" SG_ 18 MRR_RL_CAN_INST_MODE "Instrumentation mode";
BA_ "GenSigVtEn" SG_ 18 MRR_RL_CAN_INST_MODE "TRUE";
BA_ "GenSigSendType" SG_ 18 MRR_RL_CAN_INST_MODE 1;
BA_ "GenSigCmt" SG_ 19 MRR_RR_CAN_INST_MODE "Instrumentation mode";
BA_ "GenSigVtEn" SG_ 19 MRR_RR_CAN_INST_MODE "TRUE";
BA_ "GenSigSendType" SG_ 19 MRR_RR_CAN_INST_MODE 1;
BA_ "GenSigSendType" SG_ 1796 CAN_INTF_MINOR_VERSION 0;
BA_ "GenSigCycleTime" SG_ 1796 CAN_INTF_MINOR_VERSION 1000;
BA_ "GenSigSendType" SG_ 1796 CAN_INTF_MAJOR_VERSION 0;
BA_ "GenSigCycleTime" SG_ 1796 CAN_INTF_MAJOR_VERSION 1000;
BA_ "SignalDescription" SG_ 1796 CAN_PCAN_MINOR_CADM_HOST "PCAN protocol minor version used by the CADM";
BA_ "GenSigSendType" SG_ 1796 CAN_PCAN_MINOR_CADM_HOST 0;
BA_ "GenSigCycleTime" SG_ 1796 CAN_PCAN_MINOR_CADM_HOST 1000;
BA_ "SignalDescription" SG_ 1796 CAN_PCAN_MAJOR_CADM_HOST "PCAN protocol major version used by the CADM";
BA_ "GenSigSendType" SG_ 1796 CAN_PCAN_MAJOR_CADM_HOST 0;
BA_ "GenSigCycleTime" SG_ 1796 CAN_PCAN_MAJOR_CADM_HOST 1000;
BA_ "GenSigSendType" SG_ 1796 CADM_Field_Rev 0;
BA_ "GenSigCycleTime" SG_ 1796 CADM_Field_Rev 1000;
BA_ "GenSigSendType" SG_ 1796 CADM_SW_Promote_Rev 0;
BA_ "GenSigCycleTime" SG_ 1796 CADM_SW_Promote_Rev 1000;
BA_ "GenSigSendType" SG_ 1796 CADM_SW_Release_Rev 0;
BA_ "GenSigCycleTime" SG_ 1796 CADM_SW_Release_Rev 1000;
BA_ "GenSigSendType" SG_ 1796 CAN_PCAN_MINOR_VER 0;
BA_ "GenSigCycleTime" SG_ 1796 CAN_PCAN_MINOR_VER 1000;
BA_ "GenSigSendType" SG_ 1796 CAN_PCAN_MAJOR_VER 0;
BA_ "GenSigCycleTime" SG_ 1796 CAN_PCAN_MAJOR_VER 1000;
BA_ "GenSigSendType" SG_ 4 Radar_Trig_Control_MC 0;
BA_ "GenSigCycleTime" SG_ 4 Radar_Trig_Control_MC 50;
BA_ "GenSigSendType" SG_ 4 Radar_Trig_Control_CRC 0;
BA_ "GenSigCycleTime" SG_ 4 Radar_Trig_Control_CRC 50;
BA_ "GenSigSendType" SG_ 4 CADM_TimeSync_Timer_Count 0;
BA_ "GenSigCycleTime" SG_ 4 CADM_TimeSync_Timer_Count 50;
BA_ "GenSigSendType" SG_ 334 MRR_RL_System_Operation_Mode_Sta 1;
BA_ "SystemSignalLongSymbol" SG_ 334 MRR_RL_System_Operation_Mode_Sta "MRR_RL_System_Operation_Mode_Status";
BA_ "GenSigVtEn" SG_ 334 RadarSensorNotOperational_MRRRL "TRUE";
BA_ "GenSigCmt" SG_ 334 RadarSensorNotOperational_MRRRL "Set to TRUE when the radar system is not operational";
BA_ "GenSigVtEn" SG_ 334 RadarAlignmentOutOfRange_MRRRL "TRUE";
BA_ "GenSigCmt" SG_ 334 RadarAlignmentOutOfRange_MRRRL "Set to TRUE when the radar sensor cannot be aligned without mechanical adjustment of the sensor";
BA_ "GenSigVtEn" SG_ 334 RadarBlockageDetected_MRRRL "TRUE";
BA_ "GenSigCmt" SG_ 334 RadarBlockageDetected_MRRRL "Blockage error indication";
BA_ "GenSigVtEn" SG_ 334 RadarExternalConditionsNotOK_MRR "TRUE";
BA_ "GenSigCmt" SG_ 334 RadarExternalConditionsNotOK_MRR "Set to TRUE when the RL is not working properly because of too high temperature or insufficient power in the FR";
BA_ "SystemSignalLongSymbol" SG_ 334 RadarExternalConditionsNotOK_MRR "RadarExternalConditionsNotOK_MRRRL";
BA_ "GenSigVtEn" SG_ 334 RadarAlignmentIncomplete_MRRRL "TRUE";
BA_ "GenSigCmt" SG_ 334 RadarAlignmentIncomplete_MRRRL "Indication that the alignment routine has not been completed";
BA_ "GenSigVtEn" SG_ 334 RadarAlignmentNotStarted_MRRRL "TRUE";
BA_ "GenSigCmt" SG_ 334 RadarAlignmentNotStarted_MRRRL "Set to TRUE as long as the radar sensor alignment has not started";
BA_ "GenSigSendType" SG_ 270 MRR_RR_System_Operation_Mode_Sta 1;
BA_ "SystemSignalLongSymbol" SG_ 270 MRR_RR_System_Operation_Mode_Sta "MRR_RR_System_Operation_Mode_Status";
BA_ "GenSigVtEn" SG_ 270 RadarSensorNotOperational_MRRRR "TRUE";
BA_ "GenSigCmt" SG_ 270 RadarSensorNotOperational_MRRRR "Set to TRUE when the radar system is not operational";
BA_ "GenSigVtEn" SG_ 270 RadarAlignmentOutOfRange_MRRRR "TRUE";
BA_ "GenSigCmt" SG_ 270 RadarAlignmentOutOfRange_MRRRR "Set to TRUE when the radar sensor cannot be aligned without mechanical adjustment of the sensor";
BA_ "GenSigVtEn" SG_ 270 RadarBlockageDetected_MRRRR "TRUE";
BA_ "GenSigCmt" SG_ 270 RadarBlockageDetected_MRRRR "Blockage error indication";
BA_ "GenSigVtEn" SG_ 270 RadarExternalConditionsNotO_0000 "TRUE";
BA_ "GenSigCmt" SG_ 270 RadarExternalConditionsNotO_0000 "Set to TRUE when the RR is not working properly because of too high temperature or insufficient power in the FR";
BA_ "SystemSignalLongSymbol" SG_ 270 RadarExternalConditionsNotO_0000 "RadarExternalConditionsNotOK_MRRRR";
BA_ "GenSigVtEn" SG_ 270 RadarAlignmentIncomplete_MRRRR "TRUE";
BA_ "GenSigCmt" SG_ 270 RadarAlignmentIncomplete_MRRRR "Indication that the alignment routine has not been completed";
BA_ "GenSigVtEn" SG_ 270 RadarAlignmentNotStarted_MRRRR "TRUE";
BA_ "GenSigCmt" SG_ 270 RadarAlignmentNotStarted_MRRRR "Set to TRUE as long as the radar sensor alignment has not started";
BA_ "SignalDescription" SG_ 1280 MRR_RL_CAN_DET_MID_TARGET_007 "MID_Target_Discrimination";
BA_ "SignalDescription" SG_ 1280 MRR_RL_CAN_DET_MID_TARGET_006 "MID_Target_Discrimination";
BA_ "SignalDescription" SG_ 1280 MRR_RL_CAN_DET_MID_TARGET_005 "MID_Target_Discrimination";
BA_ "SignalDescription" SG_ 1280 MRR_RL_CAN_DET_MID_TARGET_004 "MID_Target_Discrimination";
BA_ "SignalDescription" SG_ 1280 MRR_RL_CAN_DET_MID_TARGET_003 "MID_Target_Discrimination";
BA_ "SignalDescription" SG_ 1280 MRR_RL_CAN_DET_MID_TARGET_002 "MID_Target_Discrimination";
BA_ "SignalDescription" SG_ 1280 MRR_RL_CAN_DET_MID_TARGET_001 "MID_Target_Discrimination";
BA_ "SignalDescription" SG_ 1280 MRR_RL_CAN_DET_Near_TARGET_007 "Near_Target_Discrimination";
BA_ "SignalDescription" SG_ 1280 MRR_RL_CAN_DET_Near_TARGET_006 "Near_Target_Discrimination";
BA_ "SignalDescription" SG_ 1280 MRR_RL_CAN_DET_Near_TARGET_005 "Near_Target_Discrimination";
BA_ "SignalDescription" SG_ 1280 MRR_RL_CAN_DET_Near_TARGET_004 "Near_Target_Discrimination";
BA_ "SignalDescription" SG_ 1280 MRR_RL_CAN_DET_Near_TARGET_003 "Near_Target_Discrimination";
BA_ "SignalDescription" SG_ 1280 MRR_RL_CAN_DET_Near_TARGET_002 "Near_Target_Discrimination";
BA_ "SignalDescription" SG_ 1280 MRR_RL_CAN_DET_Near_TARGET_001 "Near_Target_Discrimination";
BA_ "GenSigCmt" SG_ 1280 MRR_RL_CAN_DET_SUPER_RES_TA_0056 "Super resolution target ";
BA_ "SystemSignalLongSymbol" SG_ 1280 MRR_RL_CAN_DET_SUPER_RES_TA_0056 "MRR_RL_CAN_DET_SUPER_RES_TARGET_007";
BA_ "GenSigStartValue" SG_ 1280 MRR_RL_CAN_DET_ELEVATION_007 63.8646288209607;
BA_ "GenSigCmt" SG_ 1280 MRR_RL_CAN_DET_ELEVATION_007 "Detected object elevation position";
BA_ "GenSigCmt" SG_ 1280 MRR_RL_CAN_DET_HOST_VEH_CLU_0056 "Host vehicle clutter";
BA_ "SystemSignalLongSymbol" SG_ 1280 MRR_RL_CAN_DET_HOST_VEH_CLU_0056 "MRR_RL_CAN_DET_HOST_VEH_CLUTTER_007";
BA_ "GenSigCmt" SG_ 1280 MRR_RL_CAN_DET_CONFID_ELEVA_0056 "Elevation Angle Confidence";
BA_ "SystemSignalLongSymbol" SG_ 1280 MRR_RL_CAN_DET_CONFID_ELEVA_0056 "MRR_RL_CAN_DET_CONFID_ELEVATION_007";
BA_ "GenSigStartValue" SG_ 1280 MRR_RL_CAN_DET_AZIMUTH_007 8194.05320813772;
BA_ "GenSigCmt" SG_ 1280 MRR_RL_CAN_DET_AZIMUTH_007 "Detected object azimuth position";
BA_ "GenSigCmt" SG_ 1280 MRR_RL_CAN_DET_CONFID_AZIMU_0050 "Signal to noise level";
BA_ "GenSigVtEn" SG_ 1280 MRR_RL_CAN_DET_CONFID_AZIMU_0050 "TRUE";
BA_ "SystemSignalLongSymbol" SG_ 1280 MRR_RL_CAN_DET_CONFID_AZIMU_0050 "MRR_RL_CAN_DET_CONFID_AZIMUTH_007";
BA_ "GenSigCmt" SG_ 1280 MRR_RL_CAN_DET_RANGE_007 "Detected object range";
BA_ "GenSigCmt" SG_ 1280 MRR_RL_CAN_SCAN_INDEX_2LSB_007 "The two LSB of scan index";
BA_ "GenSigStartValue" SG_ 1280 MRR_RL_CAN_DET_RANGE_RATE_007 8192;
BA_ "GenSigCmt" SG_ 1280 MRR_RL_CAN_DET_RANGE_RATE_007 "Detected object range rate";
BA_ "GenSigCmt" SG_ 1280 MRR_RL_CAN_DET_VALID_LEVEL_007 "Detected object valid level";
BA_ "GenSigStartValue" SG_ 1280 MRR_RL_CAN_DET_AMPLITUDE_007 64;
BA_ "GenSigCmt" SG_ 1280 MRR_RL_CAN_DET_AMPLITUDE_007 "Detected object amplitude";
BA_ "GenSigCmt" SG_ 1280 MRR_RL_CAN_DET_SUPER_RES_TA_0057 "Super resolution target ";
BA_ "SystemSignalLongSymbol" SG_ 1280 MRR_RL_CAN_DET_SUPER_RES_TA_0057 "MRR_RL_CAN_DET_SUPER_RES_TARGET_006";
BA_ "GenSigStartValue" SG_ 1280 MRR_RL_CAN_DET_ELEVATION_006 63.8646288209607;
BA_ "GenSigCmt" SG_ 1280 MRR_RL_CAN_DET_ELEVATION_006 "Detected object elevation position";
BA_ "GenSigCmt" SG_ 1280 MRR_RL_CAN_DET_HOST_VEH_CLU_0057 "Host vehicle clutter";
BA_ "SystemSignalLongSymbol" SG_ 1280 MRR_RL_CAN_DET_HOST_VEH_CLU_0057 "MRR_RL_CAN_DET_HOST_VEH_CLUTTER_006";
BA_ "GenSigCmt" SG_ 1280 MRR_RL_CAN_DET_CONFID_ELEVA_0057 "Elevation Angle Confidence";
BA_ "SystemSignalLongSymbol" SG_ 1280 MRR_RL_CAN_DET_CONFID_ELEVA_0057 "MRR_RL_CAN_DET_CONFID_ELEVATION_006";
BA_ "GenSigStartValue" SG_ 1280 MRR_RL_CAN_DET_AZIMUTH_006 8194.05320813772;
BA_ "GenSigCmt" SG_ 1280 MRR_RL_CAN_DET_AZIMUTH_006 "Detected object azimuth position";
BA_ "GenSigCmt" SG_ 1280 MRR_RL_CAN_DET_CONFID_AZIMU_0051 "Signal to noise level";
BA_ "GenSigVtEn" SG_ 1280 MRR_RL_CAN_DET_CONFID_AZIMU_0051 "TRUE";
BA_ "SystemSignalLongSymbol" SG_ 1280 MRR_RL_CAN_DET_CONFID_AZIMU_0051 "MRR_RL_CAN_DET_CONFID_AZIMUTH_006";
BA_ "GenSigCmt" SG_ 1280 MRR_RL_CAN_DET_RANGE_006 "Detected object range";
BA_ "GenSigCmt" SG_ 1280 MRR_RL_CAN_SCAN_INDEX_2LSB_006 "The two LSB of scan index";
BA_ "GenSigStartValue" SG_ 1280 MRR_RL_CAN_DET_RANGE_RATE_006 8192;
BA_ "GenSigCmt" SG_ 1280 MRR_RL_CAN_DET_RANGE_RATE_006 "Detected object range rate";
BA_ "GenSigCmt" SG_ 1280 MRR_RL_CAN_DET_VALID_LEVEL_006 "Detected object valid level";
BA_ "GenSigStartValue" SG_ 1280 MRR_RL_CAN_DET_AMPLITUDE_006 64;
BA_ "GenSigCmt" SG_ 1280 MRR_RL_CAN_DET_AMPLITUDE_006 "Detected object amplitude";
BA_ "GenSigCmt" SG_ 1280 MRR_RL_CAN_DET_SUPER_RES_TA_0058 "Super resolution target ";
BA_ "SystemSignalLongSymbol" SG_ 1280 MRR_RL_CAN_DET_SUPER_RES_TA_0058 "MRR_RL_CAN_DET_SUPER_RES_TARGET_005";
BA_ "GenSigStartValue" SG_ 1280 MRR_RL_CAN_DET_ELEVATION_005 63.8646288209607;
BA_ "GenSigCmt" SG_ 1280 MRR_RL_CAN_DET_ELEVATION_005 "Detected object elevation position";
BA_ "GenSigCmt" SG_ 1280 MRR_RL_CAN_DET_HOST_VEH_CLU_0058 "Host vehicle clutter";
BA_ "SystemSignalLongSymbol" SG_ 1280 MRR_RL_CAN_DET_HOST_VEH_CLU_0058 "MRR_RL_CAN_DET_HOST_VEH_CLUTTER_005";
BA_ "GenSigCmt" SG_ 1280 MRR_RL_CAN_DET_CONFID_ELEVA_0058 "Elevation Angle Confidence";
BA_ "SystemSignalLongSymbol" SG_ 1280 MRR_RL_CAN_DET_CONFID_ELEVA_0058 "MRR_RL_CAN_DET_CONFID_ELEVATION_005";
BA_ "GenSigStartValue" SG_ 1280 MRR_RL_CAN_DET_AZIMUTH_005 8194.05320813772;
BA_ "GenSigCmt" SG_ 1280 MRR_RL_CAN_DET_AZIMUTH_005 "Detected object azimuth position";
BA_ "GenSigCmt" SG_ 1280 MRR_RL_CAN_DET_CONFID_AZIMU_0052 "Signal to noise level";
BA_ "GenSigVtEn" SG_ 1280 MRR_RL_CAN_DET_CONFID_AZIMU_0052 "TRUE";
BA_ "SystemSignalLongSymbol" SG_ 1280 MRR_RL_CAN_DET_CONFID_AZIMU_0052 "MRR_RL_CAN_DET_CONFID_AZIMUTH_005";
BA_ "GenSigCmt" SG_ 1280 MRR_RL_CAN_DET_RANGE_005 "Detected object range";
BA_ "GenSigCmt" SG_ 1280 MRR_RL_CAN_SCAN_INDEX_2LSB_005 "The two LSB of scan index";
BA_ "GenSigStartValue" SG_ 1280 MRR_RL_CAN_DET_RANGE_RATE_005 8192;
BA_ "GenSigCmt" SG_ 1280 MRR_RL_CAN_DET_RANGE_RATE_005 "Detected object range rate";
BA_ "GenSigCmt" SG_ 1280 MRR_RL_CAN_DET_VALID_LEVEL_005 "Detected object valid level";
BA_ "GenSigStartValue" SG_ 1280 MRR_RL_CAN_DET_AMPLITUDE_005 64;
BA_ "GenSigCmt" SG_ 1280 MRR_RL_CAN_DET_AMPLITUDE_005 "Detected object amplitude";
BA_ "GenSigCmt" SG_ 1280 MRR_RL_CAN_DET_SUPER_RES_TA_0059 "Super resolution target ";
BA_ "SystemSignalLongSymbol" SG_ 1280 MRR_RL_CAN_DET_SUPER_RES_TA_0059 "MRR_RL_CAN_DET_SUPER_RES_TARGET_004";
BA_ "GenSigStartValue" SG_ 1280 MRR_RL_CAN_DET_ELEVATION_004 63.8646288209607;
BA_ "GenSigCmt" SG_ 1280 MRR_RL_CAN_DET_ELEVATION_004 "Detected object elevation position";
BA_ "GenSigCmt" SG_ 1280 MRR_RL_CAN_DET_HOST_VEH_CLU_0059 "Host vehicle clutter";
BA_ "SystemSignalLongSymbol" SG_ 1280 MRR_RL_CAN_DET_HOST_VEH_CLU_0059 "MRR_RL_CAN_DET_HOST_VEH_CLUTTER_004";
BA_ "GenSigCmt" SG_ 1280 MRR_RL_CAN_DET_CONFID_ELEVA_0059 "Elevation Angle Confidence";
BA_ "SystemSignalLongSymbol" SG_ 1280 MRR_RL_CAN_DET_CONFID_ELEVA_0059 "MRR_RL_CAN_DET_CONFID_ELEVATION_004";
BA_ "GenSigStartValue" SG_ 1280 MRR_RL_CAN_DET_AZIMUTH_004 8194.05320813772;
BA_ "GenSigCmt" SG_ 1280 MRR_RL_CAN_DET_AZIMUTH_004 "Detected object azimuth position";
BA_ "GenSigCmt" SG_ 1280 MRR_RL_CAN_DET_CONFID_AZIMU_0053 "Signal to noise level";
BA_ "GenSigVtEn" SG_ 1280 MRR_RL_CAN_DET_CONFID_AZIMU_0053 "TRUE";
BA_ "SystemSignalLongSymbol" SG_ 1280 MRR_RL_CAN_DET_CONFID_AZIMU_0053 "MRR_RL_CAN_DET_CONFID_AZIMUTH_004";
BA_ "GenSigCmt" SG_ 1280 MRR_RL_CAN_DET_RANGE_004 "Detected object range";
BA_ "GenSigCmt" SG_ 1280 MRR_RL_CAN_SCAN_INDEX_2LSB_004 "The two LSB of scan index";
BA_ "GenSigStartValue" SG_ 1280 MRR_RL_CAN_DET_RANGE_RATE_004 8192;
BA_ "GenSigCmt" SG_ 1280 MRR_RL_CAN_DET_RANGE_RATE_004 "Detected object range rate";
BA_ "GenSigCmt" SG_ 1280 MRR_RL_CAN_DET_VALID_LEVEL_004 "Detected object valid level";
BA_ "GenSigStartValue" SG_ 1280 MRR_RL_CAN_DET_AMPLITUDE_004 64;
BA_ "GenSigCmt" SG_ 1280 MRR_RL_CAN_DET_AMPLITUDE_004 "Detected object amplitude";
BA_ "GenSigCmt" SG_ 1280 MRR_RL_CAN_DET_SUPER_RES_TA_0060 "Super resolution target ";
BA_ "SystemSignalLongSymbol" SG_ 1280 MRR_RL_CAN_DET_SUPER_RES_TA_0060 "MRR_RL_CAN_DET_SUPER_RES_TARGET_003";
BA_ "GenSigStartValue" SG_ 1280 MRR_RL_CAN_DET_ELEVATION_003 63.8646288209607;
BA_ "GenSigCmt" SG_ 1280 MRR_RL_CAN_DET_ELEVATION_003 "Detected object elevation position";
BA_ "GenSigCmt" SG_ 1280 MRR_RL_CAN_DET_HOST_VEH_CLU_0060 "Host vehicle clutter";
BA_ "SystemSignalLongSymbol" SG_ 1280 MRR_RL_CAN_DET_HOST_VEH_CLU_0060 "MRR_RL_CAN_DET_HOST_VEH_CLUTTER_003";
BA_ "GenSigCmt" SG_ 1280 MRR_RL_CAN_DET_CONFID_ELEVA_0060 "Elevation Angle Confidence";
BA_ "SystemSignalLongSymbol" SG_ 1280 MRR_RL_CAN_DET_CONFID_ELEVA_0060 "MRR_RL_CAN_DET_CONFID_ELEVATION_003";
BA_ "GenSigStartValue" SG_ 1280 MRR_RL_CAN_DET_AZIMUTH_003 8194.05320813772;
BA_ "GenSigCmt" SG_ 1280 MRR_RL_CAN_DET_AZIMUTH_003 "Detected object azimuth position";
BA_ "GenSigCmt" SG_ 1280 MRR_RL_CAN_DET_CONFID_AZIMU_0054 "Signal to noise level";
BA_ "GenSigVtEn" SG_ 1280 MRR_RL_CAN_DET_CONFID_AZIMU_0054 "TRUE";
BA_ "SystemSignalLongSymbol" SG_ 1280 MRR_RL_CAN_DET_CONFID_AZIMU_0054 "MRR_RL_CAN_DET_CONFID_AZIMUTH_003";
BA_ "GenSigCmt" SG_ 1280 MRR_RL_CAN_DET_RANGE_003 "Detected object range";
BA_ "GenSigCmt" SG_ 1280 MRR_RL_CAN_SCAN_INDEX_2LSB_003 "The two LSB of scan index";
BA_ "GenSigStartValue" SG_ 1280 MRR_RL_CAN_DET_RANGE_RATE_003 8192;
BA_ "GenSigCmt" SG_ 1280 MRR_RL_CAN_DET_RANGE_RATE_003 "Detected object range rate";
BA_ "GenSigCmt" SG_ 1280 MRR_RL_CAN_DET_VALID_LEVEL_003 "Detected object valid level";
BA_ "GenSigStartValue" SG_ 1280 MRR_RL_CAN_DET_AMPLITUDE_003 64;
BA_ "GenSigCmt" SG_ 1280 MRR_RL_CAN_DET_AMPLITUDE_003 "Detected object amplitude";
BA_ "GenSigCmt" SG_ 1280 MRR_RL_CAN_DET_SUPER_RES_TA_0061 "Super resolution target ";
BA_ "SystemSignalLongSymbol" SG_ 1280 MRR_RL_CAN_DET_SUPER_RES_TA_0061 "MRR_RL_CAN_DET_SUPER_RES_TARGET_002";
BA_ "GenSigStartValue" SG_ 1280 MRR_RL_CAN_DET_ELEVATION_002 63.8646288209607;
BA_ "GenSigCmt" SG_ 1280 MRR_RL_CAN_DET_ELEVATION_002 "Detected object elevation position";
BA_ "GenSigCmt" SG_ 1280 MRR_RL_CAN_DET_HOST_VEH_CLU_0061 "Host vehicle clutter";
BA_ "SystemSignalLongSymbol" SG_ 1280 MRR_RL_CAN_DET_HOST_VEH_CLU_0061 "MRR_RL_CAN_DET_HOST_VEH_CLUTTER_002";
BA_ "GenSigCmt" SG_ 1280 MRR_RL_CAN_DET_CONFID_ELEVA_0061 "Elevation Angle Confidence";
BA_ "SystemSignalLongSymbol" SG_ 1280 MRR_RL_CAN_DET_CONFID_ELEVA_0061 "MRR_RL_CAN_DET_CONFID_ELEVATION_002";
BA_ "GenSigStartValue" SG_ 1280 MRR_RL_CAN_DET_AZIMUTH_002 8194.05320813772;
BA_ "GenSigCmt" SG_ 1280 MRR_RL_CAN_DET_AZIMUTH_002 "Detected object azimuth position";
BA_ "GenSigCmt" SG_ 1280 MRR_RL_CAN_DET_CONFID_AZIMU_0055 "Signal to noise level";
BA_ "GenSigVtEn" SG_ 1280 MRR_RL_CAN_DET_CONFID_AZIMU_0055 "TRUE";
BA_ "SystemSignalLongSymbol" SG_ 1280 MRR_RL_CAN_DET_CONFID_AZIMU_0055 "MRR_RL_CAN_DET_CONFID_AZIMUTH_002";
BA_ "GenSigCmt" SG_ 1280 MRR_RL_CAN_DET_RANGE_002 "Detected object range";
BA_ "GenSigCmt" SG_ 1280 MRR_RL_CAN_SCAN_INDEX_2LSB_002 "The two LSB of scan index";
BA_ "GenSigStartValue" SG_ 1280 MRR_RL_CAN_DET_RANGE_RATE_002 8192;
BA_ "GenSigCmt" SG_ 1280 MRR_RL_CAN_DET_RANGE_RATE_002 "Detected object range rate";
BA_ "GenSigCmt" SG_ 1280 MRR_RL_CAN_DET_VALID_LEVEL_002 "Detected object valid level";
BA_ "GenSigStartValue" SG_ 1280 MRR_RL_CAN_DET_AMPLITUDE_002 64;
BA_ "GenSigCmt" SG_ 1280 MRR_RL_CAN_DET_AMPLITUDE_002 "Detected object amplitude";
BA_ "GenSigStartValue" SG_ 1280 MRR_RL_CAN_DET_ELEVATION_001 63.8646288209607;
BA_ "GenSigCmt" SG_ 1280 MRR_RL_CAN_DET_ELEVATION_001 "Detected object elevation position";
BA_ "GenSigCmt" SG_ 1280 MRR_RL_CAN_DET_SUPER_RES_TA_0062 "Super resolution target ";
BA_ "SystemSignalLongSymbol" SG_ 1280 MRR_RL_CAN_DET_SUPER_RES_TA_0062 "MRR_RL_CAN_DET_SUPER_RES_TARGET_001";
BA_ "GenSigStartValue" SG_ 1280 MRR_RL_CAN_DET_AZIMUTH_001 8194.05320813772;
BA_ "GenSigCmt" SG_ 1280 MRR_RL_CAN_DET_AZIMUTH_001 "Detected object azimuth position";
BA_ "GenSigCmt" SG_ 1280 MRR_RL_CAN_DET_CONFID_ELEVA_0062 "Elevation Angle Confidence";
BA_ "SystemSignalLongSymbol" SG_ 1280 MRR_RL_CAN_DET_CONFID_ELEVA_0062 "MRR_RL_CAN_DET_CONFID_ELEVATION_001";
BA_ "GenSigCmt" SG_ 1280 MRR_RL_CAN_DET_HOST_VEH_CLU_0062 "Host vehicle clutter";
BA_ "SystemSignalLongSymbol" SG_ 1280 MRR_RL_CAN_DET_HOST_VEH_CLU_0062 "MRR_RL_CAN_DET_HOST_VEH_CLUTTER_001";
BA_ "GenSigCmt" SG_ 1280 MRR_RL_CAN_DET_RANGE_001 "Detected object range";
BA_ "GenSigCmt" SG_ 1280 MRR_RL_CAN_DET_CONFID_AZIMU_0056 "Signal to noise level";
BA_ "GenSigVtEn" SG_ 1280 MRR_RL_CAN_DET_CONFID_AZIMU_0056 "TRUE";
BA_ "SystemSignalLongSymbol" SG_ 1280 MRR_RL_CAN_DET_CONFID_AZIMU_0056 "MRR_RL_CAN_DET_CONFID_AZIMUTH_001";
BA_ "GenSigStartValue" SG_ 1280 MRR_RL_CAN_DET_RANGE_RATE_001 8192;
BA_ "GenSigCmt" SG_ 1280 MRR_RL_CAN_DET_RANGE_RATE_001 "Detected object range rate";
BA_ "GenSigCmt" SG_ 1280 MRR_RL_CAN_SCAN_INDEX_2LSB_001 "The two LSB of scan index";
BA_ "GenSigStartValue" SG_ 1280 MRR_RL_CAN_DET_AMPLITUDE_001 64;
BA_ "GenSigCmt" SG_ 1280 MRR_RL_CAN_DET_AMPLITUDE_001 "Detected object amplitude";
BA_ "GenSigCmt" SG_ 1280 MRR_RL_CAN_DET_VALID_LEVEL_001 "Detected object valid level";
BA_ "GenSigSendType" SG_ 1988 MRR_RL_Req_Phys 1;
BA_ "GenSigSendType" SG_ 1990 MRR_RR_Req_Phys 1;
BA_ "GenSigSendType" SG_ 1996 MRR_RL_Resp_Phys 1;
BA_ "GenSigSendType" SG_ 1998 MRR_RR_Resp_Phys 1;
BA_ "SignalDescription" SG_ 2015 Diag_Req_Func "Functional request";
BA_ "GenSigSendType" SG_ 2015 Diag_Req_Func 1;
BA_ "GenSigSendType" SG_ 1268 MRR_RR_XCP_RESP_DAQ_Byte63 1;
BA_ "GenSigSendType" SG_ 1012 MRR_RL_XCP_RESP_DAQ_Byte63 1;
BA_ "GenSigSendType" SG_ 1265 MRR_RR_XCP_RESP_CTO_Byte63 1;
BA_ "GenSigSendType" SG_ 1009 MRR_RL_XCP_RESP_CTO_Byte63 1;
BA_ "GenSigSendType" SG_ 1264 MRR_RR_XCP_REQ_CTO_Byte63 1;
BA_ "GenSigSendType" SG_ 1008 MRR_RL_XCP_REQ_CTO_Byte63 1;
VAL_ 1283 MRR_RL_CAN_DET_CONFID_AZIMU_0031 3 "Low" 2 "MidLow" 1 "MidHigh" 0 "High" ;
VAL_ 1283 MRR_RL_CAN_DET_CONFID_AZIMU_0032 3 "Low" 2 "MidLow" 1 "MidHigh" 0 "High" ;
VAL_ 1283 MRR_RL_CAN_DET_CONFID_AZIMU_0033 3 "Low" 2 "MidLow" 1 "MidHigh" 0 "High" ;
VAL_ 1283 MRR_RL_CAN_DET_CONFID_AZIMU_0034 3 "Low" 2 "MidLow" 1 "MidHigh" 0 "High" ;
VAL_ 1283 MRR_RL_CAN_DET_CONFID_AZIMU_0035 3 "Low" 2 "MidLow" 1 "MidHigh" 0 "High" ;
VAL_ 1283 MRR_RL_CAN_DET_CONFID_AZIMU_0036 3 "Low" 2 "MidLow" 1 "MidHigh" 0 "High" ;
VAL_ 1283 MRR_RL_CAN_DET_CONFID_AZIMU_0037 3 "Low" 2 "MidLow" 1 "MidHigh" 0 "High" ;
VAL_ 1282 MRR_RL_CAN_DET_CONFID_AZIMU_0038 3 "Low" 2 "MidLow" 1 "MidHigh" 0 "High" ;
VAL_ 1282 MRR_RL_CAN_DET_CONFID_AZIMU_0039 3 "Low" 2 "MidLow" 1 "MidHigh" 0 "High" ;
VAL_ 1282 MRR_RL_CAN_DET_CONFID_AZIMUTH_01 3 "Low" 2 "MidLow" 1 "MidHigh" 0 "High" ;
VAL_ 1282 MRR_RL_CAN_DET_CONFID_AZIMU_0040 3 "Low" 2 "MidLow" 1 "MidHigh" 0 "High" ;
VAL_ 1282 MRR_RL_CAN_DET_CONFID_AZIMU_0041 3 "Low" 2 "MidLow" 1 "MidHigh" 0 "High" ;
VAL_ 1282 MRR_RL_CAN_DET_CONFID_AZIMU_0042 3 "Low" 2 "MidLow" 1 "MidHigh" 0 "High" ;
VAL_ 1282 MRR_RL_CAN_DET_CONFID_AZIMU_0043 3 "Low" 2 "MidLow" 1 "MidHigh" 0 "High" ;
VAL_ 1281 MRR_RL_CAN_DET_CONFID_AZIMU_0044 3 "Low" 2 "MidLow" 1 "MidHigh" 0 "High" ;
VAL_ 1281 MRR_RL_CAN_DET_CONFID_AZIMU_0045 3 "Low" 2 "MidLow" 1 "MidHigh" 0 "High" ;
VAL_ 1281 MRR_RL_CAN_DET_CONFID_AZIMU_0046 3 "Low" 2 "MidLow" 1 "MidHigh" 0 "High" ;
VAL_ 1281 MRR_RL_CAN_DET_CONFID_AZIMU_0047 3 "Low" 2 "MidLow" 1 "MidHigh" 0 "High" ;
VAL_ 1281 MRR_RL_CAN_DET_CONFID_AZIMU_0048 3 "Low" 2 "MidLow" 1 "MidHigh" 0 "High" ;
VAL_ 1281 MRR_RL_CAN_DET_CONFID_AZIMUTH_00 3 "Low" 2 "MidLow" 1 "MidHigh" 0 "High" ;
VAL_ 1281 MRR_RL_CAN_DET_CONFID_AZIMU_0049 3 "Low" 2 "MidLow" 1 "MidHigh" 0 "High" ;
VAL_ 1346 SensorCfg_MRRRL_Orientation 255 "-1 Connector Up (Upside Down)" 1 "+1 Connector Down (Normal Orientation)" ;
VAL_ 1346 SensorCfg_MRRRR_Orientation 255 "-1 Connector Up (Upside Down)" 1 "+1 Connector Down (Normal Orientation)" ;
VAL_ 1346 SensorCfg_MRRFL_Orientation 255 "-1 Connector Up (Upside Down)" 1 "+1 Connector Down (Normal Orientation)" ;
VAL_ 1346 SensorCfg_MRRFR_Orientation 255 "-1 Connector Up (Upside Down)" 1 "+1 Connector Down (Normal Orientation)" ;
VAL_ 20 RadarWaveform_MRRRR 4 "Unused" 3 "AutoHitch" 2 "Standard_Rear" 1 "Standard_Front" 0 "Unknown" ;
VAL_ 20 MRR_RR_CAN_FOUND_TARGET 1 "Target found" 0 "Target not found" ;
VAL_ 20 MRR_RR_CAN_BLOCKAGE_TD 1 "TD blockage" 0 "No blockage" ;
VAL_ 21 RadarWaveform_MRRRL 4 "Unused" 3 "AutoHitch" 2 "Standard_Rear" 1 "Standard_Front" 0 "Unknown" ;
VAL_ 21 MRR_RL_CAN_FOUND_TARGET 1 "Target found" 0 "Target not found" ;
VAL_ 21 MRR_RL_CAN_BLOCKAGE_TD 1 "TD blockage" 0 "No blockage" ;
VAL_ 18 MRR_RL_CAN_INST_MODE 43605 "Instrumentation mode is set" ;
VAL_ 19 MRR_RR_CAN_INST_MODE 43605 "Instrumentation mode is set" ;
VAL_ 334 MRR_RL_System_Operation_Mode_Sta 2 "RADIATE_ON" 1 "RADIATE_OFF" 0 "INIT" ;
VAL_ 334 RadarSensorNotOperational_MRRRL 1 "TRUE" 0 "FALSE" ;
VAL_ 334 RadarAlignmentOutOfRange_MRRRL 1 "Radar out of range" 0 "Radar within range" ;
VAL_ 334 RadarBlockageDetected_MRRRL 1 "Radar Blockage" 0 "No Radar Blockage" ;
VAL_ 334 RadarExternalConditionsNotOK_MRR 1 "Too high temp or insufficient pw" 0 "External conditions OK" ;
VAL_ 334 RadarAlignmentIncomplete_MRRRL 1 "Alignment Incomplete" 0 "Alignment Completed" ;
VAL_ 334 RadarAlignmentNotStarted_MRRRL 1 "Radar align not started" 0 "Radar align started" ;
VAL_ 270 MRR_RR_System_Operation_Mode_Sta 2 "RADIATE_ON" 1 "RADIATE_OFF" 0 "INIT" ;
VAL_ 270 RadarSensorNotOperational_MRRRR 1 "TRUE" 0 "FALSE" ;
VAL_ 270 RadarAlignmentOutOfRange_MRRRR 1 "Radar out of range" 0 "Radar within range" ;
VAL_ 270 RadarBlockageDetected_MRRRR 1 "Radar Blockage" 0 "No Radar Blockage" ;
VAL_ 270 RadarExternalConditionsNotO_0000 1 "Too high temp or insufficient pw" 0 "External conditions OK" ;
VAL_ 270 RadarAlignmentIncomplete_MRRRR 1 "Alignment Incomplete" 0 "Alignment Completed" ;
VAL_ 270 RadarAlignmentNotStarted_MRRRR 1 "Radar align not started" 0 "Radar align started" ;
VAL_ 1280 MRR_RL_CAN_DET_CONFID_AZIMU_0050 3 "Low" 2 "MidLow" 1 "MidHigh" 0 "High" ;
VAL_ 1280 MRR_RL_CAN_DET_CONFID_AZIMU_0051 3 "Low" 2 "MidLow" 1 "MidHigh" 0 "High" ;
VAL_ 1280 MRR_RL_CAN_DET_CONFID_AZIMU_0052 3 "Low" 2 "MidLow" 1 "MidHigh" 0 "High" ;
VAL_ 1280 MRR_RL_CAN_DET_CONFID_AZIMU_0053 3 "Low" 2 "MidLow" 1 "MidHigh" 0 "High" ;
VAL_ 1280 MRR_RL_CAN_DET_CONFID_AZIMU_0054 3 "Low" 2 "MidLow" 1 "MidHigh" 0 "High" ;
VAL_ 1280 MRR_RL_CAN_DET_CONFID_AZIMU_0055 3 "Low" 2 "MidLow" 1 "MidHigh" 0 "High" ;
VAL_ 1280 MRR_RL_CAN_DET_CONFID_AZIMU_0056 3 "Low" 2 "MidLow" 1 "MidHigh" 0 "High" ;
SIG_GROUP_ 1283 MRR_RL_Detection_022_028 1 : MRR_RL_CAN_DET_Near_TARGET_028 MRR_RL_CAN_DET_Near_TARGET_027 MRR_RL_CAN_DET_Near_TARGET_026 MRR_RL_CAN_DET_Near_TARGET_025 MRR_RL_CAN_DET_Near_TARGET_024 MRR_RL_CAN_DET_Near_TARGET_023 MRR_RL_CAN_DET_Near_TARGET_022 MRR_RL_CAN_DET_MID_TARGET_022 MRR_RL_CAN_DET_MID_TARGET_023 MRR_RL_CAN_DET_MID_TARGET_024 MRR_RL_CAN_DET_MID_TARGET_025 MRR_RL_CAN_DET_MID_TARGET_026 MRR_RL_CAN_DET_MID_TARGET_027 MRR_RL_CAN_DET_MID_TARGET_028 MRR_RL_DET_CRC_004 MRR_RL_DET_MC_004 MRR_RL_CAN_DET_VALID_LEVEL_028 MRR_RL_CAN_DET_VALID_LEVEL_022 MRR_RL_CAN_DET_AMPLITUDE_022 MRR_RL_CAN_DET_ELEVATION_028 MRR_RL_CAN_DET_SUPER_RES_TA_0035 MRR_RL_CAN_DET_RANGE_025 MRR_RL_CAN_DET_HOST_VEH_CLU_0035 MRR_RL_CAN_DET_CONFID_ELEVA_0035 MRR_RL_CAN_DET_CONFID_AZIMU_0031 MRR_RL_CAN_DET_RANGE_RATE_022 MRR_RL_CAN_SCAN_INDEX_2LSB_025 MRR_RL_CAN_DET_AMPLITUDE_025 MRR_RL_CAN_SCAN_INDEX_2LSB_022 MRR_RL_CAN_DET_VALID_LEVEL_024 MRR_RL_CAN_DET_SUPER_RES_TA_0041 MRR_RL_CAN_DET_SUPER_RES_TA_0040 MRR_RL_CAN_DET_CONFID_AZIMU_0035 MRR_RL_CAN_DET_ELEVATION_023 MRR_RL_CAN_DET_HOST_VEH_CLU_0041 MRR_RL_CAN_DET_RANGE_RATE_023 MRR_RL_CAN_DET_AZIMUTH_022 MRR_RL_CAN_DET_RANGE_022 MRR_RL_CAN_DET_ELEVATION_022 MRR_RL_CAN_DET_CONFID_AZIMU_0037 MRR_RL_CAN_DET_AMPLITUDE_023 MRR_RL_CAN_DET_HOST_VEH_CLU_0040 MRR_RL_CAN_SCAN_INDEX_2LSB_023 MRR_RL_CAN_DET_AZIMUTH_023 MRR_RL_CAN_DET_RANGE_023 MRR_RL_CAN_DET_AZIMUTH_028 MRR_RL_CAN_DET_AMPLITUDE_028 MRR_RL_CAN_DET_SUPER_RES_TA_0038 MRR_RL_CAN_DET_RANGE_028 MRR_RL_CAN_DET_RANGE_RATE_024 MRR_RL_CAN_SCAN_INDEX_2LSB_024 MRR_RL_CAN_DET_HOST_VEH_CLU_0039 MRR_RL_CAN_DET_ELEVATION_026 MRR_RL_CAN_DET_ELEVATION_025 MRR_RL_CAN_DET_RANGE_024 MRR_RL_CAN_DET_ELEVATION_024 MRR_RL_CAN_DET_SUPER_RES_TA_0039 MRR_RL_CAN_DET_VALID_LEVEL_025 MRR_RL_CAN_DET_HOST_VEH_CLU_0038 MRR_RL_CAN_DET_AZIMUTH_025 MRR_RL_CAN_DET_CONFID_ELEVA_0038 MRR_RL_CAN_DET_AZIMUTH_027 MRR_RL_CAN_SCAN_INDEX_2LSB_028 MRR_RL_CAN_DET_SUPER_RES_TA_0036 MRR_RL_CAN_DET_HOST_VEH_CLU_0036 MRR_RL_CAN_DET_ELEVATION_027 MRR_RL_CAN_DET_VALID_LEVEL_023 MRR_RL_CAN_DET_CONFID_ELEVA_0040 MRR_RL_CAN_DET_VALID_LEVEL_027 MRR_RL_CAN_DET_CONFID_ELEVA_0036 MRR_RL_CAN_SCAN_INDEX_2LSB_027 MRR_RL_CAN_DET_RANGE_RATE_027 MRR_RL_CAN_DET_CONFID_ELEVA_0041 MRR_RL_CAN_DET_RANGE_027 MRR_RL_CAN_DET_RANGE_RATE_026 MRR_RL_CAN_DET_RANGE_026 MRR_RL_CAN_DET_SUPER_RES_TA_0037 MRR_RL_CAN_DET_CONFID_AZIMU_0032 MRR_RL_CAN_DET_AMPLITUDE_024 MRR_RL_CAN_DET_CONFID_AZIMU_0036 MRR_RL_CAN_DET_AMPLITUDE_027 MRR_RL_CAN_DET_AZIMUTH_024 MRR_RL_CAN_DET_CONFID_ELEVA_0037 MRR_RL_CAN_DET_CONFID_ELEVA_0039 MRR_RL_CAN_DET_AMPLITUDE_026 MRR_RL_CAN_DET_RANGE_RATE_025 MRR_RL_CAN_DET_VALID_LEVEL_026 MRR_RL_CAN_DET_HOST_VEH_CLU_0037 MRR_RL_CAN_SCAN_INDEX_2LSB_026 MRR_RL_CAN_DET_CONFID_AZIMU_0033 MRR_RL_CAN_DET_AZIMUTH_026 MRR_RL_CAN_DET_CONFID_AZIMU_0034 MRR_RL_CAN_DET_RANGE_RATE_028;
SIG_GROUP_ 1282 MRR_RL_Detection_015_021 1 : MRR_RL_CAN_DET_Near_TARGET_021 MRR_RL_CAN_DET_Near_TARGET_020 MRR_RL_CAN_DET_Near_TARGET_019 MRR_RL_CAN_DET_Near_TARGET_018 MRR_RL_CAN_DET_Near_TARGET_017 MRR_RL_CAN_DET_Near_TARGET_016 MRR_RL_CAN_DET_Near_TARGET_015 MRR_RL_CAN_DET_MID_TARGET_015 MRR_RL_CAN_DET_MID_TARGET_016 MRR_RL_CAN_DET_MID_TARGET_017 MRR_RL_CAN_DET_MID_TARGET_018 MRR_RL_CAN_DET_MID_TARGET_019 MRR_RL_CAN_DET_MID_TARGET_020 MRR_RL_CAN_DET_MID_TARGET_021 MRR_RL_DET_CRC_003 MRR_RL_DET_MC_003 MRR_RL_CAN_DET_SUPER_RES_TA_0042 MRR_RL_CAN_DET_ELEVATION_021 MRR_RL_CAN_DET_HOST_VEH_CLU_0042 MRR_RL_CAN_DET_CONFID_ELEVA_0042 MRR_RL_CAN_DET_RANGE_RATE_015 MRR_RL_CAN_DET_AMPLITUDE_015 MRR_RL_CAN_DET_VALID_LEVEL_015 MRR_RL_CAN_SCAN_INDEX_2LSB_015 MRR_RL_CAN_DET_AZIMUTH_021 MRR_RL_CAN_SCAN_INDEX_2LSB_021 MRR_RL_CAN_DET_VALID_LEVEL_021 MRR_RL_CAN_DET_RANGE_021 MRR_RL_CAN_DET_RANGE_RATE_021 MRR_RL_CAN_DET_AMPLITUDE_021 MRR_RL_CAN_DET_SUPER_RES_TA_0043 MRR_RL_CAN_DET_ELEVATION_020 MRR_RL_CAN_DET_CONFID_ELEVA_0043 MRR_RL_CAN_DET_RANGE_018 MRR_RL_CAN_DET_ELEVATION_018 MRR_RL_CAN_DET_RANGE_017 MRR_RL_CAN_DET_AZIMUTH_015 MRR_RL_CAN_DET_RANGE_015 MRR_RL_CAN_DET_CONFID_AZIMU_0043 MRR_RL_CAN_DET_CONFID_ELEVA_0048 MRR_RL_CAN_DET_RANGE_016 MRR_RL_CAN_DET_HOST_VEH_CLU_0048 MRR_RL_CAN_DET_VALID_LEVEL_016 MRR_RL_CAN_SCAN_INDEX_2LSB_016 MRR_RL_CAN_DET_SUPER_RES_TA_0048 MRR_RL_CAN_DET_AMPLITUDE_016 MRR_RL_CAN_DET_ELEVATION_016 MRR_RL_CAN_DET_HOST_VEH_CLU_0045 MRR_RL_CAN_DET_ELEVATION_017 MRR_RL_CAN_DET_ELEVATION_019 MRR_RL_CAN_DET_AMPLITUDE_017 MRR_RL_CAN_DET_AZIMUTH_016 MRR_RL_CAN_SCAN_INDEX_2LSB_018 MRR_RL_CAN_DET_ELEVATION_015 MRR_RL_CAN_DET_AZIMUTH_018 MRR_RL_CAN_DET_VALID_LEVEL_018 MRR_RL_CAN_DET_RANGE_RATE_016 MRR_RL_CAN_DET_HOST_VEH_CLU_0043 MRR_RL_CAN_DET_CONFID_AZIMU_0042 MRR_RL_CAN_DET_RANGE_020 MRR_RL_CAN_DET_CONFID_ELEVA_0047 MRR_RL_CAN_DET_SUPER_RES_TA_0045 MRR_RL_CAN_DET_AZIMUTH_020 MRR_RL_CAN_DET_SUPER_RES_TA_0047 MRR_RL_CAN_SCAN_INDEX_2LSB_020 MRR_RL_CAN_DET_HOST_VEH_CLU_0047 MRR_RL_CAN_DET_RANGE_RATE_017 MRR_RL_CAN_DET_AMPLITUDE_019 MRR_RL_CAN_DET_VALID_LEVEL_017 MRR_RL_CAN_DET_RANGE_RATE_019 MRR_RL_CAN_SCAN_INDEX_2LSB_017 MRR_RL_CAN_DET_RANGE_019 MRR_RL_CAN_DET_AZIMUTH_017 MRR_RL_CAN_DET_CONFID_AZIMU_0039 MRR_RL_CAN_DET_RANGE_RATE_020 MRR_RL_CAN_DET_CONFID_ELEVA_0046 MRR_RL_CAN_DET_VALID_LEVEL_019 MRR_RL_CAN_DET_CONFID_AZIMU_0041 MRR_RL_CAN_SCAN_INDEX_2LSB_019 MRR_RL_CAN_DET_AMPLITUDE_018 MRR_RL_CAN_DET_CONFID_AZIMUTH_01 MRR_RL_CAN_DET_HOST_VEH_CLU_0046 MRR_RL_CAN_DET_SUPER_RES_TA_0046 MRR_RL_CAN_DET_AMPLITUDE_020 MRR_RL_CAN_DET_RANGE_RATE_018 MRR_RL_CAN_DET_AZIMUTH_019 MRR_RL_CAN_DET_CONFID_AZIMU_0040 MRR_RL_CAN_DET_CONFID_ELEVA_0044 MRR_RL_CAN_DET_HOST_VEH_CLU_0044 MRR_RL_CAN_DET_CONFID_ELEVA_0045 MRR_RL_CAN_DET_SUPER_RES_TA_0044 MRR_RL_CAN_DET_VALID_LEVEL_020 MRR_RL_CAN_DET_CONFID_AZIMU_0038;
SIG_GROUP_ 1281 MRR_RL_Detection_008_014 1 : MRR_RL_CAN_DET_Near_TARGET_014 MRR_RL_CAN_DET_Near_TARGET_013 MRR_RL_CAN_DET_Near_TARGET_012 MRR_RL_CAN_DET_Near_TARGET_011 MRR_RL_CAN_DET_Near_TARGET_010 MRR_RL_CAN_DET_Near_TARGET_009 MRR_RL_CAN_DET_Near_TARGET_008 MRR_RL_CAN_DET_MID_TARGET_008 MRR_RL_CAN_DET_MID_TARGET_009 MRR_RL_CAN_DET_MID_TARGET_010 MRR_RL_CAN_DET_MID_TARGET_011 MRR_RL_CAN_DET_MID_TARGET_012 MRR_RL_CAN_DET_MID_TARGET_013 MRR_RL_CAN_DET_MID_TARGET_014 MRR_RL_DET_MC_002 MRR_RL_CAN_DET_ELEVATION_014 MRR_RL_CAN_DET_HOST_VEH_CLU_0049 MRR_RL_CAN_DET_RANGE_RATE_008 MRR_RL_CAN_DET_AMPLITUDE_008 MRR_RL_CAN_DET_RANGE_014 MRR_RL_CAN_DET_AZIMUTH_014 MRR_RL_CAN_DET_VALID_LEVEL_008 MRR_RL_CAN_DET_AZIMUTH_009 MRR_RL_CAN_SCAN_INDEX_2LSB_008 MRR_RL_CAN_DET_AZIMUTH_008 MRR_RL_CAN_DET_CONFID_AZIMU_0049 MRR_RL_CAN_DET_CONFID_ELEVA_0055 MRR_RL_CAN_DET_RANGE_008 MRR_RL_CAN_DET_RANGE_009 MRR_RL_CAN_DET_SUPER_RES_TA_0055 MRR_RL_CAN_DET_AZIMUTH_013 MRR_RL_CAN_DET_RANGE_RATE_014 MRR_RL_CAN_DET_RANGE_013 MRR_RL_CAN_DET_VALID_LEVEL_013 MRR_RL_CAN_DET_RANGE_011 MRR_RL_CAN_SCAN_INDEX_2LSB_009 MRR_RL_CAN_DET_VALID_LEVEL_009 MRR_RL_CAN_DET_SUPER_RES_TA_0054 MRR_RL_CAN_DET_SUPER_RES_TA_0051 MRR_RL_CAN_DET_HOST_VEH_CLU_0051 MRR_RL_CAN_DET_CONFID_ELEVA_0051 MRR_RL_CAN_DET_CONFID_ELEVA_0054 MRR_RL_CAN_DET_CONFID_AZIMU_0046 MRR_RL_CAN_DET_RANGE_RATE_013 MRR_RL_CAN_DET_ELEVATION_012 MRR_RL_CAN_DET_VALID_LEVEL_010 MRR_RL_CAN_DET_ELEVATION_010 MRR_RL_CAN_DET_AMPLITUDE_010 MRR_RL_CAN_DET_HOST_VEH_CLU_0055 MRR_RL_CAN_DET_RANGE_010 MRR_RL_CAN_DET_AMPLITUDE_012 MRR_RL_CAN_DET_ELEVATION_011 MRR_RL_CAN_DET_AMPLITUDE_013 MRR_RL_CAN_DET_RANGE_RATE_009 MRR_RL_CAN_DET_CONFID_AZIMUTH_00 MRR_RL_CAN_DET_HOST_VEH_CLU_0054 MRR_RL_CAN_DET_AZIMUTH_011 MRR_RL_CAN_DET_AMPLITUDE_011 MRR_RL_CAN_DET_ELEVATION_009 MRR_RL_CAN_DET_CONFID_ELEVA_0053 MRR_RL_CAN_DET_HOST_VEH_CLU_0053 MRR_RL_CAN_DET_HOST_VEH_CLU_0052 MRR_RL_CAN_DET_VALID_LEVEL_012 MRR_RL_CAN_DET_RANGE_RATE_011 MRR_RL_CAN_DET_AMPLITUDE_009 MRR_RL_CAN_DET_VALID_LEVEL_011 MRR_RL_CAN_DET_CONFID_ELEVA_0052 MRR_RL_CAN_DET_ELEVATION_008 MRR_RL_CAN_DET_SUPER_RES_TA_0053 MRR_RL_CAN_SCAN_INDEX_2LSB_011 MRR_RL_CAN_DET_CONFID_AZIMU_0047 MRR_RL_CAN_DET_CONFID_AZIMU_0048 MRR_RL_CAN_DET_RANGE_RATE_010 MRR_RL_CAN_DET_AZIMUTH_012 MRR_RL_CAN_SCAN_INDEX_2LSB_012 MRR_RL_CAN_DET_RANGE_RATE_012 MRR_RL_CAN_DET_AZIMUTH_010 MRR_RL_CAN_DET_SUPER_RES_TA_0052 MRR_RL_CAN_DET_RANGE_012 MRR_RL_CAN_SCAN_INDEX_2LSB_010 MRR_RL_CAN_DET_AMPLITUDE_014 MRR_RL_CAN_SCAN_INDEX_2LSB_013 MRR_RL_CAN_DET_CONFID_AZIMU_0045 MRR_RL_CAN_DET_ELEVATION_013 MRR_RL_CAN_SCAN_INDEX_2LSB_014 MRR_RL_CAN_DET_CONFID_ELEVA_0049 MRR_RL_CAN_DET_CONFID_ELEVA_0050 MRR_RL_CAN_DET_HOST_VEH_CLU_0050 MRR_RL_CAN_DET_SUPER_RES_TA_0050 MRR_RL_CAN_DET_VALID_LEVEL_014 MRR_RL_CAN_DET_CONFID_AZIMU_0044 MRR_RL_CAN_DET_SUPER_RES_TA_0049 MRR_RL_DET_CRC_002;
SIG_GROUP_ 323 MRR_RL_Alignment_Status 1 : MRR_RL_Alignment_Status_CRC MRR_RL_Alignment_Status_MC MRR_RL_CAN_TX_Temperature MRR_RL_CAN_TX_YAW_RATE_BIAS MRR_RL_CAN_TX_VEH_SPD_COMP_FACTO MRR_RL_CAN_TX_DRIVING_ENVIRONMEN MRR_RL_CAN_TX_Alignment_MODE MRR_RL_CAN_TX_AUTO_ALIGN_QUA_FAC MRR_RL_CAN_TX_ROLLING_COUNT_1 MRR_RL_CAN_TX_CURRENT_MISALIGN_A MRR_RL_CAN_TX_SAVED_MISALIGN_ANG;
SIG_GROUP_ 1346 MRR_Radar_Cfg_Parameters 1 : SensorCfg_MRRFR_Orientation SensorCfg_MRRFL_Orientation SensorCfg_MRRRR_Orientation SensorCfg_MRRRL_Orientation SensorCfg_MRRFR_Yaw SensorCfg_MRRFL_Yaw SensorCfg_MRRRR_Yaw SensorCfg_MRRRL_Yaw SensorCfg_MRRFR_VertPos SensorCfg_MRRFL_VertPos SensorCfg_MRRRR_VertPos SensorCfg_MRRRL_VertPos SensorCfg_MRRFR_LongPos SensorCfg_MRRFL_LongPos SensorCfg_MRRRR_LongPos SensorCfg_MRRRL_LongPos SensorCfg_MRRFR_LatPos SensorCfg_MRRFL_LatPos SensorCfg_MRRRR_LatPos SensorCfg_MRRRL_LatPos SensorCfg_MRRRL_Pitch SensorCfg_MRRFL_Pitch SensorCfg_MRRRR_Pitch SensorCfg_MRRFR_Pitch MRR_SENSR_CFG_CRC SensorCfg_MRRRL_AlignRngTolHorz SensorCfg_MRRRR_AlignRngTolHorz SensorCfg_MRRFL_AlignRngTolHorz SensorCfg_MRRFR_AlignRngTolHorz SensorCfg_MRRRL_AlignRngTolVert SensorCfg_MRRRR_AlignRngTolVert SensorCfg_MRRFL_AlignRngTolVert SensorCfg_MRRFR_AlignRngTolVert;
SIG_GROUP_ 4 Radar_Trig_Control 1 : Radar_Trig_Control_MC Radar_Trig_Control_CRC CADM_TimeSync_Timer_Count;
SIG_GROUP_ 334 MRR_RL_Status_Radar 1 : MRR_RL_System_Operation_Mode_Sta MRR_RL_Status_Radar_CRC MRR_RL_Status_Radar_MC CAN_Core2_Cpu_Load_MRRRL CAN_Core1_Cpu_Load_MRRRL CAN_Core0_Cpu_Load_MRRRL RadarSensorNotOperational_MRRRL RadarAlignmentOutOfRange_MRRRL RadarBlockageDetected_MRRRL RadarExternalConditionsNotOK_MRR RadarAlignmentIncomplete_MRRRL RadarAlignmentNotStarted_MRRRL;
SIG_GROUP_ 270 MRR_RR_Status_Radar 1 : MRR_RR_System_Operation_Mode_Sta MRR_RR_Status_Radar_CRC MRR_RR_Status_Radar_MC CAN_Core2_Cpu_Load_MRRRR CAN_Core1_Cpu_Load_MRRRR CAN_Core0_Cpu_Load_MRRRR RadarSensorNotOperational_MRRRR RadarAlignmentOutOfRange_MRRRR RadarBlockageDetected_MRRRR RadarExternalConditionsNotO_0000 RadarAlignmentIncomplete_MRRRR RadarAlignmentNotStarted_MRRRR;
SIG_GROUP_ 1280 MRR_RL_Detection_001_007 1 : MRR_RL_CAN_DET_Near_TARGET_001 MRR_RL_CAN_DET_Near_TARGET_002 MRR_RL_CAN_DET_Near_TARGET_003 MRR_RL_CAN_DET_Near_TARGET_004 MRR_RL_CAN_DET_Near_TARGET_005 MRR_RL_CAN_DET_Near_TARGET_006 MRR_RL_CAN_DET_Near_TARGET_007 MRR_RL_CAN_DET_MID_TARGET_001 MRR_RL_CAN_DET_MID_TARGET_002 MRR_RL_CAN_DET_MID_TARGET_003 MRR_RL_CAN_DET_MID_TARGET_004 MRR_RL_CAN_DET_MID_TARGET_005 MRR_RL_CAN_DET_MID_TARGET_006 MRR_RL_CAN_DET_MID_TARGET_007 MRR_RL_DET_CRC_001 MRR_RL_CAN_DET_RANGE_007 MRR_RL_CAN_DET_RANGE_RATE_007 MRR_RL_CAN_DET_HOST_VEH_CLU_0057 MRR_RL_CAN_DET_RANGE_RATE_001 MRR_RL_CAN_DET_AMPLITUDE_001 MRR_RL_CAN_DET_VALID_LEVEL_001 MRR_RL_CAN_DET_AZIMUTH_006 MRR_RL_CAN_DET_RANGE_005 MRR_RL_CAN_DET_RANGE_006 MRR_RL_CAN_DET_RANGE_RATE_005 MRR_RL_CAN_SCAN_INDEX_2LSB_001 MRR_RL_CAN_DET_RANGE_001 MRR_RL_CAN_DET_AZIMUTH_002 MRR_RL_CAN_DET_CONFID_AZIMU_0056 MRR_RL_CAN_DET_VALID_LEVEL_005 MRR_RL_CAN_DET_ELEVATION_001 MRR_RL_CAN_DET_AMPLITUDE_002 MRR_RL_CAN_DET_AZIMUTH_001 MRR_RL_CAN_DET_CONFID_ELEVA_0062 MRR_RL_CAN_DET_VALID_LEVEL_003 MRR_RL_CAN_DET_VALID_LEVEL_002 MRR_RL_CAN_DET_CONFID_ELEVA_0059 MRR_RL_CAN_DET_RANGE_002 MRR_RL_CAN_DET_HOST_VEH_CLU_0060 MRR_RL_CAN_DET_RANGE_RATE_003 MRR_RL_CAN_DET_HOST_VEH_CLU_0059 MRR_RL_CAN_DET_RANGE_004 MRR_RL_CAN_DET_HOST_VEH_CLU_0061 MRR_RL_CAN_DET_ELEVATION_002 MRR_RL_CAN_DET_CONFID_AZIMU_0055 MRR_RL_CAN_DET_SUPER_RES_TA_0059 MRR_RL_CAN_DET_AZIMUTH_004 MRR_RL_CAN_DET_AMPLITUDE_003 MRR_RL_CAN_DET_CONFID_ELEVA_0061 MRR_RL_CAN_DET_SUPER_RES_TA_0062 MRR_RL_CAN_DET_SUPER_RES_TA_0061 MRR_RL_CAN_DET_RANGE_RATE_002 MRR_RL_CAN_DET_CONFID_AZIMU_0054 MRR_RL_CAN_DET_CONFID_AZIMU_0053 MRR_RL_CAN_SCAN_INDEX_2LSB_003 MRR_RL_CAN_DET_HOST_VEH_CLU_0062 MRR_RL_CAN_DET_RANGE_RATE_004 MRR_RL_CAN_DET_RANGE_003 MRR_RL_CAN_DET_ELEVATION_003 MRR_RL_CAN_DET_AZIMUTH_003 MRR_RL_CAN_DET_CONFID_ELEVA_0060 MRR_RL_CAN_DET_AMPLITUDE_004 MRR_RL_CAN_DET_AZIMUTH_005 MRR_RL_CAN_DET_RANGE_RATE_006 MRR_RL_CAN_DET_CONFID_ELEVA_0057 MRR_RL_CAN_SCAN_INDEX_2LSB_007 MRR_RL_CAN_DET_ELEVATION_007 MRR_RL_DET_MC_001 MRR_RL_CAN_DET_SUPER_RES_TA_0056 MRR_RL_CAN_DET_CONFID_ELEVA_0056 MRR_RL_CAN_DET_HOST_VEH_CLU_0056 MRR_RL_CAN_DET_SUPER_RES_TA_0060 MRR_RL_CAN_DET_VALID_LEVEL_004 MRR_RL_CAN_DET_SUPER_RES_TA_0058 MRR_RL_CAN_DET_CONFID_AZIMU_0051 MRR_RL_CAN_SCAN_INDEX_2LSB_006 MRR_RL_CAN_DET_VALID_LEVEL_006 MRR_RL_CAN_DET_CONFID_ELEVA_0058 MRR_RL_CAN_DET_ELEVATION_005 MRR_RL_CAN_DET_AMPLITUDE_006 MRR_RL_CAN_SCAN_INDEX_2LSB_002 MRR_RL_CAN_DET_ELEVATION_004 MRR_RL_CAN_DET_AMPLITUDE_005 MRR_RL_CAN_SCAN_INDEX_2LSB_004 MRR_RL_CAN_SCAN_INDEX_2LSB_005 MRR_RL_CAN_DET_CONFID_AZIMU_0052 MRR_RL_CAN_DET_HOST_VEH_CLU_0058 MRR_RL_CAN_DET_ELEVATION_006 MRR_RL_CAN_DET_VALID_LEVEL_007 MRR_RL_CAN_DET_SUPER_RES_TA_0057 MRR_RL_CAN_DET_AMPLITUDE_007 MRR_RL_CAN_DET_AZIMUTH_007 MRR_RL_CAN_DET_CONFID_AZIMU_0050;
